VERSION ""

NS_ :

BS_:

BU_: ETH

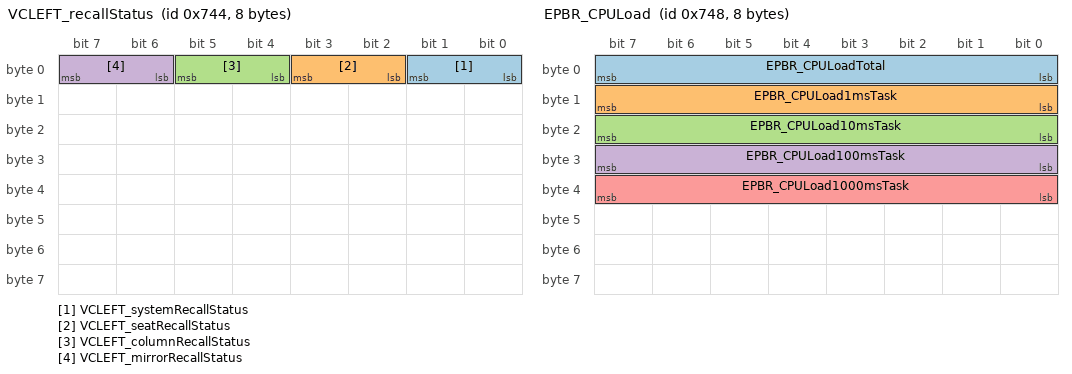
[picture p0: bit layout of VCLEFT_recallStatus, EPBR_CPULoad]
BO_ 1860 VCLEFT_recallStatus: 8 Vector__XXX
 SG_ VCLEFT_systemRecallStatus : 0|2@1+ (1,0) [0|0] "" Vector__XXX
 SG_ VCLEFT_seatRecallStatus : 2|2@1+ (1,0) [0|0] "" Vector__XXX
 SG_ VCLEFT_columnRecallStatus : 4|2@1+ (1,0) [0|0] "" Vector__XXX
 SG_ VCLEFT_mirrorRecallStatus : 6|2@1+ (1,0) [0|0] "" Vector__XXX

BO_ 1863 DBG_vdcControl: 8 Vector__XXX
 SG_ DBG_vdcDebugEnable : 0|1@1+ (1,0) [0|0] "" Vector__XXX

BO_ 1864 EPBR_CPULoad: 8 Vector__XXX
 SG_ EPBR_CPULoadTotal : 0|8@1+ (1,0) [0|0] "" Vector__XXX
 SG_ EPBR_CPULoad1msTask : 8|8@1+ (1,0) [0|0] "" Vector__XXX
 SG_ EPBR_CPULoad10msTask : 16|8@1+ (1,0) [0|0] "" Vector__XXX
 SG_ EPBR_CPULoad100msTask : 24|8@1+ (1,0) [0|0] "" Vector__XXX
 SG_ EPBR_CPULoad1000msTask : 32|8@1+ (1,0) [0|0] "" Vector__XXX

BO_ 1870 XCP_pmRequest: 8 Vector__XXX
 SG_ XCP_pmRequestData : 7|64@0+ (1,0) [0|0] "" Vector__XXX

BO_ 1871 PM_xcpResponse: 8 Vector__XXX
 SG_ PM_xcpResponseData : 7|64@0+ (1,0) [0|0] "" Vector__XXX

BO_ 1872 XCP_vcbattRequest: 8 Vector__XXX
 SG_ XCP_vcbattRequestData : 0|64@1+ (1,0) [0|0] "" Vector__XXX

BO_ 1873 XCP_vcbatt1Request: 8 Vector__XXX
 SG_ XCP_vcbatt1RequestData : 0|64@1+ (1,0) [0|0] "" Vector__XXX

BO_ 1874 BMS_debugInfo_100Hz: 8 Vector__XXX
 SG_ BMS_100HzDebug_Id M : 0|6@1+ (1,0) [0|0] "" Vector__XXX
 SG_ BMS_dbgLoadReg_output m2 : 6|11@1- (0.1,0) [0|0] "" Vector__XXX
 SG_ BMS_dbgSmWeldRequest m3 : 6|1@1+ (1,0) [0|0] "" Vector__XXX
 SG_ BMS_energyVoltageFloorReached m4 : 6|1@1+ (1,0) [0|0] "" Vector__XXX
 SG_ BMS_dbgSmChgModuleBlockingTrans m3 : 7|1@1+ (1,0) [0|0] "" Vector__XXX
 SG_ BMS_energyPowerTargetReached m4 : 7|1@1+ (1,0) [0|0] "" Vector__XXX
 SG_ BMS_brickOcvAvg m9 : 8|12@1+ (0.002,0) [0|0] "" Vector__XXX
 SG_ BMS_dbgCurrentReg_outIntegral m1 : 8|14@1- (0.1,0) [0|0] "" Vector__XXX
 SG_ BMS_dbgHvsTxErrorCount m6 : 8|8@1+ (1,0) [0|0] "" Vector__XXX
 SG_ BMS_dbgSmChargeCablePresent m3 : 8|1@1+ (1,0) [0|0] "" Vector__XXX
 SG_ BMS_dbgVoltageReg_Kp m0 : 8|9@1+ (5,0) [0|0] "" Vector__XXX
 SG_ BMS_energySimulationWalk m11 : 8|3@1+ (1,0) [0|0] "" Vector__XXX
 SG_ BMS_energySimulationWalkTime m10 : 8|14@1+ (0.1,0) [0|0] "" Vector__XXX
 SG_ BMS_energyWalkDone m4 : 8|1@1+ (1,0) [0|0] "" Vector__XXX
 SG_ BMS_energyWalkLoadedPackV m5 : 8|9@1+ (1,0) [0|0] "" Vector__XXX
 SG_ BMS_maxDeviationBrickId m12 : 8|8@1+ (1,1) [0|0] "" Vector__XXX
 SG_ BMS_measuredImpedanceNoise m13 : 8|12@1+ (0.001,0) [0|0] "" Vector__XXX
 SG_ BMS_socByDvStartPtInitialized m7 : 8|1@1+ (1,0) [0|0] "" Vector__XXX
 SG_ BMS_voltageInstabilityPresent m8 : 8|1@1+ (1,0) [0|0] "" Vector__XXX
 SG_ BMS_dbgSmChargeRequestActive m3 : 9|1@1+ (1,0) [0|0] "" Vector__XXX
 SG_ BMS_energySocLimitReached m4 : 9|1@1+ (1,0) [0|0] "" Vector__XXX
 SG_ BMS_socByDvStartCcv m7 : 9|12@1+ (0.002,0) [0|0] "" Vector__XXX
 SG_ BMS_voltageInstabilityFiltMedianCnts m8 : 9|12@1+ (0.1,0) [0|0] "" Vector__XXX
 SG_ BMS_dbgSmChargerActive m3 : 10|1@1+ (1,0) [0|0] "" Vector__XXX
 SG_ BMS_energyNotEnoughPower m4 : 10|1@1+ (1,0) [0|0] "" Vector__XXX
 SG_ BMS_dbgSmBmsWantsToCharge m3 : 11|1@1+ (1,0) [0|0] "" Vector__XXX
 SG_ BMS_energyTargetReached m4 : 11|1@1+ (1,0) [0|0] "" Vector__XXX
 SG_ BMS_dbgChargeState m3 : 12|4@1+ (1,0) [0|0] "" Vector__XXX
 SG_ BMS_energyWalkTimedOut m4 : 12|1@1+ (1,0) [0|0] "" Vector__XXX
 SG_ BMS_energyWalkId m4 : 13|3@1+ (1,0) [0|0] "" Vector__XXX
 SG_ BMS_dbgChargeNeeded m3 : 16|1@1+ (1,0) [0|0] "" Vector__XXX
 SG_ BMS_dbgHvsRxErrorCount m6 : 16|8@1+ (1,0) [0|0] "" Vector__XXX
 SG_ BMS_energyWalkTime m4 : 16|10@1+ (0.01,0) [0|0] "" Vector__XXX
 SG_ BMS_maxDeviationBrickImpedance m12 : 16|12@1+ (0.01,0) [0|0] "" Vector__XXX
 SG_ BMS_dbgOffsetReg_output m2 : 17|14@1- (0.1,0) [0|0] "" Vector__XXX
 SG_ BMS_dbgSmStateSupportRequired m3 : 17|1@1+ (1,0) [0|0] "" Vector__XXX
 SG_ BMS_dbgVoltageReg_Ki m0 : 17|11@1+ (1,0) [0|0] "" Vector__XXX
 SG_ BMS_energyWalkPackCurrent m5 : 17|15@1- (0.1,1000) [0|0] "" Vector__XXX
 SG_ BMS_dbgSmDriveActive m3 : 18|1@1+ (1,0) [0|0] "" Vector__XXX
 SG_ BMS_dbgFeimBlocking m3 : 19|1@1+ (1,0) [0|0] "" Vector__XXX
 SG_ BMS_brickOcvMax m9 : 20|12@1+ (0.002,0) [0|0] "" Vector__XXX
 SG_ BMS_dbgUdsCtrControlActive m3 : 20|1@1+ (1,0) [0|0] "" Vector__XXX
 SG_ BMS_normalizedDcrNoise m13 : 20|10@1+ (0.001,0) [0|0] "" Vector__XXX
 SG_ BMS_dbgEnoughPowerForSupport m3 : 21|1@1+ (1,0) [0|0] "" Vector__XXX
 SG_ BMS_socByDvStartCurrent m7 : 21|10@1- (1,0) [0|0] "" Vector__XXX
 SG_ BMS_voltageDiffPerSMax m8 : 21|11@1+ (0.00244140625,-2.5) [0|0] "" Vector__XXX
 SG_ BMS_chargeEnergyPackCurrent m10 : 24|13@1- (1,1000) [0|0] "" Vector__XXX
 SG_ BMS_dbgCurrentReg_outProp m1 : 24|14@1- (0.1,0) [0|0] "" Vector__XXX
 SG_ BMS_dbgHvsFaultConfinement m6 : 24|2@1+ (1,0) [0|0] "" Vector__XXX
 SG_ BMS_fcLinkLeakageTestStatus m3 : 24|3@1+ (1,0) [0|0] "" Vector__XXX
 SG_ BMS_dbgHvsBusIsOff m6 : 26|1@1+ (1,0) [0|0] "" Vector__XXX
 SG_ BMS_walkEnergy m4 : 26|11@1+ (0.1,0) [0|0] "" Vector__XXX
 SG_ BMS_dbgHvsGoToSleep m6 : 27|1@1+ (1,0) [0|0] "" Vector__XXX
 SG_ BMS_minTetheredLoadPresent m3 : 27|1@1+ (1,0) [0|0] "" Vector__XXX
 SG_ BMS_avgBrickImpedance m12 : 28|12@1+ (0.01,0) [0|0] "" Vector__XXX
 SG_ BMS_dbgVoltageReg_error m0 : 28|12@1- (0.00122,0) [0|0] "" Vector__XXX
 SG_ BMS_smHvUpRequestAllowed m3 : 28|1@1+ (1,0) [0|0] "" Vector__XXX
 SG_ BMS_fcCtrCleaningDesired m3 : 29|1@1+ (1,0) [0|0] "" Vector__XXX
 SG_ BMS_fcCtrCleaningAllowed m3 : 30|1@1+ (1,0) [0|0] "" Vector__XXX
 SG_ BMS_rawImpedanceDeviation m13 : 30|10@1+ (0.001,0) [0|0] "" Vector__XXX
 SG_ BMS_fcCtrCleaningActive m3 : 31|1@1+ (1,0) [0|0] "" Vector__XXX
 SG_ BMS_socByDvNetAh m7 : 31|9@1+ (0.002,0) [0|0] "" Vector__XXX
 SG_ BMS_brickOcvMin m9 : 32|12@1+ (0.002,0) [0|0] "" Vector__XXX
 SG_ BMS_dbgChargeNeededState m2 : 32|3@1+ (1,0) [0|0] "" Vector__XXX
 SG_ BMS_dbgHviTxErrorCount m6 : 32|8@1+ (1,0) [0|0] "" Vector__XXX
 SG_ BMS_energyWalkPackResistance m5 : 32|10@1+ (0.1,0) [0|0] "" Vector__XXX
 SG_ BMS_fcCtrCleaningPosCount m3 : 32|6@1+ (1,0) [0|0] "" Vector__XXX
 SG_ BMS_voltageInstabilityFltExcessNoise m8 : 32|12@1+ (0.1,0) [0|0] "" Vector__XXX
 SG_ BMS_dbgMaxDcCurrentAvailable m2 : 35|11@1+ (0.5,0) [0|0] "" Vector__XXX
 SG_ BMS_energyMaxBrickTemp m10 : 37|9@1+ (0.25,-25) [0|0] "" Vector__XXX
 SG_ BMS_energyWalkAhRemaining m4 : 37|12@1+ (0.1,0) [0|0] "" Vector__XXX
 SG_ BMS_dbgCurrentReg_error m1 : 40|12@1- (0.1,0) [0|0] "" Vector__XXX
 SG_ BMS_dbgHviRxErrorCount m6 : 40|8@1+ (1,0) [0|0] "" Vector__XXX
 SG_ BMS_dbgPeakRegenCurrentLimitMode m7 : 40|4@1+ (1,0) [0|0] "" Vector__XXX
 SG_ BMS_dbgVoltageReg_output m0 : 40|12@1- (0.5,0) [0|0] "" Vector__XXX
 SG_ BMS_fcCtrCleaningNegCount m3 : 40|6@1+ (1,0) [0|0] "" Vector__XXX
 SG_ BMS_missingCellExcessCurrentGain m13 : 40|8@1+ (0.05,0) [0|0] "" Vector__XXX
 SG_ BMS_snapshot1MaxVoltage m12 : 40|10@1+ (0.005,0) [0|0] "" Vector__XXX
 SG_ BMS_brickOcvSum m9 : 44|10@1+ (0.5,0) [0|0] "" Vector__XXX
 SG_ BMS_dbgDischargeCurrentLimitMode m7 : 44|4@1+ (1,0) [0|0] "" Vector__XXX
 SG_ BMS_voltageInstabilityMaxRawCnts m8 : 44|12@1+ (1,0) [0|0] "" Vector__XXX
 SG_ BMS_brickVoltagesClean m3 : 46|1@1+ (1,0) [0|0] "" Vector__XXX
 SG_ BMS_dbgCurrentReg_targetI m2 : 46|11@1+ (0.5,0) [0|0] "" Vector__XXX
 SG_ BMS_energyMinBrickTemp m10 : 46|9@1+ (0.25,-25) [0|0] "" Vector__XXX
 SG_ BMS_chargeSourcePresent m3 : 47|1@1+ (1,0) [0|0] "" Vector__XXX
 SG_ BMS_dbgHviFaultConfinement m6 : 48|2@1+ (1,0) [0|0] "" Vector__XXX
 SG_ BMS_energyWalkPackTemp m5 : 48|8@1- (1,40) [0|0] "" Vector__XXX
 SG_ BMS_missingCellImpedanceDeviation m13 : 48|10@1+ (0.001,0) [0|0] "" Vector__XXX
 SG_ BMS_energyWalkPackSoc m4 : 49|10@1+ (0.1,0) [0|0] "" Vector__XXX
 SG_ BMS_dbgHviBusIsOff m6 : 50|1@1+ (1,0) [0|0] "" Vector__XXX
 SG_ BMS_impedanceDevDeltaCurrent m12 : 50|12@1+ (1,-3000) [0|0] "" Vector__XXX
 SG_ BMS_instantPowerDissipation m9 : 54|10@1+ (0.25,0) [0|0] "" Vector__XXX
 SG_ BMS_energyCoolantOutletTemp m10 : 56|8@1+ (1,-50) [0|0] "" Vector__XXX
 SG_ BMS_voltageInstabilityMaxBrickVNumber m8 : 56|7@1+ (1,0) [0|0] "" Vector__XXX
 SG_ BMS_dbgCpUserChargeStatus m2 : 57|3@1+ (1,0) [0|0] "" Vector__XXX
 SG_ BMS_energyCounter m4 : 59|4@1+ (1,0) [0|0] "" Vector__XXX

BO_ 1875 XCP_vcrightRequest: 8 Vector__XXX
 SG_ XCP_vcrightRequestData : 7|64@0+ (1,0) [0|0] "" Vector__XXX

BO_ 1876 XCP_vcfrontRequest: 8 Vector__XXX
 SG_ XCP_vcfrontRequestData : 7|64@0+ (1,0) [0|0] "" Vector__XXX

BO_ 1877 XCP_vcsecRequest: 8 Vector__XXX
 SG_ XCP_vcsecRequestData : 7|64@0+ (1,0) [0|0] "" Vector__XXX

BO_ 1878 XCP_vcleftRequest: 8 Vector__XXX
 SG_ XCP_vcleftRequestData : 7|64@0+ (1,0) [0|0] "" Vector__XXX

BO_ 1879 DIF_debug: 8 Vector__XXX
 SG_ DIF_debugSelector M : 0|8@1+ (1,0) [0|0] "" Vector__XXX
 SG_ DIF_cpu10HzMin m66 : 8|8@1+ (0.4,0) [0|0] "" Vector__XXX
 SG_ DIF_cpu1HzMin m128 : 8|8@1+ (0.4,0) [0|0] "" Vector__XXX
 SG_ DIF_cpu1kHzMin m67 : 8|8@1+ (0.4,0) [0|0] "" Vector__XXX
 SG_ DIF_dcCapTemp m64 : 8|8@1+ (1,-40) [0|0] "" Vector__XXX
 SG_ DIF_gainScale m37 : 8|8@1+ (0.01,0) [0|0] "" Vector__XXX
 SG_ DIF_hwFaultCount m69 : 8|4@1+ (1,0) [0|0] "" Vector__XXX
 SG_ DIF_latchFeedback m50 : 8|1@1+ (1,0) [0|0] "" Vector__XXX
 SG_ DIF_lmScale m36 : 8|8@1+ (0.004,0) [0|0] "" Vector__XXX
 SG_ DIF_motorIA m32 : 8|16@1+ (0.1,0) [0|0] "" Vector__XXX
 SG_ DIF_offsetA m44 : 8|6@1- (0.763,0) [0|0] "" Vector__XXX
 SG_ DIF_oilPumpMotorSpeed m46 : 8|8@1+ (40,0) [0|0] "" Vector__XXX
 SG_ DIF_phaseOutBusbarTemp m70 : 8|8@1+ (1,-40) [0|0] "" Vector__XXX
 SG_ DIF_resolverOffsetCos m48 : 8|8@1+ (0.015,0) [0|0] "" Vector__XXX
 SG_ DIF_rotorOffsetEst m43 : 8|12@1- (0.01,0) [0|0] "" Vector__XXX
 SG_ DIF_rsScale m34 : 8|8@1+ (0.01,0) [0|0] "" Vector__XXX
 SG_ DIF_soptTimeToTrip m49 : 8|8@1+ (0.05,0) [0|0] "" Vector__XXX
 SG_ DIF_statorEndWindingTemp m72 : 8|8@1+ (1,-40) [0|0] "" Vector__XXX
 SG_ DIF_statorIDref m33 : 8|16@1- (0.1,0) [0|0] "" Vector__XXX
 SG_ DIF_systemStack m68 : 8|8@1+ (0.4,0) [0|0] "" Vector__XXX
 SG_ DIF_tqSatThermal m39 : 8|8@1+ (0.4,0) [0|0] "" Vector__XXX
 SG_ DIF_tqScaleDifferential m35 : 8|8@1+ (0.4,0) [0|0] "" Vector__XXX
 SG_ DIF_mechssLatchesActive m50 : 9|1@1+ (1,0) [0|0] "" Vector__XXX
 SG_ DIF_usmState m38 : 12|3@1+ (1,0) [0|0] "" Vector__XXX
 SG_ DIF_busbarTemp m64 : 16|8@1+ (1,-40) [0|0] "" Vector__XXX
 SG_ DIF_cpu10HzAvg m66 : 16|8@1+ (0.4,0) [0|0] "" Vector__XXX
 SG_ DIF_cpu1HzAvg m128 : 16|8@1+ (0.4,0) [0|0] "" Vector__XXX
 SG_ DIF_cpu1kHzAvg m67 : 16|8@1+ (0.4,0) [0|0] "" Vector__XXX
 SG_ DIF_cpuIDWord0 m131 : 16|16@1+ (1,0) [0|0] "" Vector__XXX
 SG_ DIF_cpuIDWord1 m132 : 16|16@1+ (1,0) [0|0] "" Vector__XXX
 SG_ DIF_idleStack m68 : 16|8@1+ (0.4,0) [0|0] "" Vector__XXX
 SG_ DIF_lvBoostedRail m50 : 16|8@1+ (0.08,0) [0|0] "" Vector__XXX
 SG_ DIF_offsetB m44 : 16|6@1- (0.763,0) [0|0] "" Vector__XXX
 SG_ DIF_oilPumpPhaseVoltage m46 : 16|8@1+ (0.3,0) [0|0] "" Vector__XXX
 SG_ DIF_peakIQref m38 : 16|16@1+ (0.1,0) [0|0] "" Vector__XXX
 SG_ DIF_phaseOutBusbarWeldTemp m70 : 16|8@1+ (1,-40) [0|0] "" Vector__XXX
 SG_ DIF_resolverCosRmsSquared m52 : 16|8@1+ (0.005,0) [0|0] "" Vector__XXX
 SG_ DIF_resolverOffsetSin m48 : 16|8@1+ (0.015,0) [0|0] "" Vector__XXX
 SG_ DIF_rotorFlux m47 : 16|16@1+ (0.0001,0) [0|0] "" Vector__XXX
 SG_ DIF_rotorMaxMagnetTemp m72 : 16|8@1+ (1,-40) [0|0] "" Vector__XXX
 SG_ DIF_soptTripDelay m49 : 16|8@1+ (0.05,0) [0|0] "" Vector__XXX
 SG_ DIF_statorFluxRef m35 : 16|16@1+ (0.0001,0) [0|0] "" Vector__XXX
 SG_ DIF_statorIQref m34 : 16|16@1- (0.1,0) [0|0] "" Vector__XXX
 SG_ DIF_statorVDFiltered m63 : 16|16@1- (4e-05,0) [0|0] "" Vector__XXX
 SG_ DIF_statorVQ m36 : 16|16@1- (4e-05,0) [0|0] "" Vector__XXX
 SG_ DIF_tcMaxRequest m40 : 16|8@1+ (5,0) [0|0] "" Vector__XXX
 SG_ DIF_rotorOffsetMean m43 : 20|12@1- (0.01,0) [0|0] "" Vector__XXX
 SG_ DIF_activeDischargeRail m50 : 24|8@1+ (0.3,0) [0|0] "" Vector__XXX
 SG_ DIF_cpu100HzMin m66 : 24|8@1+ (0.4,0) [0|0] "" Vector__XXX
 SG_ DIF_cpu20kHzMin m67 : 24|8@1+ (0.4,0) [0|0] "" Vector__XXX
 SG_ DIF_decodeHardwareStack m68 : 24|8@1+ (0.4,0) [0|0] "" Vector__XXX
 SG_ DIF_lightSenseV m72 : 24|6@1+ (0.1,0) [0|0] "" Vector__XXX
 SG_ DIF_llsScale m42 : 24|8@1+ (0.004,0) [0|0] "" Vector__XXX
 SG_ DIF_motorIB m32 : 24|16@1+ (0.1,0) [0|0] "" Vector__XXX
 SG_ DIF_oilPumpPressureEstimateMax m46 : 24|8@1+ (2,0) [0|0] "" Vector__XXX
 SG_ DIF_pcsTemp m64 : 24|8@1+ (1,-40) [0|0] "" Vector__XXX
 SG_ DIF_phaseOutLugTemp m70 : 24|8@1+ (1,-40) [0|0] "" Vector__XXX
 SG_ DIF_resolverPhaseOffset m48 : 24|8@1+ (0.4,0) [0|0] "" Vector__XXX
 SG_ DIF_resolverSinRmsSquared m52 : 24|8@1+ (0.005,0) [0|0] "" Vector__XXX
 SG_ DIF_soptTimeToOff m49 : 24|11@1+ (0.05,0) [0|0] "" Vector__XXX
 SG_ DIF_statorIDfdb m33 : 24|16@1- (0.1,0) [0|0] "" Vector__XXX
 SG_ DIF_tcMinRequest m40 : 24|8@1+ (5,0) [0|0] "" Vector__XXX
 SG_ DIF_pyroSenseV m72 : 30|8@1+ (0.02,0) [0|0] "" Vector__XXX
 SG_ DIF_cpu100HzAvg m66 : 32|8@1+ (0.4,0) [0|0] "" Vector__XXX
 SG_ DIF_cpu20kHzAvg m67 : 32|8@1+ (0.4,0) [0|0] "" Vector__XXX
 SG_ DIF_cpuIDWord2 m132 : 32|16@1+ (1,0) [0|0] "" Vector__XXX
 SG_ DIF_crc m131 : 32|32@1+ (1,0) [0|0] "" Vector__XXX
 SG_ DIF_dcCableHeat m47 : 32|16@1+ (0.001,0) [0|0] "" Vector__XXX
 SG_ DIF_dcLinkCapTemp m70 : 32|8@1+ (1,-40) [0|0] "" Vector__XXX
 SG_ DIF_driveUnitOdometer m69 : 32|32@1+ (10,0) [0|0] "" Vector__XXX
 SG_ DIF_eepromStack m68 : 32|8@1+ (0.4,0) [0|0] "" Vector__XXX
 SG_ DIF_llrScale m42 : 32|8@1+ (0.015,0) [0|0] "" Vector__XXX
 SG_ DIF_loadAngleMargin m37 : 32|16@1- (0.0003,0) [0|0] "" Vector__XXX
 SG_ DIF_motorIAavg m38 : 32|16@1- (0.1,0) [0|0] "" Vector__XXX
 SG_ DIF_oilPumpPressureExpectedMin m46 : 32|8@1+ (2,0) [0|0] "" Vector__XXX
 SG_ DIF_preregulatorRail m50 : 32|8@1+ (0.15,0) [0|0] "" Vector__XXX
 SG_ DIF_resolverCommonGain m48 : 32|8@1+ (0.025,0) [0|0] "" Vector__XXX
 SG_ DIF_resolverCosFiltered m52 : 32|8@1- (0.01,0) [0|0] "" Vector__XXX
 SG_ DIF_statorFluxFdb m35 : 32|16@1+ (0.0001,0) [0|0] "" Vector__XXX
 SG_ DIF_statorIQfdb m34 : 32|16@1- (0.1,0) [0|0] "" Vector__XXX
 SG_ DIF_statorTemp1 m64 : 32|8@1+ (1,-40) [0|0] "" Vector__XXX
 SG_ DIF_statorVD m36 : 32|16@1- (4e-05,0) [0|0] "" Vector__XXX
 SG_ DIF_statorVQFiltered m63 : 32|16@1- (4e-05,0) [0|0] "" Vector__XXX
 SG_ DIF_tqSatMotorVoltage m39 : 32|8@1+ (0.4,0) [0|0] "" Vector__XXX
 SG_ DIF_wasteCurrentLimit m41 : 32|16@1+ (0.1,0) [0|0] "" Vector__XXX
 SG_ DIF_controlStack m67 : 40|8@1+ (0.4,0) [0|0] "" Vector__XXX
 SG_ DIF_cpu10msMin m66 : 40|8@1+ (0.4,0) [0|0] "" Vector__XXX
 SG_ DIF_hvDcCableTemp m70 : 40|8@1+ (1,-40) [0|0] "" Vector__XXX
 SG_ DIF_loadAngle m42 : 40|16@1- (0.0003,0) [0|0] "" Vector__XXX
 SG_ DIF_motorIC m32 : 40|16@1+ (0.1,0) [0|0] "" Vector__XXX
 SG_ DIF_resolverReady m48 : 40|1@1+ (1,0) [0|0] "" Vector__XXX
 SG_ DIF_resolverSinFiltered m52 : 40|8@1- (0.01,0) [0|0] "" Vector__XXX
 SG_ DIF_soptMaxCurrentMagSqrd m49 : 40|16@1+ (100,0) [0|0] "" Vector__XXX
 SG_ DIF_statorTemp2 m64 : 40|8@1+ (1,-40) [0|0] "" Vector__XXX
 SG_ DIF_torquePerAmp m33 : 40|16@1+ (0.0001,0) [0|0] "" Vector__XXX
 SG_ DIF_tqSatMotorCurrent m39 : 40|8@1+ (0.4,0) [0|0] "" Vector__XXX
 SG_ DIF_udsStack m68 : 40|8@1+ (0.4,0) [0|0] "" Vector__XXX
 SG_ DIF_resolverNoCarrier m48 : 41|1@1+ (1,0) [0|0] "" Vector__XXX
 SG_ DIF_resolverNoPhaseLock m48 : 42|1@1+ (1,0) [0|0] "" Vector__XXX
 SG_ DIF_resolverClaMIA m48 : 43|1@1+ (1,0) [0|0] "" Vector__XXX
 SG_ DIF_statorSlotWindingTemp m72 : 46|8@1+ (1,-40) [0|0] "" Vector__XXX
 SG_ DIF_cpuIDWord3 m132 : 48|16@1+ (1,0) [0|0] "" Vector__XXX
 SG_ DIF_internalAngleFilt m37 : 48|16@1+ (0.0003,0) [0|0] "" Vector__XXX
 SG_ DIF_magnetTempEst m47 : 48|8@1+ (1,-40) [0|0] "" Vector__XXX
 SG_ DIF_module10HzStack m66 : 48|8@1+ (0.4,0) [0|0] "" Vector__XXX
 SG_ DIF_motorIBavg m38 : 48|16@1- (0.1,0) [0|0] "" Vector__XXX
 SG_ DIF_motorV m34 : 48|16@1+ (2e-05,0) [0|0] "" Vector__XXX
 SG_ DIF_negDcBusbarTemp m70 : 48|8@1+ (1,-40) [0|0] "" Vector__XXX
 SG_ DIF_peakFlux m36 : 48|16@1+ (0.0001,0) [0|0] "" Vector__XXX
 SG_ DIF_phaseImbalanceFactor m35 : 48|16@1+ (0.0001,0) [0|0] "" Vector__XXX
 SG_ DIF_pwmState m63 : 48|2@1+ (1,0) [0|0] "" Vector__XXX
 SG_ DIF_resolverErrorRmsSquared m52 : 48|8@1+ (0.005,0) [0|0] "" Vector__XXX
 SG_ DIF_tqScaleMaxMotorSpeed m40 : 48|8@1+ (0.4,0) [0|0] "" Vector__XXX
 SG_ DIF_xcpStack m68 : 48|8@1+ (0.4,0) [0|0] "" Vector__XXX
 SG_ DIF_intervalMaxHvBusV m72 : 54|10@1+ (1,0) [0|0] "" Vector__XXX
 SG_ DIF_immobilizerStack m68 : 56|8@1+ (0.4,0) [0|0] "" Vector__XXX
 SG_ DIF_posDcBusbarTemp m70 : 56|8@1+ (1,-40) [0|0] "" Vector__XXX

BO_ 1881 XCP_vcfront1Request: 8 Vector__XXX
 SG_ XCP_vcfront1RequestData : 0|64@1+ (1,0) [0|0] "" Vector__XXX

BO_ 1882 XCP_vcfront2Request: 8 Vector__XXX
 SG_ XCP_vcfront2RequestData : 0|64@1+ (1,0) [0|0] "" Vector__XXX

BO_ 1883 XCP_vcbatt2Request: 8 Vector__XXX
 SG_ XCP_vcbatt2RequestData : 0|64@1+ (1,0) [0|0] "" Vector__XXX

BO_ 1885 CP_loggingFast: 8 Vector__XXX
 SG_ CP_loggingFastSelect M : 0|4@1+ (1,0) [0|0] "" Vector__XXX
 SG_ CP_UHF_controlState m2 : 4|4@1+ (1,0) [0|0] "" Vector__XXX
 SG_ CP_doorPresenceSensorV m3 : 4|12@1+ (0.001221,0) [0|0] "" Vector__XXX
 SG_ CP_inductiveSensor_raw m0 : 4|28@1+ (1,0) [0|0] "" Vector__XXX
 SG_ CP_latchLastEngageRequestMaxV m4 : 4|10@1+ (0.017595307917888565,0) [0|0] "" Vector__XXX
 SG_ CP_latchPot m1 : 4|12@1+ (0.025,0) [0|0] "" Vector__XXX
 SG_ CP_v2xState m5 : 4|3@1+ (1,0) [0|0] "" Vector__XXX
 SG_ CP_proximityV m2 : 8|16@1+ (0.0001,0) [0|0] "" Vector__XXX
 SG_ CP_v2xCommsState m5 : 8|3@1+ (1,0) [0|0] "" Vector__XXX
 SG_ CP_v2xRetryAttempts m5 : 11|4@1+ (1,0) [0|0] "" Vector__XXX
 SG_ CP_latchLastEngageRequestMaxI m4 : 14|10@1+ (0.004887585532746823,0) [0|0] "" Vector__XXX
 SG_ CP_activeV2xBlocker m5 : 16|5@1+ (1,0) [0|0] "" Vector__XXX
 SG_ CP_doorLastRequestMaxI m1 : 16|12@1+ (0.0025,0) [0|0] "" Vector__XXX
 SG_ CP_doorOpenRequest m3 : 16|4@1+ (1,0) [0|0] "" Vector__XXX
 SG_ CP_doorOpenEndOfDriveReason m3 : 20|3@1+ (1,0) [0|0] "" Vector__XXX
 SG_ CP_lastV2xShutdownTrigger m5 : 21|5@1+ (1,0) [0|0] "" Vector__XXX
 SG_ CP_coverClosed m3 : 23|1@1+ (1,0) [0|0] "" Vector__XXX
 SG_ CP_doorCloseEndOfDriveReason m3 : 24|3@1+ (1,0) [0|0] "" Vector__XXX
 SG_ CP_latchLastDisengageRequestMaxV m4 : 24|10@1+ (0.017595307917888565,0) [0|0] "" Vector__XXX
 SG_ CP_proximityV_GBCC1 m2 : 24|14@1+ (0.001,0) [0|0] "" Vector__XXX
 SG_ CP_doorCloseRequest m3 : 27|5@1+ (1,0) [0|0] "" Vector__XXX
 SG_ CP_doorLastRequestMaxV m1 : 28|10@1+ (0.017595307917888565,0) [0|0] "" Vector__XXX
 SG_ CP_doorOpenActuationTime m0 : 32|14@1+ (1,0) [0|0] "" Vector__XXX
 SG_ CP_latchDisengagingTime m3 : 32|10@1+ (1,0) [0|0] "" Vector__XXX
 SG_ CP_latchLastDisengageRequestMaxI m4 : 34|10@1+ (0.004887585532746823,0) [0|0] "" Vector__XXX
 SG_ CP_digitalCommsAttempts m5 : 37|3@1+ (1,0) [0|0] "" Vector__XXX
 SG_ CP_pilotPulseWidth m1 : 38|12@1+ (1,0) [0|0] "" Vector__XXX
 SG_ CP_proximityV_GBCC2 m2 : 38|14@1+ (0.001,0) [0|0] "" Vector__XXX
 SG_ CP_evseGridFormRequestVersion m5 : 40|2@1+ (1,0) [0|0] "" Vector__XXX
 SG_ CP_evseGridFormState m5 : 42|3@1+ (1,0) [0|0] "" Vector__XXX
 SG_ CP_latchEngagingTime m3 : 42|10@1+ (1,0) [0|0] "" Vector__XXX
 SG_ CP_latchLastEngageMaxVelocity m4 : 44|10@1- (8.013698630136986,0) [0|0] "" Vector__XXX
 SG_ CP_evsePilotPowerNeeded m5 : 45|1@1+ (1,0) [0|0] "" Vector__XXX
 SG_ CP_doorCloseActuationTime m0 : 46|14@1+ (1,0) [0|0] "" Vector__XXX
 SG_ CP_v2xAccessoryUpdateWithoutExternalPower m5 : 46|1@1+ (1,0) [0|0] "" Vector__XXX
 SG_ CP_doorPotObserverEstimated m5 : 47|12@1+ (0.025,0) [0|0] "" Vector__XXX
 SG_ CP_pilotPeriod m1 : 50|12@1+ (1,0) [0|0] "" Vector__XXX
 SG_ CP_doorPot m2 : 52|12@1+ (0.025,0) [0|0] "" Vector__XXX
 SG_ CP_latchDisengagingStopReason m3 : 52|3@1+ (1,0) [0|0] "" Vector__XXX
 SG_ CP_latchLastDisengageMaxVelocity m4 : 54|10@1- (8.013698630136986,0) [0|0] "" Vector__XXX
 SG_ CP_latchEngagingStopReason m3 : 56|3@1+ (1,0) [0|0] "" Vector__XXX
 SG_ CP_doorObserverEstimationIsActive m5 : 59|1@1+ (1,0) [0|0] "" Vector__XXX
 SG_ CP_pilotUnlatchRequestActive m3 : 59|1@1+ (1,0) [0|0] "" Vector__XXX
 SG_ CP_chargeCableSecured m0 : 60|1@1+ (1,0) [0|0] "" Vector__XXX
 SG_ CP_doorIdDetectionState m3 : 60|2@1+ (1,0) [0|0] "" Vector__XXX
 SG_ CP_doorPositionSource m5 : 60|2@1+ (1,0) [0|0] "" Vector__XXX
 SG_ CP_chargeCablePresent m0 : 61|1@1+ (1,0) [0|0] "" Vector__XXX
 SG_ CP_doorIdDetectedBin m3 : 62|2@1+ (1,0) [0|0] "" Vector__XXX
 SG_ CP_latchCheckAvailable m0 : 62|1@1+ (1,0) [0|0] "" Vector__XXX
 SG_ CP_proxConn1Sense m1 : 62|1@1+ (1,0) [0|0] "" Vector__XXX
 SG_ CP_proxEn m1 : 63|1@1+ (1,0) [0|0] "" Vector__XXX

BO_ 1886 CHADA_status_2: 8 Vector__XXX
 SG_ CA_status2DataSelect M : 0|7@1+ (1,0) [0|0] "" Vector__XXX
 SG_ CA_status2DummySig : 7|1@1+ (1,0) [0|0] "" Vector__XXX
 SG_ CA_EVSE_Ext_Avail_I_Out m4 : 8|16@1+ (1,0) [0|0] "" Vector__XXX
 SG_ CA_EVSE_Threshold_V m1 : 8|16@1+ (1,0) [0|0] "" Vector__XXX
 SG_ CA_VEH_Ext_Protocol_Ver m0 : 8|8@1+ (1,0) [0|0] "" Vector__XXX
 SG_ CA_vehConnTempDegC m2 : 8|16@1- (0.00457770657,0) [0|0] "" Vector__XXX
 SG_ CA_vehConnTempV m3 : 8|16@1+ (5.035477e-05,0) [0|0] "" Vector__XXX
 SG_ CA_EVSE_Ext_Protocol_Ver m0 : 16|8@1+ (1,0) [0|0] "" Vector__XXX
 SG_ CA_EVSE_Avail_V_Out m1 : 24|16@1+ (1,0) [0|0] "" Vector__XXX
 SG_ CA_EVSE_Eff_Avail_I_Out m4 : 24|16@1+ (1,0) [0|0] "" Vector__XXX
 SG_ CA_FC_protocolVersion m0 : 24|8@1+ (1,0) [0|0] "" Vector__XXX
 SG_ CA_evseConnTempDegC m2 : 24|16@1- (0.00457770657,0) [0|0] "" Vector__XXX
 SG_ CA_evseConnTempV m3 : 24|16@1+ (5.035477e-05,0) [0|0] "" Vector__XXX
 SG_ CA_BMS_protocolVersion m0 : 32|8@1+ (1,0) [0|0] "" Vector__XXX
 SG_ CA_EVSE_Avail_I_Out m1 : 40|8@1+ (1,0) [0|0] "" Vector__XXX
 SG_ CA_VEH_BAT_V_Target m0 : 40|16@1+ (1,0) [0|0] "" Vector__XXX
 SG_ CA_pcbaTempDegC m2 : 40|16@1- (0.01007110813,25) [0|0] "" Vector__XXX
 SG_ CA_pcbaTempV m3 : 40|16@1+ (5.035477e-05,0) [0|0] "" Vector__XXX
 SG_ CA_flybackVoltageLimit m1 : 48|16@1+ (0.01283327338,0) [0|0] "" Vector__XXX
 SG_ CA_VEH_BAT_SOC m0 : 56|8@1+ (0.39215686275,0) [0|0] "" Vector__XXX
 SG_ CA_disableVehicleLimiting m2 : 56|1@1+ (1,0) [0|0] "" Vector__XXX

BO_ 1889 PMF_debug: 8 Vector__XXX
 SG_ PMF_debugSelector M : 0|8@1+ (1,0) [0|0] "" Vector__XXX
 SG_ PMF_Ia m3 : 8|16@1- (0.0939,0) [0|0] "" Vector__XXX
 SG_ PMF_cpu100HzAvg m65 : 8|8@1+ (0.4,0) [0|0] "" Vector__XXX
 SG_ PMF_cpu10kHzMin m66 : 8|8@1+ (0.4,0) [0|0] "" Vector__XXX
 SG_ PMF_cpu1kHzMax m64 : 8|8@1+ (0.4,0) [0|0] "" Vector__XXX
 SG_ PMF_idleStackSize m67 : 8|16@1+ (1,0) [0|0] "" Vector__XXX
 SG_ PMF_offsetIa m5 : 8|12@1- (0.1,0) [0|0] "" Vector__XXX
 SG_ PMF_resolverPhaseAngle m17 : 8|9@1+ (0.001537,0) [0|0] "" Vector__XXX
 SG_ PMF_resolverSpeedError m16 : 8|16@1- (0.75,0) [0|0] "" Vector__XXX
 SG_ PMF_slipFrequency m4 : 8|16@1- (0.005,0) [0|0] "" Vector__XXX
 SG_ PMF_sysStackSize m70 : 8|16@1+ (1,0) [0|0] "" Vector__XXX
 SG_ PMF_torqueDecelWindow m2 : 8|13@1- (2,0) [0|0] "" Vector__XXX
 SG_ PMF_torqueSignError m1 : 8|13@1- (2,0) [0|0] "" Vector__XXX
 SG_ PMF_udsStackSize m68 : 8|16@1+ (1,0) [0|0] "" Vector__XXX
 SG_ PMF_xcpStackSize m69 : 8|16@1+ (1,0) [0|0] "" Vector__XXX
 SG_ PMF_cpu10HzMax m65 : 16|8@1+ (0.4,0) [0|0] "" Vector__XXX
 SG_ PMF_cpu20kHzAvg m64 : 16|8@1+ (0.4,0) [0|0] "" Vector__XXX
 SG_ PMF_resolverCommonGain m17 : 17|7@1+ (0.063,0) [0|0] "" Vector__XXX
 SG_ PMF_offsetIb m5 : 20|12@1- (0.1,0) [0|0] "" Vector__XXX
 SG_ PMF_Ib m3 : 24|16@1- (0.0939,0) [0|0] "" Vector__XXX
 SG_ PMF_cpu10HzAvg m65 : 24|8@1+ (0.4,0) [0|0] "" Vector__XXX
 SG_ PMF_cpu1kHzMin m64 : 24|8@1+ (0.4,0) [0|0] "" Vector__XXX
 SG_ PMF_idleStackMax m67 : 24|16@1+ (1,0) [0|0] "" Vector__XXX
 SG_ PMF_resolverExcitationGain m17 : 24|7@1+ (0.063,0) [0|0] "" Vector__XXX
 SG_ PMF_sysStackMax m70 : 24|16@1+ (1,0) [0|0] "" Vector__XXX
 SG_ PMF_torqueAccelWindow m1 : 24|13@1- (2,0) [0|0] "" Vector__XXX
 SG_ PMF_torqueDecelAvg m2 : 24|13@1- (2,0) [0|0] "" Vector__XXX
 SG_ PMF_udsStackMax m68 : 24|16@1+ (1,0) [0|0] "" Vector__XXX
 SG_ PMF_xcpStackMax m69 : 24|16@1+ (1,0) [0|0] "" Vector__XXX
 SG_ PMF_cpu10HzMin m65 : 32|8@1+ (0.4,0) [0|0] "" Vector__XXX
 SG_ PMF_cpu10kHzAvg m64 : 32|8@1+ (0.4,0) [0|0] "" Vector__XXX
 SG_ PMF_resolverOffsetCos m17 : 32|6@1+ (0.053,0) [0|0] "" Vector__XXX
 SG_ PMF_cpu100HzMax m64 : 40|8@1+ (0.4,0) [0|0] "" Vector__XXX
 SG_ PMF_cpu20kHzMax m65 : 40|8@1+ (0.4,0) [0|0] "" Vector__XXX
 SG_ PMF_iDQmagnitude m3 : 40|16@1- (0.0939,0) [0|0] "" Vector__XXX
 SG_ PMF_motorRPM m4 : 40|16@1- (1,0) [0|0] "" Vector__XXX
 SG_ PMF_resolverOffsetSin m17 : 40|6@1+ (0.053,0) [0|0] "" Vector__XXX
 SG_ PMF_torqueAccelAvg m1 : 40|13@1- (2,0) [0|0] "" Vector__XXX
 SG_ PMF_torqueReversalWindow m2 : 40|13@1- (2,0) [0|0] "" Vector__XXX
 SG_ PMF_switchingActive m5 : 46|1@1+ (1,0) [0|0] "" Vector__XXX
 SG_ PMF_torqueOutOfMap m5 : 47|1@1+ (1,0) [0|0] "" Vector__XXX
 SG_ PMF_cpu1kHzAvg m64 : 48|8@1+ (0.4,0) [0|0] "" Vector__XXX
 SG_ PMF_cpu20kHzMin m65 : 48|8@1+ (0.4,0) [0|0] "" Vector__XXX
 SG_ PMF_resolverOffsetExt m17 : 48|6@1+ (0.053,0) [0|0] "" Vector__XXX
 SG_ PMF_resolverNoCarrier m17 : 54|1@1+ (1,0) [0|0] "" Vector__XXX
 SG_ PMF_resolverPhaseOutOfSpec m17 : 55|1@1+ (1,0) [0|0] "" Vector__XXX
 SG_ PMF_cpu100HzMin m64 : 56|8@1+ (0.4,0) [0|0] "" Vector__XXX
 SG_ PMF_cpu10kHzMax m65 : 56|8@1+ (0.4,0) [0|0] "" Vector__XXX
 SG_ PMF_lmSatCoeff m3 : 56|8@1+ (0.00391,0) [0|0] "" Vector__XXX
 SG_ PMF_resolverClaMIA m17 : 56|1@1+ (1,0) [0|0] "" Vector__XXX
 SG_ PMF_statorT m4 : 56|8@1+ (1,-40) [0|0] "" Vector__XXX
 SG_ PMF_resolverDiMIA m17 : 57|1@1+ (1,0) [0|0] "" Vector__XXX

BO_ 1890 VCLEFT_xcpResponse: 8 Vector__XXX
 SG_ VCLEFT_xcpResponseData : 0|64@1+ (1,0) [0|0] "" Vector__XXX

BO_ 1891 VCRIGHT_xcpResponse: 8 Vector__XXX
 SG_ VCRIGHT_xcpResponseData : 0|64@1+ (1,0) [0|0] "" Vector__XXX

BO_ 1892 VCFRONT_xcpResponse: 8 Vector__XXX
 SG_ VCFRONT_xcpResponseData : 0|64@1+ (1,0) [0|0] "" Vector__XXX

BO_ 1894 DIF_dlogData: 8 Vector__XXX
 SG_ DIF_dlogData : 0|64@1+ (1,0) [0|0] "" Vector__XXX

BO_ 1896 VCBATT_xcpResponse: 8 Vector__XXX
 SG_ VCBATT_xcpResponseData : 0|64@1+ (1,0) [0|0] "" Vector__XXX

BO_ 1897 VCBATT1_xcpResponse: 8 Vector__XXX
 SG_ VCBATT1_xcpResponseData : 0|64@1+ (1,0) [0|0] "" Vector__XXX

BO_ 1898 VCFRONT1_xcpResponse: 8 Vector__XXX
 SG_ VCFRONT1_xcpResponseData : 0|64@1+ (1,0) [0|0] "" Vector__XXX

BO_ 1899 VCFRONT2_xcpResponse: 8 Vector__XXX
 SG_ VCFRONT2_xcpResponseData : 0|64@1+ (1,0) [0|0] "" Vector__XXX

BO_ 1904 VCBATT2_xcpResponse: 8 Vector__XXX
 SG_ VCBATT2_xcpResponseData : 0|64@1+ (1,0) [0|0] "" Vector__XXX

BO_ 1910 XCP_difRequest: 8 Vector__XXX
 SG_ XCP_difRequestData : 7|64@0+ (1,0) [0|0] "" Vector__XXX

BO_ 1911 XCP_diRequest: 8 Vector__XXX
 SG_ XCP_diRequestData : 7|64@0+ (1,0) [0|0] "" Vector__XXX

BO_ 1914 HVP_log1hz: 8 Vector__XXX
 SG_ HVP_log1HzIndex M : 0|3@1+ (1,0) [0|0] "" Vector__XXX
 SG_ HVP_bmbAsicType m0 : 3|2@1+ (1,0) [0|0] "" Vector__XXX
 SG_ HVP_hvilCalType m1 : 3|2@1+ (1,0) [0|0] "" Vector__XXX
 SG_ HVP_gpioPcsDcdcPwmEnable m1 : 5|1@1+ (1,0) [0|0] "" Vector__XXX
 SG_ HVP_gpioPcsChargePwmEnable m1 : 6|1@1+ (1,0) [0|0] "" Vector__XXX
 SG_ HVP_gpioPcsEnable m1 : 7|1@1+ (1,0) [0|0] "" Vector__XXX
 SG_ HVP_shuntAsicChipWaferNumber m1 : 8|8@1+ (1,0) [0|0] "" Vector__XXX
 SG_ HVP_shuntCurrentAuxLog m0 : 8|24@1- (0.001,0) [0|0] "" Vector__XXX
 SG_ HVP_energyReserveMin m1 : 16|16@1- (0.001,0) [0|0] "" Vector__XXX
 SG_ HVP_energyReserveMax m1 : 32|16@1- (0.001,0) [0|0] "" Vector__XXX
 SG_ HVP_pyroSquibResistance m0 : 32|16@1+ (0.001,0) [0|0] "" Vector__XXX
 SG_ HVP_energyReserveAvg m1 : 48|16@1- (0.001,0) [0|0] "" Vector__XXX
 SG_ HVP_shuntAsicChipXCoordinate m0 : 48|8@1+ (1,0) [0|0] "" Vector__XXX
 SG_ HVP_shuntAsicChipYCoordinate m0 : 56|8@1+ (1,0) [0|0] "" Vector__XXX

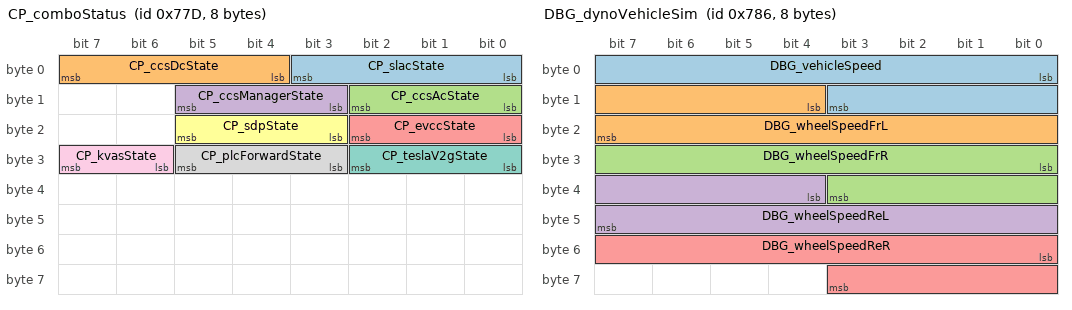
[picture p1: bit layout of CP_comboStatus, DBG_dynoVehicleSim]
BO_ 1917 CP_comboStatus: 8 Vector__XXX
 SG_ CP_slacState : 0|4@1+ (1,0) [0|0] "" Vector__XXX
 SG_ CP_ccsDcState : 4|4@1+ (1,0) [0|0] "" Vector__XXX
 SG_ CP_ccsAcState : 8|3@1+ (1,0) [0|0] "" Vector__XXX
 SG_ CP_ccsManagerState : 11|3@1+ (1,0) [0|0] "" Vector__XXX
 SG_ CP_evccState : 16|3@1+ (1,0) [0|0] "" Vector__XXX
 SG_ CP_sdpState : 19|3@1+ (1,0) [0|0] "" Vector__XXX
 SG_ CP_teslaV2gState : 24|3@1+ (1,0) [0|0] "" Vector__XXX
 SG_ CP_plcForwardState : 27|3@1+ (1,0) [0|0] "" Vector__XXX
 SG_ CP_kvasState : 30|2@1+ (1,0) [0|0] "" Vector__XXX

BO_ 1922 BMS_log3: 8 Vector__XXX
 SG_ BMS_log3MuxId M : 0|8@1+ (1,0) [0|0] "" Vector__XXX
 SG_ BMS_dSocAlphaBrick1 m0 : 8|14@1- (0.0030517578125,0) [0|0] "" Vector__XXX
 SG_ BMS_dSocAlphaBrick10 m9 : 8|14@1- (0.0030517578125,0) [0|0] "" Vector__XXX
 SG_ BMS_dSocAlphaBrick100 m99 : 8|14@1- (0.0030517578125,0) [0|0] "" Vector__XXX
 SG_ BMS_dSocAlphaBrick101 m100 : 8|14@1- (0.0030517578125,0) [0|0] "" Vector__XXX
 SG_ BMS_dSocAlphaBrick102 m101 : 8|14@1- (0.0030517578125,0) [0|0] "" Vector__XXX
 SG_ BMS_dSocAlphaBrick103 m102 : 8|14@1- (0.0030517578125,0) [0|0] "" Vector__XXX
 SG_ BMS_dSocAlphaBrick104 m103 : 8|14@1- (0.0030517578125,0) [0|0] "" Vector__XXX
 SG_ BMS_dSocAlphaBrick105 m104 : 8|14@1- (0.0030517578125,0) [0|0] "" Vector__XXX
 SG_ BMS_dSocAlphaBrick106 m105 : 8|14@1- (0.0030517578125,0) [0|0] "" Vector__XXX
 SG_ BMS_dSocAlphaBrick107 m106 : 8|14@1- (0.0030517578125,0) [0|0] "" Vector__XXX
 SG_ BMS_dSocAlphaBrick108 m107 : 8|14@1- (0.0030517578125,0) [0|0] "" Vector__XXX
 SG_ BMS_dSocAlphaBrick11 m10 : 8|14@1- (0.0030517578125,0) [0|0] "" Vector__XXX
 SG_ BMS_dSocAlphaBrick12 m11 : 8|14@1- (0.0030517578125,0) [0|0] "" Vector__XXX
 SG_ BMS_dSocAlphaBrick13 m12 : 8|14@1- (0.0030517578125,0) [0|0] "" Vector__XXX
 SG_ BMS_dSocAlphaBrick14 m13 : 8|14@1- (0.0030517578125,0) [0|0] "" Vector__XXX
 SG_ BMS_dSocAlphaBrick15 m14 : 8|14@1- (0.0030517578125,0) [0|0] "" Vector__XXX
 SG_ BMS_dSocAlphaBrick16 m15 : 8|14@1- (0.0030517578125,0) [0|0] "" Vector__XXX
 SG_ BMS_dSocAlphaBrick17 m16 : 8|14@1- (0.0030517578125,0) [0|0] "" Vector__XXX
 SG_ BMS_dSocAlphaBrick18 m17 : 8|14@1- (0.0030517578125,0) [0|0] "" Vector__XXX
 SG_ BMS_dSocAlphaBrick19 m18 : 8|14@1- (0.0030517578125,0) [0|0] "" Vector__XXX
 SG_ BMS_dSocAlphaBrick2 m1 : 8|14@1- (0.0030517578125,0) [0|0] "" Vector__XXX
 SG_ BMS_dSocAlphaBrick20 m19 : 8|14@1- (0.0030517578125,0) [0|0] "" Vector__XXX
 SG_ BMS_dSocAlphaBrick21 m20 : 8|14@1- (0.0030517578125,0) [0|0] "" Vector__XXX
 SG_ BMS_dSocAlphaBrick22 m21 : 8|14@1- (0.0030517578125,0) [0|0] "" Vector__XXX
 SG_ BMS_dSocAlphaBrick23 m22 : 8|14@1- (0.0030517578125,0) [0|0] "" Vector__XXX
 SG_ BMS_dSocAlphaBrick24 m23 : 8|14@1- (0.0030517578125,0) [0|0] "" Vector__XXX
 SG_ BMS_dSocAlphaBrick25 m24 : 8|14@1- (0.0030517578125,0) [0|0] "" Vector__XXX
 SG_ BMS_dSocAlphaBrick26 m25 : 8|14@1- (0.0030517578125,0) [0|0] "" Vector__XXX
 SG_ BMS_dSocAlphaBrick27 m26 : 8|14@1- (0.0030517578125,0) [0|0] "" Vector__XXX
 SG_ BMS_dSocAlphaBrick28 m27 : 8|14@1- (0.0030517578125,0) [0|0] "" Vector__XXX
 SG_ BMS_dSocAlphaBrick29 m28 : 8|14@1- (0.0030517578125,0) [0|0] "" Vector__XXX
 SG_ BMS_dSocAlphaBrick3 m2 : 8|14@1- (0.0030517578125,0) [0|0] "" Vector__XXX
 SG_ BMS_dSocAlphaBrick30 m29 : 8|14@1- (0.0030517578125,0) [0|0] "" Vector__XXX
 SG_ BMS_dSocAlphaBrick31 m30 : 8|14@1- (0.0030517578125,0) [0|0] "" Vector__XXX
 SG_ BMS_dSocAlphaBrick32 m31 : 8|14@1- (0.0030517578125,0) [0|0] "" Vector__XXX
 SG_ BMS_dSocAlphaBrick33 m32 : 8|14@1- (0.0030517578125,0) [0|0] "" Vector__XXX
 SG_ BMS_dSocAlphaBrick34 m33 : 8|14@1- (0.0030517578125,0) [0|0] "" Vector__XXX
 SG_ BMS_dSocAlphaBrick35 m34 : 8|14@1- (0.0030517578125,0) [0|0] "" Vector__XXX
 SG_ BMS_dSocAlphaBrick36 m35 : 8|14@1- (0.0030517578125,0) [0|0] "" Vector__XXX
 SG_ BMS_dSocAlphaBrick37 m36 : 8|14@1- (0.0030517578125,0) [0|0] "" Vector__XXX
 SG_ BMS_dSocAlphaBrick38 m37 : 8|14@1- (0.0030517578125,0) [0|0] "" Vector__XXX
 SG_ BMS_dSocAlphaBrick39 m38 : 8|14@1- (0.0030517578125,0) [0|0] "" Vector__XXX
 SG_ BMS_dSocAlphaBrick4 m3 : 8|14@1- (0.0030517578125,0) [0|0] "" Vector__XXX
 SG_ BMS_dSocAlphaBrick40 m39 : 8|14@1- (0.0030517578125,0) [0|0] "" Vector__XXX
 SG_ BMS_dSocAlphaBrick41 m40 : 8|14@1- (0.0030517578125,0) [0|0] "" Vector__XXX
 SG_ BMS_dSocAlphaBrick42 m41 : 8|14@1- (0.0030517578125,0) [0|0] "" Vector__XXX
 SG_ BMS_dSocAlphaBrick43 m42 : 8|14@1- (0.0030517578125,0) [0|0] "" Vector__XXX
 SG_ BMS_dSocAlphaBrick44 m43 : 8|14@1- (0.0030517578125,0) [0|0] "" Vector__XXX
 SG_ BMS_dSocAlphaBrick45 m44 : 8|14@1- (0.0030517578125,0) [0|0] "" Vector__XXX
 SG_ BMS_dSocAlphaBrick46 m45 : 8|14@1- (0.0030517578125,0) [0|0] "" Vector__XXX
 SG_ BMS_dSocAlphaBrick47 m46 : 8|14@1- (0.0030517578125,0) [0|0] "" Vector__XXX
 SG_ BMS_dSocAlphaBrick48 m47 : 8|14@1- (0.0030517578125,0) [0|0] "" Vector__XXX
 SG_ BMS_dSocAlphaBrick49 m48 : 8|14@1- (0.0030517578125,0) [0|0] "" Vector__XXX
 SG_ BMS_dSocAlphaBrick5 m4 : 8|14@1- (0.0030517578125,0) [0|0] "" Vector__XXX
 SG_ BMS_dSocAlphaBrick50 m49 : 8|14@1- (0.0030517578125,0) [0|0] "" Vector__XXX
 SG_ BMS_dSocAlphaBrick51 m50 : 8|14@1- (0.0030517578125,0) [0|0] "" Vector__XXX
 SG_ BMS_dSocAlphaBrick52 m51 : 8|14@1- (0.0030517578125,0) [0|0] "" Vector__XXX
 SG_ BMS_dSocAlphaBrick53 m52 : 8|14@1- (0.0030517578125,0) [0|0] "" Vector__XXX
 SG_ BMS_dSocAlphaBrick54 m53 : 8|14@1- (0.0030517578125,0) [0|0] "" Vector__XXX
 SG_ BMS_dSocAlphaBrick55 m54 : 8|14@1- (0.0030517578125,0) [0|0] "" Vector__XXX
 SG_ BMS_dSocAlphaBrick56 m55 : 8|14@1- (0.0030517578125,0) [0|0] "" Vector__XXX
 SG_ BMS_dSocAlphaBrick57 m56 : 8|14@1- (0.0030517578125,0) [0|0] "" Vector__XXX
 SG_ BMS_dSocAlphaBrick58 m57 : 8|14@1- (0.0030517578125,0) [0|0] "" Vector__XXX
 SG_ BMS_dSocAlphaBrick59 m58 : 8|14@1- (0.0030517578125,0) [0|0] "" Vector__XXX
 SG_ BMS_dSocAlphaBrick6 m5 : 8|14@1- (0.0030517578125,0) [0|0] "" Vector__XXX
 SG_ BMS_dSocAlphaBrick60 m59 : 8|14@1- (0.0030517578125,0) [0|0] "" Vector__XXX
 SG_ BMS_dSocAlphaBrick61 m60 : 8|14@1- (0.0030517578125,0) [0|0] "" Vector__XXX
 SG_ BMS_dSocAlphaBrick62 m61 : 8|14@1- (0.0030517578125,0) [0|0] "" Vector__XXX
 SG_ BMS_dSocAlphaBrick63 m62 : 8|14@1- (0.0030517578125,0) [0|0] "" Vector__XXX
 SG_ BMS_dSocAlphaBrick64 m63 : 8|14@1- (0.0030517578125,0) [0|0] "" Vector__XXX
 SG_ BMS_dSocAlphaBrick65 m64 : 8|14@1- (0.0030517578125,0) [0|0] "" Vector__XXX
 SG_ BMS_dSocAlphaBrick66 m65 : 8|14@1- (0.0030517578125,0) [0|0] "" Vector__XXX
 SG_ BMS_dSocAlphaBrick67 m66 : 8|14@1- (0.0030517578125,0) [0|0] "" Vector__XXX
 SG_ BMS_dSocAlphaBrick68 m67 : 8|14@1- (0.0030517578125,0) [0|0] "" Vector__XXX
 SG_ BMS_dSocAlphaBrick69 m68 : 8|14@1- (0.0030517578125,0) [0|0] "" Vector__XXX
 SG_ BMS_dSocAlphaBrick7 m6 : 8|14@1- (0.0030517578125,0) [0|0] "" Vector__XXX
 SG_ BMS_dSocAlphaBrick70 m69 : 8|14@1- (0.0030517578125,0) [0|0] "" Vector__XXX
 SG_ BMS_dSocAlphaBrick71 m70 : 8|14@1- (0.0030517578125,0) [0|0] "" Vector__XXX
 SG_ BMS_dSocAlphaBrick72 m71 : 8|14@1- (0.0030517578125,0) [0|0] "" Vector__XXX
 SG_ BMS_dSocAlphaBrick73 m72 : 8|14@1- (0.0030517578125,0) [0|0] "" Vector__XXX
 SG_ BMS_dSocAlphaBrick74 m73 : 8|14@1- (0.0030517578125,0) [0|0] "" Vector__XXX
 SG_ BMS_dSocAlphaBrick75 m74 : 8|14@1- (0.0030517578125,0) [0|0] "" Vector__XXX
 SG_ BMS_dSocAlphaBrick76 m75 : 8|14@1- (0.0030517578125,0) [0|0] "" Vector__XXX
 SG_ BMS_dSocAlphaBrick77 m76 : 8|14@1- (0.0030517578125,0) [0|0] "" Vector__XXX
 SG_ BMS_dSocAlphaBrick78 m77 : 8|14@1- (0.0030517578125,0) [0|0] "" Vector__XXX
 SG_ BMS_dSocAlphaBrick79 m78 : 8|14@1- (0.0030517578125,0) [0|0] "" Vector__XXX
 SG_ BMS_dSocAlphaBrick8 m7 : 8|14@1- (0.0030517578125,0) [0|0] "" Vector__XXX
 SG_ BMS_dSocAlphaBrick80 m79 : 8|14@1- (0.0030517578125,0) [0|0] "" Vector__XXX
 SG_ BMS_dSocAlphaBrick81 m80 : 8|14@1- (0.0030517578125,0) [0|0] "" Vector__XXX
 SG_ BMS_dSocAlphaBrick82 m81 : 8|14@1- (0.0030517578125,0) [0|0] "" Vector__XXX
 SG_ BMS_dSocAlphaBrick83 m82 : 8|14@1- (0.0030517578125,0) [0|0] "" Vector__XXX
 SG_ BMS_dSocAlphaBrick84 m83 : 8|14@1- (0.0030517578125,0) [0|0] "" Vector__XXX
 SG_ BMS_dSocAlphaBrick85 m84 : 8|14@1- (0.0030517578125,0) [0|0] "" Vector__XXX
 SG_ BMS_dSocAlphaBrick86 m85 : 8|14@1- (0.0030517578125,0) [0|0] "" Vector__XXX
 SG_ BMS_dSocAlphaBrick87 m86 : 8|14@1- (0.0030517578125,0) [0|0] "" Vector__XXX
 SG_ BMS_dSocAlphaBrick88 m87 : 8|14@1- (0.0030517578125,0) [0|0] "" Vector__XXX
 SG_ BMS_dSocAlphaBrick89 m88 : 8|14@1- (0.0030517578125,0) [0|0] "" Vector__XXX
 SG_ BMS_dSocAlphaBrick9 m8 : 8|14@1- (0.0030517578125,0) [0|0] "" Vector__XXX
 SG_ BMS_dSocAlphaBrick90 m89 : 8|14@1- (0.0030517578125,0) [0|0] "" Vector__XXX
 SG_ BMS_dSocAlphaBrick91 m90 : 8|14@1- (0.0030517578125,0) [0|0] "" Vector__XXX
 SG_ BMS_dSocAlphaBrick92 m91 : 8|14@1- (0.0030517578125,0) [0|0] "" Vector__XXX
 SG_ BMS_dSocAlphaBrick93 m92 : 8|14@1- (0.0030517578125,0) [0|0] "" Vector__XXX
 SG_ BMS_dSocAlphaBrick94 m93 : 8|14@1- (0.0030517578125,0) [0|0] "" Vector__XXX
 SG_ BMS_dSocAlphaBrick95 m94 : 8|14@1- (0.0030517578125,0) [0|0] "" Vector__XXX
 SG_ BMS_dSocAlphaBrick96 m95 : 8|14@1- (0.0030517578125,0) [0|0] "" Vector__XXX
 SG_ BMS_dSocAlphaBrick97 m96 : 8|14@1- (0.0030517578125,0) [0|0] "" Vector__XXX
 SG_ BMS_dSocAlphaBrick98 m97 : 8|14@1- (0.0030517578125,0) [0|0] "" Vector__XXX
 SG_ BMS_dSocAlphaBrick99 m98 : 8|14@1- (0.0030517578125,0) [0|0] "" Vector__XXX
 SG_ BMS_cacBrick1 m0 : 22|13@1+ (0.1,0) [0|0] "" Vector__XXX
 SG_ BMS_cacBrick10 m9 : 22|13@1+ (0.1,0) [0|0] "" Vector__XXX
 SG_ BMS_cacBrick100 m99 : 22|13@1+ (0.1,0) [0|0] "" Vector__XXX
 SG_ BMS_cacBrick101 m100 : 22|13@1+ (0.1,0) [0|0] "" Vector__XXX
 SG_ BMS_cacBrick102 m101 : 22|13@1+ (0.1,0) [0|0] "" Vector__XXX
 SG_ BMS_cacBrick103 m102 : 22|13@1+ (0.1,0) [0|0] "" Vector__XXX
 SG_ BMS_cacBrick104 m103 : 22|13@1+ (0.1,0) [0|0] "" Vector__XXX
 SG_ BMS_cacBrick105 m104 : 22|13@1+ (0.1,0) [0|0] "" Vector__XXX
 SG_ BMS_cacBrick106 m105 : 22|13@1+ (0.1,0) [0|0] "" Vector__XXX
 SG_ BMS_cacBrick107 m106 : 22|13@1+ (0.1,0) [0|0] "" Vector__XXX
 SG_ BMS_cacBrick108 m107 : 22|13@1+ (0.1,0) [0|0] "" Vector__XXX
 SG_ BMS_cacBrick11 m10 : 22|13@1+ (0.1,0) [0|0] "" Vector__XXX
 SG_ BMS_cacBrick12 m11 : 22|13@1+ (0.1,0) [0|0] "" Vector__XXX
 SG_ BMS_cacBrick13 m12 : 22|13@1+ (0.1,0) [0|0] "" Vector__XXX
 SG_ BMS_cacBrick14 m13 : 22|13@1+ (0.1,0) [0|0] "" Vector__XXX
 SG_ BMS_cacBrick15 m14 : 22|13@1+ (0.1,0) [0|0] "" Vector__XXX
 SG_ BMS_cacBrick16 m15 : 22|13@1+ (0.1,0) [0|0] "" Vector__XXX
 SG_ BMS_cacBrick17 m16 : 22|13@1+ (0.1,0) [0|0] "" Vector__XXX
 SG_ BMS_cacBrick18 m17 : 22|13@1+ (0.1,0) [0|0] "" Vector__XXX
 SG_ BMS_cacBrick19 m18 : 22|13@1+ (0.1,0) [0|0] "" Vector__XXX
 SG_ BMS_cacBrick2 m1 : 22|13@1+ (0.1,0) [0|0] "" Vector__XXX
 SG_ BMS_cacBrick20 m19 : 22|13@1+ (0.1,0) [0|0] "" Vector__XXX
 SG_ BMS_cacBrick21 m20 : 22|13@1+ (0.1,0) [0|0] "" Vector__XXX
 SG_ BMS_cacBrick22 m21 : 22|13@1+ (0.1,0) [0|0] "" Vector__XXX
 SG_ BMS_cacBrick23 m22 : 22|13@1+ (0.1,0) [0|0] "" Vector__XXX
 SG_ BMS_cacBrick24 m23 : 22|13@1+ (0.1,0) [0|0] "" Vector__XXX
 SG_ BMS_cacBrick25 m24 : 22|13@1+ (0.1,0) [0|0] "" Vector__XXX
 SG_ BMS_cacBrick26 m25 : 22|13@1+ (0.1,0) [0|0] "" Vector__XXX
 SG_ BMS_cacBrick27 m26 : 22|13@1+ (0.1,0) [0|0] "" Vector__XXX
 SG_ BMS_cacBrick28 m27 : 22|13@1+ (0.1,0) [0|0] "" Vector__XXX
 SG_ BMS_cacBrick29 m28 : 22|13@1+ (0.1,0) [0|0] "" Vector__XXX
 SG_ BMS_cacBrick3 m2 : 22|13@1+ (0.1,0) [0|0] "" Vector__XXX
 SG_ BMS_cacBrick30 m29 : 22|13@1+ (0.1,0) [0|0] "" Vector__XXX
 SG_ BMS_cacBrick31 m30 : 22|13@1+ (0.1,0) [0|0] "" Vector__XXX
 SG_ BMS_cacBrick32 m31 : 22|13@1+ (0.1,0) [0|0] "" Vector__XXX
 SG_ BMS_cacBrick33 m32 : 22|13@1+ (0.1,0) [0|0] "" Vector__XXX
 SG_ BMS_cacBrick34 m33 : 22|13@1+ (0.1,0) [0|0] "" Vector__XXX
 SG_ BMS_cacBrick35 m34 : 22|13@1+ (0.1,0) [0|0] "" Vector__XXX
 SG_ BMS_cacBrick36 m35 : 22|13@1+ (0.1,0) [0|0] "" Vector__XXX
 SG_ BMS_cacBrick37 m36 : 22|13@1+ (0.1,0) [0|0] "" Vector__XXX
 SG_ BMS_cacBrick38 m37 : 22|13@1+ (0.1,0) [0|0] "" Vector__XXX
 SG_ BMS_cacBrick39 m38 : 22|13@1+ (0.1,0) [0|0] "" Vector__XXX
 SG_ BMS_cacBrick4 m3 : 22|13@1+ (0.1,0) [0|0] "" Vector__XXX
 SG_ BMS_cacBrick40 m39 : 22|13@1+ (0.1,0) [0|0] "" Vector__XXX
 SG_ BMS_cacBrick41 m40 : 22|13@1+ (0.1,0) [0|0] "" Vector__XXX
 SG_ BMS_cacBrick42 m41 : 22|13@1+ (0.1,0) [0|0] "" Vector__XXX
 SG_ BMS_cacBrick43 m42 : 22|13@1+ (0.1,0) [0|0] "" Vector__XXX
 SG_ BMS_cacBrick44 m43 : 22|13@1+ (0.1,0) [0|0] "" Vector__XXX
 SG_ BMS_cacBrick45 m44 : 22|13@1+ (0.1,0) [0|0] "" Vector__XXX
 SG_ BMS_cacBrick46 m45 : 22|13@1+ (0.1,0) [0|0] "" Vector__XXX
 SG_ BMS_cacBrick47 m46 : 22|13@1+ (0.1,0) [0|0] "" Vector__XXX
 SG_ BMS_cacBrick48 m47 : 22|13@1+ (0.1,0) [0|0] "" Vector__XXX
 SG_ BMS_cacBrick49 m48 : 22|13@1+ (0.1,0) [0|0] "" Vector__XXX
 SG_ BMS_cacBrick5 m4 : 22|13@1+ (0.1,0) [0|0] "" Vector__XXX
 SG_ BMS_cacBrick50 m49 : 22|13@1+ (0.1,0) [0|0] "" Vector__XXX
 SG_ BMS_cacBrick51 m50 : 22|13@1+ (0.1,0) [0|0] "" Vector__XXX
 SG_ BMS_cacBrick52 m51 : 22|13@1+ (0.1,0) [0|0] "" Vector__XXX
 SG_ BMS_cacBrick53 m52 : 22|13@1+ (0.1,0) [0|0] "" Vector__XXX
 SG_ BMS_cacBrick54 m53 : 22|13@1+ (0.1,0) [0|0] "" Vector__XXX
 SG_ BMS_cacBrick55 m54 : 22|13@1+ (0.1,0) [0|0] "" Vector__XXX
 SG_ BMS_cacBrick56 m55 : 22|13@1+ (0.1,0) [0|0] "" Vector__XXX
 SG_ BMS_cacBrick57 m56 : 22|13@1+ (0.1,0) [0|0] "" Vector__XXX
 SG_ BMS_cacBrick58 m57 : 22|13@1+ (0.1,0) [0|0] "" Vector__XXX
 SG_ BMS_cacBrick59 m58 : 22|13@1+ (0.1,0) [0|0] "" Vector__XXX
 SG_ BMS_cacBrick6 m5 : 22|13@1+ (0.1,0) [0|0] "" Vector__XXX
 SG_ BMS_cacBrick60 m59 : 22|13@1+ (0.1,0) [0|0] "" Vector__XXX
 SG_ BMS_cacBrick61 m60 : 22|13@1+ (0.1,0) [0|0] "" Vector__XXX
 SG_ BMS_cacBrick62 m61 : 22|13@1+ (0.1,0) [0|0] "" Vector__XXX
 SG_ BMS_cacBrick63 m62 : 22|13@1+ (0.1,0) [0|0] "" Vector__XXX
 SG_ BMS_cacBrick64 m63 : 22|13@1+ (0.1,0) [0|0] "" Vector__XXX
 SG_ BMS_cacBrick65 m64 : 22|13@1+ (0.1,0) [0|0] "" Vector__XXX
 SG_ BMS_cacBrick66 m65 : 22|13@1+ (0.1,0) [0|0] "" Vector__XXX
 SG_ BMS_cacBrick67 m66 : 22|13@1+ (0.1,0) [0|0] "" Vector__XXX
 SG_ BMS_cacBrick68 m67 : 22|13@1+ (0.1,0) [0|0] "" Vector__XXX
 SG_ BMS_cacBrick69 m68 : 22|13@1+ (0.1,0) [0|0] "" Vector__XXX
 SG_ BMS_cacBrick7 m6 : 22|13@1+ (0.1,0) [0|0] "" Vector__XXX
 SG_ BMS_cacBrick70 m69 : 22|13@1+ (0.1,0) [0|0] "" Vector__XXX
 SG_ BMS_cacBrick71 m70 : 22|13@1+ (0.1,0) [0|0] "" Vector__XXX
 SG_ BMS_cacBrick72 m71 : 22|13@1+ (0.1,0) [0|0] "" Vector__XXX
 SG_ BMS_cacBrick73 m72 : 22|13@1+ (0.1,0) [0|0] "" Vector__XXX
 SG_ BMS_cacBrick74 m73 : 22|13@1+ (0.1,0) [0|0] "" Vector__XXX
 SG_ BMS_cacBrick75 m74 : 22|13@1+ (0.1,0) [0|0] "" Vector__XXX
 SG_ BMS_cacBrick76 m75 : 22|13@1+ (0.1,0) [0|0] "" Vector__XXX
 SG_ BMS_cacBrick77 m76 : 22|13@1+ (0.1,0) [0|0] "" Vector__XXX
 SG_ BMS_cacBrick78 m77 : 22|13@1+ (0.1,0) [0|0] "" Vector__XXX
 SG_ BMS_cacBrick79 m78 : 22|13@1+ (0.1,0) [0|0] "" Vector__XXX
 SG_ BMS_cacBrick8 m7 : 22|13@1+ (0.1,0) [0|0] "" Vector__XXX
 SG_ BMS_cacBrick80 m79 : 22|13@1+ (0.1,0) [0|0] "" Vector__XXX
 SG_ BMS_cacBrick81 m80 : 22|13@1+ (0.1,0) [0|0] "" Vector__XXX
 SG_ BMS_cacBrick82 m81 : 22|13@1+ (0.1,0) [0|0] "" Vector__XXX
 SG_ BMS_cacBrick83 m82 : 22|13@1+ (0.1,0) [0|0] "" Vector__XXX
 SG_ BMS_cacBrick84 m83 : 22|13@1+ (0.1,0) [0|0] "" Vector__XXX
 SG_ BMS_cacBrick85 m84 : 22|13@1+ (0.1,0) [0|0] "" Vector__XXX
 SG_ BMS_cacBrick86 m85 : 22|13@1+ (0.1,0) [0|0] "" Vector__XXX
 SG_ BMS_cacBrick87 m86 : 22|13@1+ (0.1,0) [0|0] "" Vector__XXX
 SG_ BMS_cacBrick88 m87 : 22|13@1+ (0.1,0) [0|0] "" Vector__XXX
 SG_ BMS_cacBrick89 m88 : 22|13@1+ (0.1,0) [0|0] "" Vector__XXX
 SG_ BMS_cacBrick9 m8 : 22|13@1+ (0.1,0) [0|0] "" Vector__XXX
 SG_ BMS_cacBrick90 m89 : 22|13@1+ (0.1,0) [0|0] "" Vector__XXX
 SG_ BMS_cacBrick91 m90 : 22|13@1+ (0.1,0) [0|0] "" Vector__XXX
 SG_ BMS_cacBrick92 m91 : 22|13@1+ (0.1,0) [0|0] "" Vector__XXX
 SG_ BMS_cacBrick93 m92 : 22|13@1+ (0.1,0) [0|0] "" Vector__XXX
 SG_ BMS_cacBrick94 m93 : 22|13@1+ (0.1,0) [0|0] "" Vector__XXX
 SG_ BMS_cacBrick95 m94 : 22|13@1+ (0.1,0) [0|0] "" Vector__XXX
 SG_ BMS_cacBrick96 m95 : 22|13@1+ (0.1,0) [0|0] "" Vector__XXX
 SG_ BMS_cacBrick97 m96 : 22|13@1+ (0.1,0) [0|0] "" Vector__XXX
 SG_ BMS_cacBrick98 m97 : 22|13@1+ (0.1,0) [0|0] "" Vector__XXX
 SG_ BMS_cacBrick99 m98 : 22|13@1+ (0.1,0) [0|0] "" Vector__XXX
 SG_ BMS_cacLowerBoundBrick1 m0 : 35|13@1+ (0.1,0) [0|0] "" Vector__XXX
 SG_ BMS_cacLowerBoundBrick10 m9 : 35|13@1+ (0.1,0) [0|0] "" Vector__XXX
 SG_ BMS_cacLowerBoundBrick100 m99 : 35|13@1+ (0.1,0) [0|0] "" Vector__XXX
 SG_ BMS_cacLowerBoundBrick101 m100 : 35|13@1+ (0.1,0) [0|0] "" Vector__XXX
 SG_ BMS_cacLowerBoundBrick102 m101 : 35|13@1+ (0.1,0) [0|0] "" Vector__XXX
 SG_ BMS_cacLowerBoundBrick103 m102 : 35|13@1+ (0.1,0) [0|0] "" Vector__XXX
 SG_ BMS_cacLowerBoundBrick104 m103 : 35|13@1+ (0.1,0) [0|0] "" Vector__XXX
 SG_ BMS_cacLowerBoundBrick105 m104 : 35|13@1+ (0.1,0) [0|0] "" Vector__XXX
 SG_ BMS_cacLowerBoundBrick106 m105 : 35|13@1+ (0.1,0) [0|0] "" Vector__XXX
 SG_ BMS_cacLowerBoundBrick107 m106 : 35|13@1+ (0.1,0) [0|0] "" Vector__XXX
 SG_ BMS_cacLowerBoundBrick108 m107 : 35|13@1+ (0.1,0) [0|0] "" Vector__XXX
 SG_ BMS_cacLowerBoundBrick11 m10 : 35|13@1+ (0.1,0) [0|0] "" Vector__XXX
 SG_ BMS_cacLowerBoundBrick12 m11 : 35|13@1+ (0.1,0) [0|0] "" Vector__XXX
 SG_ BMS_cacLowerBoundBrick13 m12 : 35|13@1+ (0.1,0) [0|0] "" Vector__XXX
 SG_ BMS_cacLowerBoundBrick14 m13 : 35|13@1+ (0.1,0) [0|0] "" Vector__XXX
 SG_ BMS_cacLowerBoundBrick15 m14 : 35|13@1+ (0.1,0) [0|0] "" Vector__XXX
 SG_ BMS_cacLowerBoundBrick16 m15 : 35|13@1+ (0.1,0) [0|0] "" Vector__XXX
 SG_ BMS_cacLowerBoundBrick17 m16 : 35|13@1+ (0.1,0) [0|0] "" Vector__XXX
 SG_ BMS_cacLowerBoundBrick18 m17 : 35|13@1+ (0.1,0) [0|0] "" Vector__XXX
 SG_ BMS_cacLowerBoundBrick19 m18 : 35|13@1+ (0.1,0) [0|0] "" Vector__XXX
 SG_ BMS_cacLowerBoundBrick2 m1 : 35|13@1+ (0.1,0) [0|0] "" Vector__XXX
 SG_ BMS_cacLowerBoundBrick20 m19 : 35|13@1+ (0.1,0) [0|0] "" Vector__XXX
 SG_ BMS_cacLowerBoundBrick21 m20 : 35|13@1+ (0.1,0) [0|0] "" Vector__XXX
 SG_ BMS_cacLowerBoundBrick22 m21 : 35|13@1+ (0.1,0) [0|0] "" Vector__XXX
 SG_ BMS_cacLowerBoundBrick23 m22 : 35|13@1+ (0.1,0) [0|0] "" Vector__XXX
 SG_ BMS_cacLowerBoundBrick24 m23 : 35|13@1+ (0.1,0) [0|0] "" Vector__XXX
 SG_ BMS_cacLowerBoundBrick25 m24 : 35|13@1+ (0.1,0) [0|0] "" Vector__XXX
 SG_ BMS_cacLowerBoundBrick26 m25 : 35|13@1+ (0.1,0) [0|0] "" Vector__XXX
 SG_ BMS_cacLowerBoundBrick27 m26 : 35|13@1+ (0.1,0) [0|0] "" Vector__XXX
 SG_ BMS_cacLowerBoundBrick28 m27 : 35|13@1+ (0.1,0) [0|0] "" Vector__XXX
 SG_ BMS_cacLowerBoundBrick29 m28 : 35|13@1+ (0.1,0) [0|0] "" Vector__XXX
 SG_ BMS_cacLowerBoundBrick3 m2 : 35|13@1+ (0.1,0) [0|0] "" Vector__XXX
 SG_ BMS_cacLowerBoundBrick30 m29 : 35|13@1+ (0.1,0) [0|0] "" Vector__XXX
 SG_ BMS_cacLowerBoundBrick31 m30 : 35|13@1+ (0.1,0) [0|0] "" Vector__XXX
 SG_ BMS_cacLowerBoundBrick32 m31 : 35|13@1+ (0.1,0) [0|0] "" Vector__XXX
 SG_ BMS_cacLowerBoundBrick33 m32 : 35|13@1+ (0.1,0) [0|0] "" Vector__XXX
 SG_ BMS_cacLowerBoundBrick34 m33 : 35|13@1+ (0.1,0) [0|0] "" Vector__XXX
 SG_ BMS_cacLowerBoundBrick35 m34 : 35|13@1+ (0.1,0) [0|0] "" Vector__XXX
 SG_ BMS_cacLowerBoundBrick36 m35 : 35|13@1+ (0.1,0) [0|0] "" Vector__XXX
 SG_ BMS_cacLowerBoundBrick37 m36 : 35|13@1+ (0.1,0) [0|0] "" Vector__XXX
 SG_ BMS_cacLowerBoundBrick38 m37 : 35|13@1+ (0.1,0) [0|0] "" Vector__XXX
 SG_ BMS_cacLowerBoundBrick39 m38 : 35|13@1+ (0.1,0) [0|0] "" Vector__XXX
 SG_ BMS_cacLowerBoundBrick4 m3 : 35|13@1+ (0.1,0) [0|0] "" Vector__XXX
 SG_ BMS_cacLowerBoundBrick40 m39 : 35|13@1+ (0.1,0) [0|0] "" Vector__XXX
 SG_ BMS_cacLowerBoundBrick41 m40 : 35|13@1+ (0.1,0) [0|0] "" Vector__XXX
 SG_ BMS_cacLowerBoundBrick42 m41 : 35|13@1+ (0.1,0) [0|0] "" Vector__XXX
 SG_ BMS_cacLowerBoundBrick43 m42 : 35|13@1+ (0.1,0) [0|0] "" Vector__XXX
 SG_ BMS_cacLowerBoundBrick44 m43 : 35|13@1+ (0.1,0) [0|0] "" Vector__XXX
 SG_ BMS_cacLowerBoundBrick45 m44 : 35|13@1+ (0.1,0) [0|0] "" Vector__XXX
 SG_ BMS_cacLowerBoundBrick46 m45 : 35|13@1+ (0.1,0) [0|0] "" Vector__XXX
 SG_ BMS_cacLowerBoundBrick47 m46 : 35|13@1+ (0.1,0) [0|0] "" Vector__XXX
 SG_ BMS_cacLowerBoundBrick48 m47 : 35|13@1+ (0.1,0) [0|0] "" Vector__XXX
 SG_ BMS_cacLowerBoundBrick49 m48 : 35|13@1+ (0.1,0) [0|0] "" Vector__XXX
 SG_ BMS_cacLowerBoundBrick5 m4 : 35|13@1+ (0.1,0) [0|0] "" Vector__XXX
 SG_ BMS_cacLowerBoundBrick50 m49 : 35|13@1+ (0.1,0) [0|0] "" Vector__XXX
 SG_ BMS_cacLowerBoundBrick51 m50 : 35|13@1+ (0.1,0) [0|0] "" Vector__XXX
 SG_ BMS_cacLowerBoundBrick52 m51 : 35|13@1+ (0.1,0) [0|0] "" Vector__XXX
 SG_ BMS_cacLowerBoundBrick53 m52 : 35|13@1+ (0.1,0) [0|0] "" Vector__XXX
 SG_ BMS_cacLowerBoundBrick54 m53 : 35|13@1+ (0.1,0) [0|0] "" Vector__XXX
 SG_ BMS_cacLowerBoundBrick55 m54 : 35|13@1+ (0.1,0) [0|0] "" Vector__XXX
 SG_ BMS_cacLowerBoundBrick56 m55 : 35|13@1+ (0.1,0) [0|0] "" Vector__XXX
 SG_ BMS_cacLowerBoundBrick57 m56 : 35|13@1+ (0.1,0) [0|0] "" Vector__XXX
 SG_ BMS_cacLowerBoundBrick58 m57 : 35|13@1+ (0.1,0) [0|0] "" Vector__XXX
 SG_ BMS_cacLowerBoundBrick59 m58 : 35|13@1+ (0.1,0) [0|0] "" Vector__XXX
 SG_ BMS_cacLowerBoundBrick6 m5 : 35|13@1+ (0.1,0) [0|0] "" Vector__XXX
 SG_ BMS_cacLowerBoundBrick60 m59 : 35|13@1+ (0.1,0) [0|0] "" Vector__XXX
 SG_ BMS_cacLowerBoundBrick61 m60 : 35|13@1+ (0.1,0) [0|0] "" Vector__XXX
 SG_ BMS_cacLowerBoundBrick62 m61 : 35|13@1+ (0.1,0) [0|0] "" Vector__XXX
 SG_ BMS_cacLowerBoundBrick63 m62 : 35|13@1+ (0.1,0) [0|0] "" Vector__XXX
 SG_ BMS_cacLowerBoundBrick64 m63 : 35|13@1+ (0.1,0) [0|0] "" Vector__XXX
 SG_ BMS_cacLowerBoundBrick65 m64 : 35|13@1+ (0.1,0) [0|0] "" Vector__XXX
 SG_ BMS_cacLowerBoundBrick66 m65 : 35|13@1+ (0.1,0) [0|0] "" Vector__XXX
 SG_ BMS_cacLowerBoundBrick67 m66 : 35|13@1+ (0.1,0) [0|0] "" Vector__XXX
 SG_ BMS_cacLowerBoundBrick68 m67 : 35|13@1+ (0.1,0) [0|0] "" Vector__XXX
 SG_ BMS_cacLowerBoundBrick69 m68 : 35|13@1+ (0.1,0) [0|0] "" Vector__XXX
 SG_ BMS_cacLowerBoundBrick7 m6 : 35|13@1+ (0.1,0) [0|0] "" Vector__XXX
 SG_ BMS_cacLowerBoundBrick70 m69 : 35|13@1+ (0.1,0) [0|0] "" Vector__XXX
 SG_ BMS_cacLowerBoundBrick71 m70 : 35|13@1+ (0.1,0) [0|0] "" Vector__XXX
 SG_ BMS_cacLowerBoundBrick72 m71 : 35|13@1+ (0.1,0) [0|0] "" Vector__XXX
 SG_ BMS_cacLowerBoundBrick73 m72 : 35|13@1+ (0.1,0) [0|0] "" Vector__XXX
 SG_ BMS_cacLowerBoundBrick74 m73 : 35|13@1+ (0.1,0) [0|0] "" Vector__XXX
 SG_ BMS_cacLowerBoundBrick75 m74 : 35|13@1+ (0.1,0) [0|0] "" Vector__XXX
 SG_ BMS_cacLowerBoundBrick76 m75 : 35|13@1+ (0.1,0) [0|0] "" Vector__XXX
 SG_ BMS_cacLowerBoundBrick77 m76 : 35|13@1+ (0.1,0) [0|0] "" Vector__XXX
 SG_ BMS_cacLowerBoundBrick78 m77 : 35|13@1+ (0.1,0) [0|0] "" Vector__XXX
 SG_ BMS_cacLowerBoundBrick79 m78 : 35|13@1+ (0.1,0) [0|0] "" Vector__XXX
 SG_ BMS_cacLowerBoundBrick8 m7 : 35|13@1+ (0.1,0) [0|0] "" Vector__XXX
 SG_ BMS_cacLowerBoundBrick80 m79 : 35|13@1+ (0.1,0) [0|0] "" Vector__XXX
 SG_ BMS_cacLowerBoundBrick81 m80 : 35|13@1+ (0.1,0) [0|0] "" Vector__XXX
 SG_ BMS_cacLowerBoundBrick82 m81 : 35|13@1+ (0.1,0) [0|0] "" Vector__XXX
 SG_ BMS_cacLowerBoundBrick83 m82 : 35|13@1+ (0.1,0) [0|0] "" Vector__XXX
 SG_ BMS_cacLowerBoundBrick84 m83 : 35|13@1+ (0.1,0) [0|0] "" Vector__XXX
 SG_ BMS_cacLowerBoundBrick85 m84 : 35|13@1+ (0.1,0) [0|0] "" Vector__XXX
 SG_ BMS_cacLowerBoundBrick86 m85 : 35|13@1+ (0.1,0) [0|0] "" Vector__XXX
 SG_ BMS_cacLowerBoundBrick87 m86 : 35|13@1+ (0.1,0) [0|0] "" Vector__XXX
 SG_ BMS_cacLowerBoundBrick88 m87 : 35|13@1+ (0.1,0) [0|0] "" Vector__XXX
 SG_ BMS_cacLowerBoundBrick89 m88 : 35|13@1+ (0.1,0) [0|0] "" Vector__XXX
 SG_ BMS_cacLowerBoundBrick9 m8 : 35|13@1+ (0.1,0) [0|0] "" Vector__XXX
 SG_ BMS_cacLowerBoundBrick90 m89 : 35|13@1+ (0.1,0) [0|0] "" Vector__XXX
 SG_ BMS_cacLowerBoundBrick91 m90 : 35|13@1+ (0.1,0) [0|0] "" Vector__XXX
 SG_ BMS_cacLowerBoundBrick92 m91 : 35|13@1+ (0.1,0) [0|0] "" Vector__XXX
 SG_ BMS_cacLowerBoundBrick93 m92 : 35|13@1+ (0.1,0) [0|0] "" Vector__XXX
 SG_ BMS_cacLowerBoundBrick94 m93 : 35|13@1+ (0.1,0) [0|0] "" Vector__XXX
 SG_ BMS_cacLowerBoundBrick95 m94 : 35|13@1+ (0.1,0) [0|0] "" Vector__XXX
 SG_ BMS_cacLowerBoundBrick96 m95 : 35|13@1+ (0.1,0) [0|0] "" Vector__XXX
 SG_ BMS_cacLowerBoundBrick97 m96 : 35|13@1+ (0.1,0) [0|0] "" Vector__XXX
 SG_ BMS_cacLowerBoundBrick98 m97 : 35|13@1+ (0.1,0) [0|0] "" Vector__XXX
 SG_ BMS_cacLowerBoundBrick99 m98 : 35|13@1+ (0.1,0) [0|0] "" Vector__XXX
 SG_ BMS_cacRawEstimateBrick1 m0 : 48|13@1+ (0.1,0) [0|0] "" Vector__XXX
 SG_ BMS_cacRawEstimateBrick10 m9 : 48|13@1+ (0.1,0) [0|0] "" Vector__XXX
 SG_ BMS_cacRawEstimateBrick100 m99 : 48|13@1+ (0.1,0) [0|0] "" Vector__XXX
 SG_ BMS_cacRawEstimateBrick101 m100 : 48|13@1+ (0.1,0) [0|0] "" Vector__XXX
 SG_ BMS_cacRawEstimateBrick102 m101 : 48|13@1+ (0.1,0) [0|0] "" Vector__XXX
 SG_ BMS_cacRawEstimateBrick103 m102 : 48|13@1+ (0.1,0) [0|0] "" Vector__XXX
 SG_ BMS_cacRawEstimateBrick104 m103 : 48|13@1+ (0.1,0) [0|0] "" Vector__XXX
 SG_ BMS_cacRawEstimateBrick105 m104 : 48|13@1+ (0.1,0) [0|0] "" Vector__XXX
 SG_ BMS_cacRawEstimateBrick106 m105 : 48|13@1+ (0.1,0) [0|0] "" Vector__XXX
 SG_ BMS_cacRawEstimateBrick107 m106 : 48|13@1+ (0.1,0) [0|0] "" Vector__XXX
 SG_ BMS_cacRawEstimateBrick108 m107 : 48|13@1+ (0.1,0) [0|0] "" Vector__XXX
 SG_ BMS_cacRawEstimateBrick11 m10 : 48|13@1+ (0.1,0) [0|0] "" Vector__XXX
 SG_ BMS_cacRawEstimateBrick12 m11 : 48|13@1+ (0.1,0) [0|0] "" Vector__XXX
 SG_ BMS_cacRawEstimateBrick13 m12 : 48|13@1+ (0.1,0) [0|0] "" Vector__XXX
 SG_ BMS_cacRawEstimateBrick14 m13 : 48|13@1+ (0.1,0) [0|0] "" Vector__XXX
 SG_ BMS_cacRawEstimateBrick15 m14 : 48|13@1+ (0.1,0) [0|0] "" Vector__XXX
 SG_ BMS_cacRawEstimateBrick16 m15 : 48|13@1+ (0.1,0) [0|0] "" Vector__XXX
 SG_ BMS_cacRawEstimateBrick17 m16 : 48|13@1+ (0.1,0) [0|0] "" Vector__XXX
 SG_ BMS_cacRawEstimateBrick18 m17 : 48|13@1+ (0.1,0) [0|0] "" Vector__XXX
 SG_ BMS_cacRawEstimateBrick19 m18 : 48|13@1+ (0.1,0) [0|0] "" Vector__XXX
 SG_ BMS_cacRawEstimateBrick2 m1 : 48|13@1+ (0.1,0) [0|0] "" Vector__XXX
 SG_ BMS_cacRawEstimateBrick20 m19 : 48|13@1+ (0.1,0) [0|0] "" Vector__XXX
 SG_ BMS_cacRawEstimateBrick21 m20 : 48|13@1+ (0.1,0) [0|0] "" Vector__XXX
 SG_ BMS_cacRawEstimateBrick22 m21 : 48|13@1+ (0.1,0) [0|0] "" Vector__XXX
 SG_ BMS_cacRawEstimateBrick23 m22 : 48|13@1+ (0.1,0) [0|0] "" Vector__XXX
 SG_ BMS_cacRawEstimateBrick24 m23 : 48|13@1+ (0.1,0) [0|0] "" Vector__XXX
 SG_ BMS_cacRawEstimateBrick25 m24 : 48|13@1+ (0.1,0) [0|0] "" Vector__XXX
 SG_ BMS_cacRawEstimateBrick26 m25 : 48|13@1+ (0.1,0) [0|0] "" Vector__XXX
 SG_ BMS_cacRawEstimateBrick27 m26 : 48|13@1+ (0.1,0) [0|0] "" Vector__XXX
 SG_ BMS_cacRawEstimateBrick28 m27 : 48|13@1+ (0.1,0) [0|0] "" Vector__XXX
 SG_ BMS_cacRawEstimateBrick29 m28 : 48|13@1+ (0.1,0) [0|0] "" Vector__XXX
 SG_ BMS_cacRawEstimateBrick3 m2 : 48|13@1+ (0.1,0) [0|0] "" Vector__XXX
 SG_ BMS_cacRawEstimateBrick30 m29 : 48|13@1+ (0.1,0) [0|0] "" Vector__XXX
 SG_ BMS_cacRawEstimateBrick31 m30 : 48|13@1+ (0.1,0) [0|0] "" Vector__XXX
 SG_ BMS_cacRawEstimateBrick32 m31 : 48|13@1+ (0.1,0) [0|0] "" Vector__XXX
 SG_ BMS_cacRawEstimateBrick33 m32 : 48|13@1+ (0.1,0) [0|0] "" Vector__XXX
 SG_ BMS_cacRawEstimateBrick34 m33 : 48|13@1+ (0.1,0) [0|0] "" Vector__XXX
 SG_ BMS_cacRawEstimateBrick35 m34 : 48|13@1+ (0.1,0) [0|0] "" Vector__XXX
 SG_ BMS_cacRawEstimateBrick36 m35 : 48|13@1+ (0.1,0) [0|0] "" Vector__XXX
 SG_ BMS_cacRawEstimateBrick37 m36 : 48|13@1+ (0.1,0) [0|0] "" Vector__XXX
 SG_ BMS_cacRawEstimateBrick38 m37 : 48|13@1+ (0.1,0) [0|0] "" Vector__XXX
 SG_ BMS_cacRawEstimateBrick39 m38 : 48|13@1+ (0.1,0) [0|0] "" Vector__XXX
 SG_ BMS_cacRawEstimateBrick4 m3 : 48|13@1+ (0.1,0) [0|0] "" Vector__XXX
 SG_ BMS_cacRawEstimateBrick40 m39 : 48|13@1+ (0.1,0) [0|0] "" Vector__XXX
 SG_ BMS_cacRawEstimateBrick41 m40 : 48|13@1+ (0.1,0) [0|0] "" Vector__XXX
 SG_ BMS_cacRawEstimateBrick42 m41 : 48|13@1+ (0.1,0) [0|0] "" Vector__XXX
 SG_ BMS_cacRawEstimateBrick43 m42 : 48|13@1+ (0.1,0) [0|0] "" Vector__XXX
 SG_ BMS_cacRawEstimateBrick44 m43 : 48|13@1+ (0.1,0) [0|0] "" Vector__XXX
 SG_ BMS_cacRawEstimateBrick45 m44 : 48|13@1+ (0.1,0) [0|0] "" Vector__XXX
 SG_ BMS_cacRawEstimateBrick46 m45 : 48|13@1+ (0.1,0) [0|0] "" Vector__XXX
 SG_ BMS_cacRawEstimateBrick47 m46 : 48|13@1+ (0.1,0) [0|0] "" Vector__XXX
 SG_ BMS_cacRawEstimateBrick48 m47 : 48|13@1+ (0.1,0) [0|0] "" Vector__XXX
 SG_ BMS_cacRawEstimateBrick49 m48 : 48|13@1+ (0.1,0) [0|0] "" Vector__XXX
 SG_ BMS_cacRawEstimateBrick5 m4 : 48|13@1+ (0.1,0) [0|0] "" Vector__XXX
 SG_ BMS_cacRawEstimateBrick50 m49 : 48|13@1+ (0.1,0) [0|0] "" Vector__XXX
 SG_ BMS_cacRawEstimateBrick51 m50 : 48|13@1+ (0.1,0) [0|0] "" Vector__XXX
 SG_ BMS_cacRawEstimateBrick52 m51 : 48|13@1+ (0.1,0) [0|0] "" Vector__XXX
 SG_ BMS_cacRawEstimateBrick53 m52 : 48|13@1+ (0.1,0) [0|0] "" Vector__XXX
 SG_ BMS_cacRawEstimateBrick54 m53 : 48|13@1+ (0.1,0) [0|0] "" Vector__XXX
 SG_ BMS_cacRawEstimateBrick55 m54 : 48|13@1+ (0.1,0) [0|0] "" Vector__XXX
 SG_ BMS_cacRawEstimateBrick56 m55 : 48|13@1+ (0.1,0) [0|0] "" Vector__XXX
 SG_ BMS_cacRawEstimateBrick57 m56 : 48|13@1+ (0.1,0) [0|0] "" Vector__XXX
 SG_ BMS_cacRawEstimateBrick58 m57 : 48|13@1+ (0.1,0) [0|0] "" Vector__XXX
 SG_ BMS_cacRawEstimateBrick59 m58 : 48|13@1+ (0.1,0) [0|0] "" Vector__XXX
 SG_ BMS_cacRawEstimateBrick6 m5 : 48|13@1+ (0.1,0) [0|0] "" Vector__XXX
 SG_ BMS_cacRawEstimateBrick60 m59 : 48|13@1+ (0.1,0) [0|0] "" Vector__XXX
 SG_ BMS_cacRawEstimateBrick61 m60 : 48|13@1+ (0.1,0) [0|0] "" Vector__XXX
 SG_ BMS_cacRawEstimateBrick62 m61 : 48|13@1+ (0.1,0) [0|0] "" Vector__XXX
 SG_ BMS_cacRawEstimateBrick63 m62 : 48|13@1+ (0.1,0) [0|0] "" Vector__XXX
 SG_ BMS_cacRawEstimateBrick64 m63 : 48|13@1+ (0.1,0) [0|0] "" Vector__XXX
 SG_ BMS_cacRawEstimateBrick65 m64 : 48|13@1+ (0.1,0) [0|0] "" Vector__XXX
 SG_ BMS_cacRawEstimateBrick66 m65 : 48|13@1+ (0.1,0) [0|0] "" Vector__XXX
 SG_ BMS_cacRawEstimateBrick67 m66 : 48|13@1+ (0.1,0) [0|0] "" Vector__XXX
 SG_ BMS_cacRawEstimateBrick68 m67 : 48|13@1+ (0.1,0) [0|0] "" Vector__XXX
 SG_ BMS_cacRawEstimateBrick69 m68 : 48|13@1+ (0.1,0) [0|0] "" Vector__XXX
 SG_ BMS_cacRawEstimateBrick7 m6 : 48|13@1+ (0.1,0) [0|0] "" Vector__XXX
 SG_ BMS_cacRawEstimateBrick70 m69 : 48|13@1+ (0.1,0) [0|0] "" Vector__XXX
 SG_ BMS_cacRawEstimateBrick71 m70 : 48|13@1+ (0.1,0) [0|0] "" Vector__XXX
 SG_ BMS_cacRawEstimateBrick72 m71 : 48|13@1+ (0.1,0) [0|0] "" Vector__XXX
 SG_ BMS_cacRawEstimateBrick73 m72 : 48|13@1+ (0.1,0) [0|0] "" Vector__XXX
 SG_ BMS_cacRawEstimateBrick74 m73 : 48|13@1+ (0.1,0) [0|0] "" Vector__XXX
 SG_ BMS_cacRawEstimateBrick75 m74 : 48|13@1+ (0.1,0) [0|0] "" Vector__XXX
 SG_ BMS_cacRawEstimateBrick76 m75 : 48|13@1+ (0.1,0) [0|0] "" Vector__XXX
 SG_ BMS_cacRawEstimateBrick77 m76 : 48|13@1+ (0.1,0) [0|0] "" Vector__XXX
 SG_ BMS_cacRawEstimateBrick78 m77 : 48|13@1+ (0.1,0) [0|0] "" Vector__XXX
 SG_ BMS_cacRawEstimateBrick79 m78 : 48|13@1+ (0.1,0) [0|0] "" Vector__XXX
 SG_ BMS_cacRawEstimateBrick8 m7 : 48|13@1+ (0.1,0) [0|0] "" Vector__XXX
 SG_ BMS_cacRawEstimateBrick80 m79 : 48|13@1+ (0.1,0) [0|0] "" Vector__XXX
 SG_ BMS_cacRawEstimateBrick81 m80 : 48|13@1+ (0.1,0) [0|0] "" Vector__XXX
 SG_ BMS_cacRawEstimateBrick82 m81 : 48|13@1+ (0.1,0) [0|0] "" Vector__XXX
 SG_ BMS_cacRawEstimateBrick83 m82 : 48|13@1+ (0.1,0) [0|0] "" Vector__XXX
 SG_ BMS_cacRawEstimateBrick84 m83 : 48|13@1+ (0.1,0) [0|0] "" Vector__XXX
 SG_ BMS_cacRawEstimateBrick85 m84 : 48|13@1+ (0.1,0) [0|0] "" Vector__XXX
 SG_ BMS_cacRawEstimateBrick86 m85 : 48|13@1+ (0.1,0) [0|0] "" Vector__XXX
 SG_ BMS_cacRawEstimateBrick87 m86 : 48|13@1+ (0.1,0) [0|0] "" Vector__XXX
 SG_ BMS_cacRawEstimateBrick88 m87 : 48|13@1+ (0.1,0) [0|0] "" Vector__XXX
 SG_ BMS_cacRawEstimateBrick89 m88 : 48|13@1+ (0.1,0) [0|0] "" Vector__XXX
 SG_ BMS_cacRawEstimateBrick9 m8 : 48|13@1+ (0.1,0) [0|0] "" Vector__XXX
 SG_ BMS_cacRawEstimateBrick90 m89 : 48|13@1+ (0.1,0) [0|0] "" Vector__XXX
 SG_ BMS_cacRawEstimateBrick91 m90 : 48|13@1+ (0.1,0) [0|0] "" Vector__XXX
 SG_ BMS_cacRawEstimateBrick92 m91 : 48|13@1+ (0.1,0) [0|0] "" Vector__XXX
 SG_ BMS_cacRawEstimateBrick93 m92 : 48|13@1+ (0.1,0) [0|0] "" Vector__XXX
 SG_ BMS_cacRawEstimateBrick94 m93 : 48|13@1+ (0.1,0) [0|0] "" Vector__XXX
 SG_ BMS_cacRawEstimateBrick95 m94 : 48|13@1+ (0.1,0) [0|0] "" Vector__XXX
 SG_ BMS_cacRawEstimateBrick96 m95 : 48|13@1+ (0.1,0) [0|0] "" Vector__XXX
 SG_ BMS_cacRawEstimateBrick97 m96 : 48|13@1+ (0.1,0) [0|0] "" Vector__XXX
 SG_ BMS_cacRawEstimateBrick98 m97 : 48|13@1+ (0.1,0) [0|0] "" Vector__XXX
 SG_ BMS_cacRawEstimateBrick99 m98 : 48|13@1+ (0.1,0) [0|0] "" Vector__XXX

BO_ 1924 XCP_pmfRequest: 8 Vector__XXX
 SG_ XCP_pmfRequestData : 7|64@0+ (1,0) [0|0] "" Vector__XXX

BO_ 1926 DBG_dynoVehicleSim: 8 Vector__XXX
 SG_ DBG_vehicleSpeed : 0|12@1+ (0.08,-40) [0|0] "" Vector__XXX
 SG_ DBG_wheelSpeedFrL : 12|12@1+ (0.08,-40) [0|0] "" Vector__XXX
 SG_ DBG_wheelSpeedFrR : 24|12@1+ (0.08,-40) [0|0] "" Vector__XXX
 SG_ DBG_wheelSpeedReL : 36|12@1+ (0.08,-40) [0|0] "" Vector__XXX
 SG_ DBG_wheelSpeedReR : 48|12@1+ (0.08,-40) [0|0] "" Vector__XXX

BO_ 1928 EPBL_debugOutput: 8 Vector__XXX
 SG_ EPBL_debugOutputIndex M : 0|2@1+ (1,0) [0|0] "" Vector__XXX
 SG_ EPBL_12VFilt_SW m0 : 2|9@1+ (0.043549408784,0) [0|0] "" Vector__XXX
 SG_ EPBL_limpToDecelTimer m2 : 2|10@1+ (1,0) [0|0] "" Vector__XXX
 SG_ EPBL_pid_uP m1 : 2|10@1- (0.2,0) [0|0] "" Vector__XXX
 SG_ EPBL_nvFilt m0 : 11|9@1+ (0.043549408784,0) [0|0] "" Vector__XXX
 SG_ EPBL_emergencyOperationMode m2 : 12|2@1+ (1,0) [0|0] "" Vector__XXX
 SG_ EPBL_pid_uI m1 : 12|10@1- (0.2,0) [0|0] "" Vector__XXX
 SG_ EPBL_dynamicManagerReady m2 : 14|1@1+ (1,0) [0|0] "" Vector__XXX
 SG_ EPBL_driverLockedOut m2 : 15|1@1+ (1,0) [0|0] "" Vector__XXX
 SG_ EPBL_currentOffset m2 : 16|12@1+ (0.016997132,-37.55274262) [0|0] "" Vector__XXX
 SG_ EPBL_pvFilt m0 : 20|9@1+ (0.043549408784,0) [0|0] "" Vector__XXX
 SG_ EPBL_pid_duty m1 : 22|10@1- (0.2,0) [0|0] "" Vector__XXX
 SG_ EPBL_filteredCurrentPeak m2 : 28|12@1+ (0.01,0) [0|0] "" Vector__XXX
 SG_ EPBL_caliperState m0 : 29|3@1+ (1,0) [0|0] "" Vector__XXX
 SG_ EPBL_nFault m0 : 32|1@1+ (1,0) [0|0] "" Vector__XXX
 SG_ EPBL_ramp m1 : 32|8@1+ (0.392157,0) [0|0] "" Vector__XXX
 SG_ EPBL_oocViolation m0 : 33|1@1+ (1,0) [0|0] "" Vector__XXX
 SG_ EPBL_atEndStop m0 : 34|1@1+ (1,0) [0|0] "" Vector__XXX
 SG_ EPBL_currentVariance m0 : 35|14@1- (0.0007629394535064697,0) [0|0] "" Vector__XXX
 SG_ EPBL_lockoutOutputDI m2 : 40|1@1+ (1,0) [0|0] "" Vector__XXX
 SG_ EPBL_pid_error m1 : 40|12@1+ (0.016997132,-37.55274262) [0|0] "" Vector__XXX
 SG_ EPBL_lockoutCommandDI m2 : 41|1@1+ (1,0) [0|0] "" Vector__XXX
 SG_ EPBL_brakeDiscWipeAccumul m2 : 48|8@1+ (1,0) [0|0] "" Vector__XXX
 SG_ EPBL_lockoutUnlockCount m0 : 49|6@1+ (1,0) [0|0] "" Vector__XXX
 SG_ EPBL_12VFilt m1 : 52|9@1+ (0.043549408784,0) [0|0] "" Vector__XXX
 SG_ EPBL_esmCaliperRequest m0 : 55|3@1+ (1,0) [0|0] "" Vector__XXX
 SG_ EPBL_brakePressHeld m0 : 58|1@1+ (1,0) [0|0] "" Vector__XXX
 SG_ EPBL_epbOpenUnableToPark m0 : 59|1@1+ (1,0) [0|0] "" Vector__XXX
 SG_ EPBL_slopeParkable m0 : 60|1@1+ (1,0) [0|0] "" Vector__XXX
 SG_ EPBL_uiNotAvailable m0 : 61|1@1+ (1,0) [0|0] "" Vector__XXX

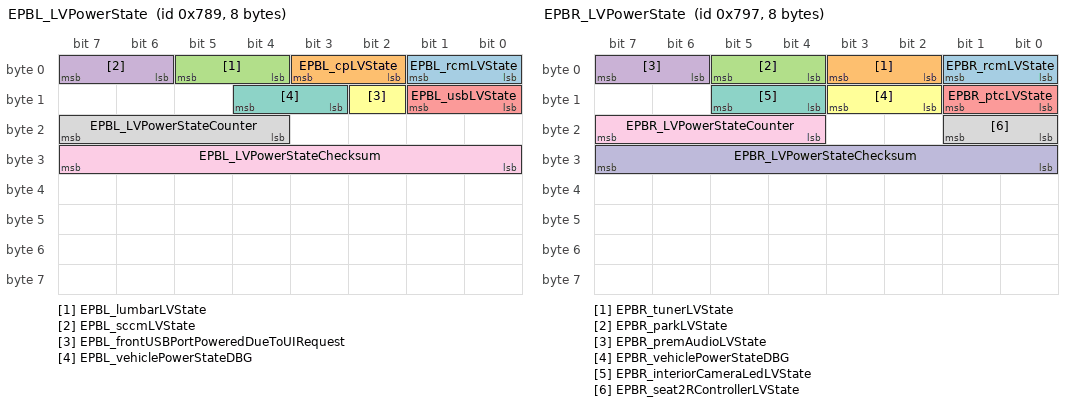
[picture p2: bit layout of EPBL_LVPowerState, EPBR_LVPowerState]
BO_ 1929 EPBL_LVPowerState: 8 Vector__XXX
 SG_ EPBL_rcmLVState : 0|2@1+ (1,0) [0|0] "" Vector__XXX
 SG_ EPBL_cpLVState : 2|2@1+ (1,0) [0|0] "" Vector__XXX
 SG_ EPBL_lumbarLVState : 4|2@1+ (1,0) [0|0] "" Vector__XXX
 SG_ EPBL_sccmLVState : 6|2@1+ (1,0) [0|0] "" Vector__XXX
 SG_ EPBL_usbLVState : 8|2@1+ (1,0) [0|0] "" Vector__XXX
 SG_ EPBL_frontUSBPortPoweredDueToUIRequest : 10|1@1+ (1,0) [0|0] "" Vector__XXX
 SG_ EPBL_vehiclePowerStateDBG : 11|2@1+ (1,0) [0|0] "" Vector__XXX
 SG_ EPBL_LVPowerStateCounter : 20|4@1+ (1,0) [0|0] "" Vector__XXX
 SG_ EPBL_LVPowerStateChecksum : 24|8@1+ (1,0) [0|0] "" Vector__XXX

BO_ 1930 HVP_pyroDeviceDbg: 8 Vector__XXX
 SG_ HVP_pyroStatus : 0|2@1+ (1,0) [0|0] "" Vector__XXX
 SG_ HVP_pyroTestRefCurrentFailed : 2|1@1+ (1,0) [0|0] "" Vector__XXX
 SG_ HVP_pyroTestSquibResFailed : 3|1@1+ (1,0) [0|0] "" Vector__XXX
 SG_ HVP_pyroTestErFailed : 4|1@1+ (1,0) [0|0] "" Vector__XXX
 SG_ HVP_pyroTestVstFailed : 5|1@1+ (1,0) [0|0] "" Vector__XXX
 SG_ HVP_pyroTestHighSideSwitchFailed : 6|1@1+ (1,0) [0|0] "" Vector__XXX
 SG_ HVP_pyroTestLowSideSwitchFailed : 7|1@1+ (1,0) [0|0] "" Vector__XXX
 SG_ HVP_pyroTestPyroLeakFailed : 8|1@1+ (1,0) [0|0] "" Vector__XXX
 SG_ HVP_pyroSquibFired : 9|1@1+ (1,0) [0|0] "" Vector__XXX
 SG_ HVP_pyroFiringHandle : 10|4@1+ (1,0) [0|0] "" Vector__XXX
 SG_ HVP_pyroAoutMultiplexer M : 16|3@1+ (1,0) [0|0] "" Vector__XXX
 SG_ HVP_pyroAoutEr1 m1 : 32|16@1+ (0.001,0) [0|0] "" Vector__XXX
 SG_ HVP_pyroAoutHighsideSwitchIgh1 m5 : 32|16@1+ (0.001,0) [0|0] "" Vector__XXX
 SG_ HVP_pyroAoutLeakIgh1 m2 : 32|16@1+ (0.001,0) [0|0] "" Vector__XXX
 SG_ HVP_pyroAoutLowsideSwitchIgl1 m6 : 32|16@1+ (0.001,0) [0|0] "" Vector__XXX
 SG_ HVP_pyroAoutRm m3 : 32|16@1+ (0.001,0) [0|0] "" Vector__XXX
 SG_ HVP_pyroAoutSquibResIgh1 m4 : 32|16@1+ (0.001,0) [0|0] "" Vector__XXX
 SG_ HVP_pyroAoutVst1 m0 : 32|16@1+ (0.001,0) [0|0] "" Vector__XXX
 SG_ HVP_pyroAoutEr2 m1 : 48|16@1+ (0.001,0) [0|0] "" Vector__XXX
 SG_ HVP_pyroAoutGnd m5 : 48|16@1+ (0.001,0) [0|0] "" Vector__XXX
 SG_ HVP_pyroAoutLeakIgl1 m2 : 48|16@1+ (0.001,0) [0|0] "" Vector__XXX
 SG_ HVP_pyroAoutRref m3 : 48|16@1+ (0.001,0) [0|0] "" Vector__XXX
 SG_ HVP_pyroAoutSquibResIgl1 m4 : 48|16@1+ (0.001,0) [0|0] "" Vector__XXX
 SG_ HVP_pyroAoutVst2 m0 : 48|16@1+ (0.001,0) [0|0] "" Vector__XXX

BO_ 1931 EPBL_xcpResponse: 8 Vector__XXX
 SG_ EPBL_xcpResponse : 7|64@0+ (1,0) [0|0] "" Vector__XXX

BO_ 1932 EPBR_xcpResponse: 8 Vector__XXX
 SG_ EPBR_xcpResponse : 7|64@0+ (1,0) [0|0] "" Vector__XXX

BO_ 1940 PMF_xcpResponse: 8 Vector__XXX
 SG_ PMF_xcpResponseData : 7|64@0+ (1,0) [0|0] "" Vector__XXX

BO_ 1942 DIF_xcpResponse: 8 Vector__XXX
 SG_ DIF_xcpResponseData : 7|64@0+ (1,0) [0|0] "" Vector__XXX

BO_ 1943 EPBR_LVPowerState: 8 Vector__XXX
 SG_ EPBR_rcmLVState : 0|2@1+ (1,0) [0|0] "" Vector__XXX
 SG_ EPBR_tunerLVState : 2|2@1+ (1,0) [0|0] "" Vector__XXX
 SG_ EPBR_parkLVState : 4|2@1+ (1,0) [0|0] "" Vector__XXX
 SG_ EPBR_premAudioLVState : 6|2@1+ (1,0) [0|0] "" Vector__XXX
 SG_ EPBR_ptcLVState : 8|2@1+ (1,0) [0|0] "" Vector__XXX
 SG_ EPBR_vehiclePowerStateDBG : 10|2@1+ (1,0) [0|0] "" Vector__XXX
 SG_ EPBR_interiorCameraLedLVState : 12|2@1+ (1,0) [0|0] "" Vector__XXX
 SG_ EPBR_seat2RControllerLVState : 16|2@1+ (1,0) [0|0] "" Vector__XXX
 SG_ EPBR_LVPowerStateCounter : 20|4@1+ (1,0) [0|0] "" Vector__XXX
 SG_ EPBR_LVPowerStateChecksum : 24|8@1+ (1,0) [0|0] "" Vector__XXX

BO_ 1944 EPBL_remoteADC: 8 Vector__XXX
 SG_ EPBL_remoteADCIndex M : 0|3@1+ (1,0) [0|0] "" Vector__XXX
 SG_ EPBL_PCBATemp m4 : 3|10@1+ (0.0009775171065493646,0) [0|0] "" Vector__XXX
 SG_ EPBL_efuseContinousMonitor m1 : 3|10@1+ (0.017595307917888565,0) [0|0] "" Vector__XXX
 SG_ EPBL_frontCushionTemp m3 : 3|10@1+ (0.0009775171065493646,0) [0|0] "" Vector__XXX
 SG_ EPBL_seatFrontBackRestUpMonitor m2 : 3|10@1+ (0.017595307917888565,0) [0|0] "" Vector__XXX
 SG_ EPBL_trailerAuxMonitor m6 : 3|10@1+ (0.017595307917888565,0) [0|0] "" Vector__XXX
 SG_ EPBL_windowLiftFrontUpMonitor m0 : 3|10@1+ (0.017595307917888565,0) [0|0] "" Vector__XXX
 SG_ EPBL_2ndRowRightCushionTemp m3 : 13|10@1+ (0.0009775171065493646,0) [0|0] "" Vector__XXX
 SG_ EPBL_BLEMonitor m4 : 13|10@1+ (0.017595307917888565,0) [0|0] "" Vector__XXX
 SG_ EPBL_efuseNonContinuousMonitor m1 : 13|10@1+ (0.017595307917888565,0) [0|0] "" Vector__XXX
 SG_ EPBL_mirrorDimMonitor m2 : 13|10@1+ (0.004887585532746823,0) [0|0] "" Vector__XXX
 SG_ EPBL_windowLiftRearDownMonitor m0 : 13|10@1+ (0.017595307917888565,0) [0|0] "" Vector__XXX
 SG_ EPBL_2ndRowCenterCushionTemp m3 : 24|10@1+ (0.0009775171065493646,0) [0|0] "" Vector__XXX
 SG_ EPBL_accessoryFeedAlwaysOnMonitor m2 : 24|10@1+ (0.017595307917888565,0) [0|0] "" Vector__XXX
 SG_ EPBL_liftGateStrutCloseMonitor m1 : 24|10@1+ (0.017595307917888565,0) [0|0] "" Vector__XXX
 SG_ EPBL_seatFrontLiftUpMonitor m0 : 24|10@1+ (0.017595307917888565,0) [0|0] "" Vector__XXX
 SG_ EPBL_securityControllerMonitor m4 : 24|10@1+ (0.017595307917888565,0) [0|0] "" Vector__XXX
 SG_ EPBL_2ndRowLeftCushionTemp m3 : 34|10@1+ (0.0009775171065493646,0) [0|0] "" Vector__XXX
 SG_ EPBL_chargePortMonitor m4 : 34|10@1+ (0.017595307917888565,0) [0|0] "" Vector__XXX
 SG_ EPBL_liftGateStrutOpenMonitor m1 : 34|10@1+ (0.017595307917888565,0) [0|0] "" Vector__XXX
 SG_ EPBL_seatFrontTiltUpMonitor m0 : 34|10@1+ (0.017595307917888565,0) [0|0] "" Vector__XXX
 SG_ EPBL_steeringColumnUpMonitor m2 : 34|10@1+ (0.017595307917888565,0) [0|0] "" Vector__XXX
 SG_ EPBL_remoteADCCounter : 52|4@1+ (1,0) [0|0] "" Vector__XXX
 SG_ EPBL_remoteADCChecksum : 56|8@1+ (1,0) [0|0] "" Vector__XXX

BO_ 1945 DI_xcpResponse: 8 Vector__XXX
 SG_ DI_xcpResponseData : 7|64@0+ (1,0) [0|0] "" Vector__XXX

BO_ 1947 XCP_epblRequest: 8 Vector__XXX
 SG_ XCP_epblRequest : 7|64@0+ (1,0) [0|0] "" Vector__XXX

BO_ 1948 XCP_epbrRequest: 8 Vector__XXX
 SG_ XCP_epbrRequest : 7|64@0+ (1,0) [0|0] "" Vector__XXX

BO_ 1949 V2G_evseLogData: 8 Vector__XXX
 SG_ V2G_evseLogDataSelect M : 0|5@1+ (1,0) [0|0] "" Vector__XXX
 SG_ V2G_currDemRes_isoState_val m13 : 5|1@1+ (1,0) [0|0] "" Vector__XXX
 SG_ V2G_currDemRes_respCode m11 : 5|5@1+ (1,0) [0|0] "" Vector__XXX
 SG_ V2G_suppAppProtocolRes_respCode m0 : 5|2@1+ (1,0) [0|0] "" Vector__XXX
 SG_ V2G_cableCheckRes_respCode m8 : 8|5@1+ (1,0) [0|0] "" Vector__XXX
 SG_ V2G_chargingStatusRes_respCode m12 : 8|5@1+ (1,0) [0|0] "" Vector__XXX
 SG_ V2G_chgParamRes_respCode m7 : 8|5@1+ (1,0) [0|0] "" Vector__XXX
 SG_ V2G_contractAuthRes_respCode m6 : 8|5@1+ (1,0) [0|0] "" Vector__XXX
 SG_ V2G_paymentDetailsRes_respCode m5 : 8|5@1+ (1,0) [0|0] "" Vector__XXX
 SG_ V2G_powerDelEndRes_respCode m13 : 8|5@1+ (1,0) [0|0] "" Vector__XXX
 SG_ V2G_powerDelStartRes_respCode m10 : 8|5@1+ (1,0) [0|0] "" Vector__XXX
 SG_ V2G_prechargeRes_respCode m9 : 8|5@1+ (1,0) [0|0] "" Vector__XXX
 SG_ V2G_serviceDetailRes_respCode m3 : 8|5@1+ (1,0) [0|0] "" Vector__XXX
 SG_ V2G_serviceDiscoveryRes_respCode m2 : 8|5@1+ (1,0) [0|0] "" Vector__XXX
 SG_ V2G_servicePaymntSelRes_respCode m4 : 8|5@1+ (1,0) [0|0] "" Vector__XXX
 SG_ V2G_sessionSetupRes_respCode m1 : 8|5@1+ (1,0) [0|0] "" Vector__XXX
 SG_ V2G_sessionStopRes_respCode m14 : 8|5@1+ (1,0) [0|0] "" Vector__XXX
 SG_ V2G_suppAppProtocolRes_schemaId m0 : 8|8@1+ (1,0) [0|0] "" Vector__XXX
 SG_ V2G_currDemRes_evseStatus m11 : 10|4@1+ (1,0) [0|0] "" Vector__XXX
 SG_ V2G_cableCheckRes_finished m8 : 13|1@1+ (1,0) [0|0] "" Vector__XXX
 SG_ V2G_chgParamRes_finished m7 : 13|1@1+ (1,0) [0|0] "" Vector__XXX
 SG_ V2G_contractAuthRes_finished m6 : 13|1@1+ (1,0) [0|0] "" Vector__XXX
 SG_ V2G_serviceDiscRes_extPayAvail m2 : 13|1@1+ (1,0) [0|0] "" Vector__XXX
 SG_ V2G_chgParamRes_evseStatus m7 : 14|4@1+ (1,0) [0|0] "" Vector__XXX
 SG_ V2G_currDemRes_outputV m11 : 14|10@1+ (1.171875,0) [0|0] "" Vector__XXX
 SG_ V2G_serviceDiscRes_pncAvail m2 : 14|1@1+ (1,0) [0|0] "" Vector__XXX
 SG_ V2G_serviceDiscRes_evChgAvail m2 : 15|1@1+ (1,0) [0|0] "" Vector__XXX
 SG_ V2G_cableCheckRes_evseStatus m8 : 16|4@1+ (1,0) [0|0] "" Vector__XXX
 SG_ V2G_chargingStatusRes_maxI m12 : 16|7@1+ (1,0) [0|0] "" Vector__XXX
 SG_ V2G_powerDelEndRes_evseStatus m13 : 16|4@1+ (1,0) [0|0] "" Vector__XXX
 SG_ V2G_powerDelStartRes_evseStatus m10 : 16|4@1+ (1,0) [0|0] "" Vector__XXX
 SG_ V2G_prechargeRes_evseStatus m9 : 16|4@1+ (1,0) [0|0] "" Vector__XXX
 SG_ V2G_serviceDiscRes_dcExtended m2 : 16|1@1+ (1,0) [0|0] "" Vector__XXX
 SG_ V2G_chgParamRes_evseMaxILim m7 : 18|8@1+ (7.032,0) [0|0] "" Vector__XXX
 SG_ V2G_cableCheckRes_isoState m8 : 20|3@1+ (1,0) [0|0] "" Vector__XXX
 SG_ V2G_prechargeRes_outputV m9 : 20|10@1+ (1.171875,0) [0|0] "" Vector__XXX
 SG_ V2G_pwrDelEndRes_isoState m13 : 20|3@1+ (1,0) [0|0] "" Vector__XXX
 SG_ V2G_pwrDelStartRes_isoState m10 : 20|3@1+ (1,0) [0|0] "" Vector__XXX
 SG_ V2G_cableCheckRes_isoState_val m8 : 23|1@1+ (1,0) [0|0] "" Vector__XXX
 SG_ V2G_chargingStatusRes_maxI_val m12 : 23|1@1+ (1,0) [0|0] "" Vector__XXX
 SG_ V2G_pwrDelEndRes_isoState_val m13 : 23|1@1+ (1,0) [0|0] "" Vector__XXX
 SG_ V2G_pwrDelStartRes_isoState_val m10 : 23|1@1+ (1,0) [0|0] "" Vector__XXX
 SG_ V2G_chargingStatusRes_rcd m12 : 24|1@1+ (1,0) [0|0] "" Vector__XXX
 SG_ V2G_currDemRes_outputI m11 : 24|10@1+ (1.7578125,0) [0|0] "" Vector__XXX
 SG_ V2G_chgParamRes_evseMaxVLim m7 : 26|8@1+ (4.688,0) [0|0] "" Vector__XXX
 SG_ V2G_prechargeRes_isoState m9 : 32|3@1+ (1,0) [0|0] "" Vector__XXX
 SG_ V2G_chgParamRes_evseMinILim m7 : 34|8@1+ (7.032,0) [0|0] "" Vector__XXX
 SG_ V2G_currDemRes_evseMaxILim m11 : 34|8@1+ (7.032,0) [0|0] "" Vector__XXX
 SG_ V2G_prechargeRes_isoState_val m9 : 35|1@1+ (1,0) [0|0] "" Vector__XXX
 SG_ V2G_chgParamRes_evseMinVLim m7 : 42|8@1+ (4.688,0) [0|0] "" Vector__XXX
 SG_ V2G_currDemRes_evseMaxILim_val m11 : 42|1@1+ (1,0) [0|0] "" Vector__XXX
 SG_ V2G_currDemRes_evseMaxVLim m11 : 43|8@1+ (4.688,0) [0|0] "" Vector__XXX
 SG_ V2G_chgParamRes_evseMaxPowerLim m7 : 50|8@1+ (5.9766,0) [0|0] "" Vector__XXX
 SG_ V2G_currDemRes_evseMaxVLim_val m11 : 51|1@1+ (1,0) [0|0] "" Vector__XXX
 SG_ V2G_currDemRes_evseMaxPowerLim m11 : 52|8@1+ (5.9766,0) [0|0] "" Vector__XXX
 SG_ V2G_chgParamRes_evseMaxPower_val m7 : 58|1@1+ (1,0) [0|0] "" Vector__XXX
 SG_ V2G_chgParamRes_isoState m7 : 59|3@1+ (1,0) [0|0] "" Vector__XXX
 SG_ V2G_currDemRes_evseMaxPower_val m11 : 60|1@1+ (1,0) [0|0] "" Vector__XXX
 SG_ V2G_currDemRes_isoState m11 : 61|3@1+ (1,0) [0|0] "" Vector__XXX
 SG_ V2G_chgParamRes_isoState_val m7 : 62|1@1+ (1,0) [0|0] "" Vector__XXX

BO_ 1951 ADSP_audioVisualizer: 8 Vector__XXX
 SG_ ADSP_audioVisualizerBrightness : 0|8@1+ (1,0) [0|0] "" Vector__XXX

BO_ 1960 EPBR_debugOutput: 8 Vector__XXX
 SG_ EPBR_debugOutputIndex M : 0|2@1+ (1,0) [0|0] "" Vector__XXX
 SG_ EPBR_12VFilt_SW m0 : 2|9@1+ (0.043549408784,0) [0|0] "" Vector__XXX
 SG_ EPBR_limpToDecelTimer m2 : 2|10@1+ (1,0) [0|0] "" Vector__XXX
 SG_ EPBR_pid_uP m1 : 2|10@1- (0.2,0) [0|0] "" Vector__XXX
 SG_ EPBR_nvFilt m0 : 11|9@1+ (0.043549408784,0) [0|0] "" Vector__XXX
 SG_ EPBR_emergencyOperationMode m2 : 12|2@1+ (1,0) [0|0] "" Vector__XXX
 SG_ EPBR_pid_uI m1 : 12|10@1- (0.2,0) [0|0] "" Vector__XXX
 SG_ EPBR_dynamicManagerReady m2 : 14|1@1+ (1,0) [0|0] "" Vector__XXX
 SG_ EPBR_driverLockedOut m2 : 15|1@1+ (1,0) [0|0] "" Vector__XXX
 SG_ EPBR_currentOffset m2 : 16|12@1+ (0.016997132,-37.55274262) [0|0] "" Vector__XXX
 SG_ EPBR_pvFilt m0 : 20|9@1+ (0.043549408784,0) [0|0] "" Vector__XXX
 SG_ EPBR_pid_duty m1 : 22|10@1- (0.2,0) [0|0] "" Vector__XXX
 SG_ EPBR_filteredCurrentPeak m2 : 28|12@1+ (0.01,0) [0|0] "" Vector__XXX
 SG_ EPBR_caliperState m0 : 29|3@1+ (1,0) [0|0] "" Vector__XXX
 SG_ EPBR_nFault m0 : 32|1@1+ (1,0) [0|0] "" Vector__XXX
 SG_ EPBR_ramp m1 : 32|8@1+ (0.392157,0) [0|0] "" Vector__XXX
 SG_ EPBR_oocViolation m0 : 33|1@1+ (1,0) [0|0] "" Vector__XXX
 SG_ EPBR_atEndStop m0 : 34|1@1+ (1,0) [0|0] "" Vector__XXX
 SG_ EPBR_currentVariance m0 : 35|14@1- (0.0007629394535064697,0) [0|0] "" Vector__XXX
 SG_ EPBR_lockoutOutContactor m2 : 40|1@1+ (1,0) [0|0] "" Vector__XXX
 SG_ EPBR_pid_error m1 : 40|12@1+ (0.016997132,-37.55274262) [0|0] "" Vector__XXX
 SG_ EPBR_lockoutCmdContactor m2 : 41|1@1+ (1,0) [0|0] "" Vector__XXX
 SG_ EPBR_lockoutOutputHVC m2 : 42|1@1+ (1,0) [0|0] "" Vector__XXX
 SG_ EPBR_lockoutCommandHVC m2 : 43|1@1+ (1,0) [0|0] "" Vector__XXX
 SG_ EPBR_brakeDiscWipeAccumul m2 : 48|8@1+ (1,0) [0|0] "" Vector__XXX
 SG_ EPBR_lockoutUnlockCount m0 : 49|6@1+ (1,0) [0|0] "" Vector__XXX
 SG_ EPBR_12VFilt m1 : 52|9@1+ (0.043549408784,0) [0|0] "" Vector__XXX
 SG_ EPBR_esmCaliperRequest m0 : 55|3@1+ (1,0) [0|0] "" Vector__XXX
 SG_ EPBR_brakePressHeld m0 : 58|1@1+ (1,0) [0|0] "" Vector__XXX
 SG_ EPBR_epbOpenUnableToPark m0 : 59|1@1+ (1,0) [0|0] "" Vector__XXX
 SG_ EPBR_slopeParkable m0 : 60|1@1+ (1,0) [0|0] "" Vector__XXX
 SG_ EPBR_uiNotAvailable m0 : 61|1@1+ (1,0) [0|0] "" Vector__XXX

BO_ 1962 HVP_debugMessage: 8 Vector__XXX
 SG_ HVP_debugMessageMultiplexer M : 0|4@1+ (1,0) [0|0] "" Vector__XXX
 SG_ HVP_bmbStaleFrameRate m8 : 4|10@1+ (0.1,0) [0|0] "" Vector__XXX
 SG_ HVP_ecuLogUploadRequest m1 : 4|2@1+ (1,0) [0|0] "" Vector__XXX
 SG_ HVP_fcContCoilCurrent m4 : 4|12@1+ (0.1,0) [0|0] "" Vector__XXX
 SG_ HVP_gpioPassivePyroDepl m0 : 4|1@1+ (1,0) [0|0] "" Vector__XXX
 SG_ HVP_packContVoltage m2 : 4|12@1+ (0.1,0) [0|0] "" Vector__XXX
 SG_ HVP_passivePyroRefVoltageMax m5 : 4|10@1+ (0.001,0.7) [0|0] "" Vector__XXX
 SG_ HVP_shuntAuxCurrentDbg m6 : 4|16@1- (0.1,0) [0|0] "" Vector__XXX
 SG_ HVP_shuntCompensationMode m3 : 4|2@1+ (1,0) [0|0] "" Vector__XXX
 SG_ HVP_gpioPyroIsoEn m0 : 5|1@1+ (1,0) [0|0] "" Vector__XXX
 SG_ HVP_gpioCpFaultIn m0 : 6|1@1+ (1,0) [0|0] "" Vector__XXX
 SG_ HVP_gpioPackContPowerEn m0 : 7|1@1+ (1,0) [0|0] "" Vector__XXX
 SG_ HVP_100HzTask_avgExecTime m11 : 8|16@1+ (10,0) [0|0] "" Vector__XXX
 SG_ HVP_10HzTask_maxExecTime m10 : 8|16@1+ (10,0) [0|0] "" Vector__XXX
 SG_ HVP_1HzTask_maxExecTime m9 : 8|16@1+ (10,0) [0|0] "" Vector__XXX
 SG_ HVP_bmbStaleFrameCount m12 : 8|16@1+ (1,0) [0|0] "" Vector__XXX
 SG_ HVP_dcLinkNegativeV m3 : 8|16@1- (0.1,0) [0|0] "" Vector__XXX
 SG_ HVP_dcLinkVoltage m1 : 8|16@1- (0.1,0) [0|0] "" Vector__XXX
 SG_ HVP_gpioHvCablesOk m0 : 8|1@1+ (1,0) [0|0] "" Vector__XXX
 SG_ HVP_shuntCurrentRawDbg m7 : 8|16@1- (0.1,0) [0|0] "" Vector__XXX
 SG_ HVP_gpioHvpSelfEnable m0 : 9|1@1+ (1,0) [0|0] "" Vector__XXX
 SG_ HVP_gpioLed m0 : 10|1@1+ (1,0) [0|0] "" Vector__XXX
 SG_ HVP_gpioCrashSignal m0 : 11|1@1+ (1,0) [0|0] "" Vector__XXX
 SG_ HVP_gpioShuntDataReady m0 : 12|1@1+ (1,0) [0|0] "" Vector__XXX
 SG_ HVP_gpioFcContPosAux m0 : 13|1@1+ (1,0) [0|0] "" Vector__XXX
 SG_ HVP_bmbCrcFailedFrameRate m8 : 14|10@1+ (0.1,0) [0|0] "" Vector__XXX
 SG_ HVP_gpioFcContNegAux m0 : 14|1@1+ (1,0) [0|0] "" Vector__XXX
 SG_ HVP_passivePyroRefVoltageMin m5 : 14|10@1+ (0.001,0.7) [0|0] "" Vector__XXX
 SG_ HVP_gpioBmsEout m0 : 15|1@1+ (1,0) [0|0] "" Vector__XXX
 SG_ HVP_fcContVoltage m4 : 16|12@1+ (0.1,0) [0|0] "" Vector__XXX
 SG_ HVP_gpioCpFaultOut m0 : 16|1@1+ (1,0) [0|0] "" Vector__XXX
 SG_ HVP_packNegativeV m2 : 16|16@1- (0.1,0) [0|0] "" Vector__XXX
 SG_ HVP_gpioPyroPor m0 : 17|1@1+ (1,0) [0|0] "" Vector__XXX
 SG_ HVP_gpioShuntEn m0 : 18|1@1+ (1,0) [0|0] "" Vector__XXX
 SG_ HVP_gpioHvpVerEn m0 : 19|1@1+ (1,0) [0|0] "" Vector__XXX
 SG_ HVP_gpioFcContFlywheelEnable m0 : 20|1@1+ (1,0) [0|0] "" Vector__XXX
 SG_ HVP_shuntBarTempDbg m6 : 20|16@1- (0.01,0) [0|0] "" Vector__XXX
 SG_ HVP_gpioCpLatchEnable m0 : 21|1@1+ (1,0) [0|0] "" Vector__XXX
 SG_ HVP_gpioFcContPowerEnable m0 : 22|1@1+ (1,0) [0|0] "" Vector__XXX
 SG_ HVP_gpioHvilEnable m0 : 23|1@1+ (1,0) [0|0] "" Vector__XXX
 SG_ HVP_10HzTask_avgExecTime m10 : 24|16@1+ (10,0) [0|0] "" Vector__XXX
 SG_ HVP_1HzTask_avgExecTime m9 : 24|16@1+ (10,0) [0|0] "" Vector__XXX
 SG_ HVP_1kHzTask_cpuUsage m11 : 24|7@1+ (1,0) [0|0] "" Vector__XXX
 SG_ HVP_bmbCrcFailedFrameCount m12 : 24|16@1+ (1,0) [0|0] "" Vector__XXX
 SG_ HVP_bmbSnaFrameRate m8 : 24|10@1+ (0.1,0) [0|0] "" Vector__XXX
 SG_ HVP_dcLinkPositiveV m3 : 24|16@1- (0.1,0) [0|0] "" Vector__XXX
 SG_ HVP_gpioPortSelSpiRdy m0 : 24|1@1+ (1,0) [0|0] "" Vector__XXX
 SG_ HVP_packContCoilCurrent m5 : 24|12@1+ (0.1,0) [0|0] "" Vector__XXX
 SG_ HVP_packVoltage m1 : 24|16@1- (0.1,0) [0|0] "" Vector__XXX
 SG_ HVP_shuntCurrentDbg m7 : 24|16@1- (0.1,0) [0|0] "" Vector__XXX
 SG_ HVP_gpioPyroUnlock m0 : 25|1@1+ (1,0) [0|0] "" Vector__XXX
 SG_ HVP_hvp1v5Ref m0 : 26|12@1+ (0.1,0) [0|0] "" Vector__XXX
 SG_ HVP_hvilInVoltage m4 : 28|12@1+ (0.1,0) [0|0] "" Vector__XXX
 SG_ HVP_1kHzTask_maxExecTime m11 : 32|16@1+ (10,0) [0|0] "" Vector__XXX
 SG_ HVP_packPositiveV m2 : 32|16@1- (0.1,0) [0|0] "" Vector__XXX
 SG_ HVP_cpuLoad m8 : 34|7@1+ (1,0) [0|0] "" Vector__XXX
 SG_ HVP_battery12V m5 : 36|12@1+ (0.1,0) [0|0] "" Vector__XXX
 SG_ HVP_shuntAsicTempDbg m6 : 36|16@1- (0.01,0) [0|0] "" Vector__XXX
 SG_ HVP_packCurrentMia m0 : 38|1@1+ (1,0) [0|0] "" Vector__XXX
 SG_ HVP_auxCurrentMia m0 : 39|1@1+ (1,0) [0|0] "" Vector__XXX
 SG_ HVP_100HzTask_cpuUsage m10 : 40|7@1+ (1,0) [0|0] "" Vector__XXX
 SG_ HVP_10HzTask_cpuUsage m9 : 40|7@1+ (1,0) [0|0] "" Vector__XXX
 SG_ HVP_bmbSnaFrameCount m12 : 40|16@1+ (1,0) [0|0] "" Vector__XXX
 SG_ HVP_currentSenseMia m0 : 40|1@1+ (1,0) [0|0] "" Vector__XXX
 SG_ HVP_fcLinkNegativeV m3 : 40|16@1- (0.1,0) [0|0] "" Vector__XXX
 SG_ HVP_fcLinkVoltage m1 : 40|16@1- (0.1,0) [0|0] "" Vector__XXX
 SG_ HVP_hvilOutVoltage m4 : 40|12@1+ (0.1,0) [0|0] "" Vector__XXX
 SG_ HVP_shuntCurrentSampleDbg m7 : 40|16@1+ (1,0) [0|0] "" Vector__XXX
 SG_ HVP_1HzTask_cpuUsage m8 : 41|7@1+ (1,0) [0|0] "" Vector__XXX
 SG_ HVP_passivePyroRefVoltageIrrational m0 : 41|1@1+ (1,0) [0|0] "" Vector__XXX
 SG_ HVP_shuntThermistorMissing m0 : 42|1@1+ (1,0) [0|0] "" Vector__XXX
 SG_ HVP_shuntThermistorExpected m0 : 43|1@1+ (1,0) [0|0] "" Vector__XXX
 SG_ HVP_shuntThermistorMia m0 : 44|1@1+ (1,0) [0|0] "" Vector__XXX
 SG_ HVP_shuntUnexpectedThermistor m0 : 45|1@1+ (1,0) [0|0] "" Vector__XXX
 SG_ HVP_shuntHwMia m0 : 46|1@1+ (1,0) [0|0] "" Vector__XXX
 SG_ HVP_shuntCurrentIrrational m0 : 47|1@1+ (1,0) [0|0] "" Vector__XXX
 SG_ HVP_100HzTask_maxExecTime m10 : 48|16@1+ (10,0) [0|0] "" Vector__XXX
 SG_ HVP_1kHzTask_avgExecTime m11 : 48|16@1+ (10,0) [0|0] "" Vector__XXX
 SG_ HVP_bmbHighPrioTask_stackUsage m8 : 48|7@1+ (1,0) [0|0] "" Vector__XXX
 SG_ HVP_bmbTotalFrameCount m9 : 48|16@1+ (1,0) [0|0] "" Vector__XXX
 SG_ HVP_fcLinkPositiveV m5 : 48|16@1- (0.1,0) [0|0] "" Vector__XXX
 SG_ HVP_pyroAnalog m2 : 48|12@1+ (0.1,0) [0|0] "" Vector__XXX
 SG_ HVP_shuntAsicTCompActive m0 : 48|1@1+ (1,0) [0|0] "" Vector__XXX
 SG_ HVP_1kHzTask_stackUsage m0 : 49|7@1+ (1,0) [0|0] "" Vector__XXX
 SG_ HVP_shuntAuxCurrentStatus m6 : 52|2@1+ (1,0) [0|0] "" Vector__XXX
 SG_ HVP_shuntAsicTempStatus m6 : 54|2@1+ (1,0) [0|0] "" Vector__XXX
 SG_ HVP_bmbTask_stackUsage m8 : 55|7@1+ (1,0) [0|0] "" Vector__XXX
 SG_ HVP_100HzTask_stackUsage m0 : 56|7@1+ (1,0) [0|0] "" Vector__XXX
 SG_ HVP_10HzTask_stackUsage m1 : 56|7@1+ (1,0) [0|0] "" Vector__XXX
 SG_ HVP_1HzTask_stackUsage m3 : 56|7@1+ (1,0) [0|0] "" Vector__XXX
 SG_ HVP_shuntCurrentGainInvalidDbg m7 : 56|1@1+ (1,0) [0|0] "" Vector__XXX
 SG_ HVP_shuntGainInvalidCountDbg m4 : 56|8@1+ (1,0) [0|0] "" Vector__XXX
 SG_ HVP_shuntTask_stackUsage m12 : 56|7@1+ (1,0) [0|0] "" Vector__XXX
 SG_ HVP_udsTask_stackUsage m6 : 56|7@1+ (1,0) [0|0] "" Vector__XXX
 SG_ HVP_canTxRxTask_stackUsage m7 : 57|7@1+ (1,0) [0|0] "" Vector__XXX
 SG_ HVP_shuntSetTCRCoeffA m2 : 60|1@1+ (1,0) [0|0] "" Vector__XXX
 SG_ HVP_shuntSetTCRCoeffB m2 : 61|1@1+ (1,0) [0|0] "" Vector__XXX
 SG_ HVP_shuntSetTCRCoeffC m2 : 62|1@1+ (1,0) [0|0] "" Vector__XXX
 SG_ HVP_shuntSetTCRCoeffD m2 : 63|1@1+ (1,0) [0|0] "" Vector__XXX

BO_ 1970 DBG_bmsServiceReq: 8 Vector__XXX
 SG_ DBG_bmsDebugEnableAll : 0|1@1+ (1,0) [0|0] "" Vector__XXX

BO_ 1973 PM_itpmsDisplay: 8 Vector__XXX
 SG_ PM_itpmsDisplaySelector M : 0|2@1+ (1,0) [0|0] "" Vector__XXX
 SG_ PM_fusedPressureEstimateFrL m2 : 2|9@1+ (0.008,0) [0|0] "" Vector__XXX
 SG_ PM_fusedPressureEstimateReL m3 : 2|9@1+ (0.008,0) [0|0] "" Vector__XXX
 SG_ PM_indirectTPMSTellTale m0 : 2|2@1+ (1,0) [0|0] "" Vector__XXX
 SG_ PM_indirectTPMSDisplayState m0 : 4|2@1+ (1,0) [0|0] "" Vector__XXX
 SG_ PM_indirectTPMSDisplayProgress m0 : 8|5@1+ (0.05,0) [0|0] "" Vector__XXX
 SG_ PM_indirectTPMSRecommendedColdPressureFront m1 : 8|8@1+ (0.025,0) [0|0] "" Vector__XXX
 SG_ PM_fusedPressureEstimateFrR m2 : 11|9@1+ (0.008,0) [0|0] "" Vector__XXX
 SG_ PM_fusedPressureEstimateReR m3 : 11|9@1+ (0.008,0) [0|0] "" Vector__XXX
 SG_ PM_indirectTPMSDisplayWarningIndicatorFL m0 : 13|2@1+ (1,0) [0|0] "" Vector__XXX
 SG_ PM_indirectTPMSDisplayWarningIndicatorFR m0 : 16|2@1+ (1,0) [0|0] "" Vector__XXX
 SG_ PM_indirectTPMSRecommendedColdPressureRear m1 : 16|8@1+ (0.025,0) [0|0] "" Vector__XXX
 SG_ PM_indirectTPMSDisplayWarningIndicatorRL m0 : 18|2@1+ (1,0) [0|0] "" Vector__XXX
 SG_ PM_indirectTPMSDisplayWarningIndicatorRR m0 : 20|2@1+ (1,0) [0|0] "" Vector__XXX

BO_ 1976 EPBR_remoteADC: 8 Vector__XXX
 SG_ EPBR_remoteADCIndex M : 0|3@1+ (1,0) [0|0] "" Vector__XXX
 SG_ EPBR_BLEBPillarMonitor m4 : 3|10@1+ (0.017595307917888565,0) [0|0] "" Vector__XXX
 SG_ EPBR_efuseContinousMonitor m1 : 3|10@1+ (0.017595307917888565,0) [0|0] "" Vector__XXX
 SG_ EPBR_hvacRightVentDuctTemp m3 : 3|10@1+ (0.0009775171065493646,0) [0|0] "" Vector__XXX
 SG_ EPBR_mirrorDimMonitor m2 : 3|10@1+ (0.004887585532746823,0) [0|0] "" Vector__XXX
 SG_ EPBR_rearGlassHeaterCurrent m5 : 3|10@1+ (0.068359375,0) [0|0] "" Vector__XXX
 SG_ EPBR_windowLiftFrontDownMonitor m0 : 3|10@1+ (0.017595307917888565,0) [0|0] "" Vector__XXX
 SG_ EPBR_efuseNonContinuousMonitor m1 : 13|10@1+ (0.017595307917888565,0) [0|0] "" Vector__XXX
 SG_ EPBR_frontCushionTemp m5 : 13|10@1+ (0.0009775171065493646,0) [0|0] "" Vector__XXX
 SG_ EPBR_hvContactorsMonitor m4 : 13|10@1+ (0.017595307917888565,0) [0|0] "" Vector__XXX
 SG_ EPBR_hvacLeftVentDuctTemp m3 : 13|10@1+ (0.0009775171065493646,0) [0|0] "" Vector__XXX
 SG_ EPBR_seatFrontBackRestUpMonitor m2 : 13|10@1+ (0.017595307917888565,0) [0|0] "" Vector__XXX
 SG_ EPBR_windowLiftRearUpMonitor m0 : 13|10@1+ (0.017595307917888565,0) [0|0] "" Vector__XXX
 SG_ EPBR_2rSeatOutboardFloorSensor m5 : 24|10@1+ (0.004887585532746823,0) [0|0] "" Vector__XXX
 SG_ EPBR_ecallStandbyPowerMonitor m2 : 24|10@1+ (0.02932551319648094,0) [0|0] "" Vector__XXX
 SG_ EPBR_gloveBoxLatchUpstreamI m4 : 24|10@1+ (0.019550342130987292,0) [0|0] "" Vector__XXX
 SG_ EPBR_hvacRightLowerVentDuctTemp m3 : 24|10@1+ (0.0009775171065493646,0) [0|0] "" Vector__XXX
 SG_ EPBR_seatFrontLiftUpMonitor m0 : 24|10@1+ (0.017595307917888565,0) [0|0] "" Vector__XXX
 SG_ EPBR_seatFrontTrackForwardMonitor m1 : 24|10@1+ (0.017595307917888565,0) [0|0] "" Vector__XXX
 SG_ EPBR_2rSeatInboardFloorSensor m5 : 34|10@1+ (0.004887585532746823,0) [0|0] "" Vector__XXX
 SG_ EPBR_PCBATemp m2 : 34|10@1+ (0.0009775171065493646,0) [0|0] "" Vector__XXX
 SG_ EPBR_gloveBoxReleaseMonitor m1 : 34|10@1+ (0.017595307917888565,0) [0|0] "" Vector__XXX
 SG_ EPBR_hvacLeftLowerVentDuctTemp m3 : 34|10@1+ (0.0009775171065493646,0) [0|0] "" Vector__XXX
 SG_ EPBR_premiumAmpCurrent m4 : 34|10@1+ (0.029296875,0) [0|0] "" Vector__XXX
 SG_ EPBR_seatFrontTiltUpMonitor m0 : 34|10@1+ (0.017595307917888565,0) [0|0] "" Vector__XXX
 SG_ EPBR_remoteADCCounter : 52|4@1+ (1,0) [0|0] "" Vector__XXX
 SG_ EPBR_remoteADCChecksum : 56|8@1+ (1,0) [0|0] "" Vector__XXX

BO_ 1980 HCMR_info: 8 Vector__XXX
 SG_ VC_hcmrInfoIndex M : 0|4@1+ (1,0) [0|0] "" Vector__XXX
 SG_ VC_hcmrBoost_OV m7 : 4|1@1+ (1,0) [0|0] "" Vector__XXX
 SG_ VC_hcmrFault_DRL_THERMAL m4 : 4|1@1+ (1,0) [0|0] "" Vector__XXX
 SG_ VC_hcmrFault_HB_THERMAL m2 : 4|1@1+ (1,0) [0|0] "" Vector__XXX
 SG_ VC_hcmrFault_LB_THERMAL m3 : 4|1@1+ (1,0) [0|0] "" Vector__XXX
 SG_ VC_hcmrFault_SM_THERMAL m5 : 4|1@1+ (1,0) [0|0] "" Vector__XXX
 SG_ VC_hcmrVoltage_HB m6 : 4|10@1+ (0.1,0) [0|0] "" Vector__XXX
 SG_ VC_hcmrBoost_BOOTUV m7 : 5|1@1+ (1,0) [0|0] "" Vector__XXX
 SG_ VC_hcmrFault_DRL_VBCKUVLO m4 : 5|1@1+ (1,0) [0|0] "" Vector__XXX
 SG_ VC_hcmrFault_HB_VBCKUVLO m2 : 5|1@1+ (1,0) [0|0] "" Vector__XXX
 SG_ VC_hcmrFault_LB_VBCKUVLO m3 : 5|1@1+ (1,0) [0|0] "" Vector__XXX
 SG_ VC_hcmrFault_SM_VBCKUVLO m5 : 5|1@1+ (1,0) [0|0] "" Vector__XXX
 SG_ VC_hcmrBoost_ILIM m7 : 6|1@1+ (1,0) [0|0] "" Vector__XXX
 SG_ VC_hcmrFault_DRL_SHORT m4 : 6|1@1+ (1,0) [0|0] "" Vector__XXX
 SG_ VC_hcmrFault_HB_SHORT m2 : 6|1@1+ (1,0) [0|0] "" Vector__XXX
 SG_ VC_hcmrFault_LB_SHORT m3 : 6|1@1+ (1,0) [0|0] "" Vector__XXX
 SG_ VC_hcmrFault_SM_SHORT m5 : 6|1@1+ (1,0) [0|0] "" Vector__XXX
 SG_ VC_hcmrBoost_ISPUV m7 : 7|1@1+ (1,0) [0|0] "" Vector__XXX
 SG_ VC_hcmrFault_DRL_COMPOV m4 : 7|1@1+ (1,0) [0|0] "" Vector__XXX
 SG_ VC_hcmrFault_HB_COMPOV m2 : 7|1@1+ (1,0) [0|0] "" Vector__XXX
 SG_ VC_hcmrFault_LB_COMPOV m3 : 7|1@1+ (1,0) [0|0] "" Vector__XXX
 SG_ VC_hcmrFault_SM_COMPOV m5 : 7|1@1+ (1,0) [0|0] "" Vector__XXX
 SG_ VC_hcmrFault_DRL_HSILIM m4 : 8|1@1+ (1,0) [0|0] "" Vector__XXX
 SG_ VC_hcmrFault_HB_HSILIM m2 : 8|1@1+ (1,0) [0|0] "" Vector__XXX
 SG_ VC_hcmrFault_LB_HSILIM m3 : 8|1@1+ (1,0) [0|0] "" Vector__XXX
 SG_ VC_hcmrFault_SM_HSILIM m5 : 8|1@1+ (1,0) [0|0] "" Vector__XXX
 SG_ VC_hcmrLowBeamHighBeamDeratingFactor m8 : 8|8@1+ (0.5,0) [0|0] "" Vector__XXX
 SG_ VC_infoHCMRAssemblyId m1 : 8|16@1+ (1,0) [0|0] "" Vector__XXX
 SG_ VC_infoHCMRBuildConfigId m0 : 8|16@1+ (1,0) [0|0] "" Vector__XXX
 SG_ VC_hcmrFault_DRL_LSILIM m4 : 9|1@1+ (1,0) [0|0] "" Vector__XXX
 SG_ VC_hcmrFault_HB_LSILIM m2 : 9|1@1+ (1,0) [0|0] "" Vector__XXX
 SG_ VC_hcmrFault_LB_LSILIM m3 : 9|1@1+ (1,0) [0|0] "" Vector__XXX
 SG_ VC_hcmrFault_SM_LSILIM m5 : 9|1@1+ (1,0) [0|0] "" Vector__XXX
 SG_ VC_hcmrFault_DRL_BOOTUV m4 : 10|1@1+ (1,0) [0|0] "" Vector__XXX
 SG_ VC_hcmrFault_HB_BOOTUV m2 : 10|1@1+ (1,0) [0|0] "" Vector__XXX
 SG_ VC_hcmrFault_LB_BOOTUV m3 : 10|1@1+ (1,0) [0|0] "" Vector__XXX
 SG_ VC_hcmrFault_SM_BOOTUV m5 : 10|1@1+ (1,0) [0|0] "" Vector__XXX
 SG_ VC_hcmrFault_DRL_TOFFMIN m4 : 11|1@1+ (1,0) [0|0] "" Vector__XXX
 SG_ VC_hcmrFault_HB_TOFFMIN m2 : 11|1@1+ (1,0) [0|0] "" Vector__XXX
 SG_ VC_hcmrFault_LB_TOFFMIN m3 : 11|1@1+ (1,0) [0|0] "" Vector__XXX
 SG_ VC_hcmrFault_SM_TOFFMIN m5 : 11|1@1+ (1,0) [0|0] "" Vector__XXX
 SG_ VC_hcmrFault_DRL_LEDUV m4 : 12|1@1+ (1,0) [0|0] "" Vector__XXX
 SG_ VC_hcmrFault_HB_LEDUV m2 : 12|1@1+ (1,0) [0|0] "" Vector__XXX
 SG_ VC_hcmrFault_LB_LEDUV m3 : 12|1@1+ (1,0) [0|0] "" Vector__XXX
 SG_ VC_hcmrFault_SM_LEDUV m5 : 12|1@1+ (1,0) [0|0] "" Vector__XXX
 SG_ VC_hcmrFault_DRL_LEDOV m4 : 13|1@1+ (1,0) [0|0] "" Vector__XXX
 SG_ VC_hcmrFault_HB_LEDOV m2 : 13|1@1+ (1,0) [0|0] "" Vector__XXX
 SG_ VC_hcmrFault_LB_LEDOV m3 : 13|1@1+ (1,0) [0|0] "" Vector__XXX
 SG_ VC_hcmrFault_SM_LEDOV m5 : 13|1@1+ (1,0) [0|0] "" Vector__XXX
 SG_ VC_hcmrFault_TURN_THERMAL m4 : 14|1@1+ (1,0) [0|0] "" Vector__XXX
 SG_ VC_hcmrVoltage_LB m6 : 14|10@1+ (0.1,0) [0|0] "" Vector__XXX
 SG_ VC_hcmrFault_TURN_VBCKUVLO m4 : 15|1@1+ (1,0) [0|0] "" Vector__XXX
 SG_ VC_hcmrDRLSideMarkerTurnDeratingFactor m8 : 16|8@1+ (0.5,0) [0|0] "" Vector__XXX
 SG_ VC_hcmrFault_TURN_SHORT m4 : 16|1@1+ (1,0) [0|0] "" Vector__XXX
 SG_ VC_hcmr_ic400_EEPROMWriteCount m2 : 16|16@1+ (1,0) [0|0] "" Vector__XXX
 SG_ VC_hcmr_ic500_EEPROMWriteCount m3 : 16|16@1+ (1,0) [0|0] "" Vector__XXX
 SG_ VC_hcmr_ic700_EEPROMWriteCount m5 : 16|16@1+ (1,0) [0|0] "" Vector__XXX
 SG_ VC_hcmrFault_TURN_COMPOV m4 : 17|1@1+ (1,0) [0|0] "" Vector__XXX
 SG_ VC_hcmrFault_TURN_HSILIM m4 : 18|1@1+ (1,0) [0|0] "" Vector__XXX
 SG_ VC_hcmrFault_TURN_LSILIM m4 : 19|1@1+ (1,0) [0|0] "" Vector__XXX
 SG_ VC_hcmrFault_TURN_BOOTUV m4 : 20|1@1+ (1,0) [0|0] "" Vector__XXX
 SG_ VC_hcmrFault_TURN_TOFFMIN m4 : 21|1@1+ (1,0) [0|0] "" Vector__XXX
 SG_ VC_hcmrFault_TURN_LEDUV m4 : 22|1@1+ (1,0) [0|0] "" Vector__XXX
 SG_ VC_hcmrFault_TURN_LEDOV m4 : 23|1@1+ (1,0) [0|0] "" Vector__XXX
 SG_ VC_hcmrUartGroupsFullErrorCounter m8 : 24|8@1+ (1,0) [0|0] "" Vector__XXX
 SG_ VC_hcmrVoltage_DRL m6 : 24|10@1+ (0.1,0) [0|0] "" Vector__XXX
 SG_ VC_hcmr_ic600_EEPROMWriteCount m4 : 24|16@1+ (1,0) [0|0] "" Vector__XXX
 SG_ VC_infoHCMRPcbaId m1 : 24|16@1+ (1,0) [0|0] "" Vector__XXX
 SG_ VC_rightHeadlampLMMVariant m0 : 24|2@1+ (1,0) [0|0] "" Vector__XXX
 SG_ VC_hcmrUartValidatedGroupsFullErrorCounter m8 : 32|8@1+ (1,0) [0|0] "" Vector__XXX
 SG_ VC_hcmrVoltage_TURN m6 : 34|10@1+ (0.1,0) [0|0] "" Vector__XXX
 SG_ VC_hcmrUartDmaQueueFullErrorCounter m8 : 40|8@1+ (1,0) [0|0] "" Vector__XXX
 SG_ VC_infoHCMRUsageId m1 : 40|16@1+ (1,0) [0|0] "" Vector__XXX
 SG_ VC_hcmrVoltage_SM m6 : 44|10@1+ (0.1,0) [0|0] "" Vector__XXX
 SG_ VC_hcmrUartQueueResetCounter m8 : 48|8@1+ (1,0) [0|0] "" Vector__XXX
 SG_ VC_hcmrVoltage_boostRail m6 : 54|10@1+ (0.1,0) [0|0] "" Vector__XXX

BO_ 1981 V2G_vehLogData: 8 Vector__XXX
 SG_ V2G_vehLogDataSelect M : 0|5@1+ (1,0) [0|0] "" Vector__XXX
 SG_ V2G_cableCheckReq_sent m8 : 5|1@1+ (1,0) [0|0] "" Vector__XXX
 SG_ V2G_chargingStatusReq_sent m12 : 5|1@1+ (1,0) [0|0] "" Vector__XXX
 SG_ V2G_contractAuthReq_sent m6 : 5|1@1+ (1,0) [0|0] "" Vector__XXX
 SG_ V2G_currentDemReq_targetI m11 : 5|10@1+ (1.7578125,0) [0|0] "" Vector__XXX
 SG_ V2G_paymentDetailsReq_sent m5 : 5|1@1+ (1,0) [0|0] "" Vector__XXX
 SG_ V2G_powerDeliveryEndReq_sent m13 : 5|1@1+ (1,0) [0|0] "" Vector__XXX
 SG_ V2G_powerDeliveryStartReq_sent m10 : 5|1@1+ (1,0) [0|0] "" Vector__XXX
 SG_ V2G_serviceDetailReq_sent m3 : 5|1@1+ (1,0) [0|0] "" Vector__XXX
 SG_ V2G_serviceDiscoveryReq_sent m2 : 5|1@1+ (1,0) [0|0] "" Vector__XXX
 SG_ V2G_servicePaymentSelReq_sent m4 : 5|1@1+ (1,0) [0|0] "" Vector__XXX
 SG_ V2G_sessionSetupReq_sent m1 : 5|1@1+ (1,0) [0|0] "" Vector__XXX
 SG_ V2G_sessionStopReq_sent m14 : 5|1@1+ (1,0) [0|0] "" Vector__XXX
 SG_ V2G_suppAppProtocolReq_sent m0 : 5|1@1+ (1,0) [0|0] "" Vector__XXX
 SG_ V2G_powerDelEndReq_evStatusCode m13 : 6|1@1+ (1,0) [0|0] "" Vector__XXX
 SG_ V2G_chgParamReq_maxCurrentLim m7 : 8|13@1+ (0.2197265625,0) [0|0] "" Vector__XXX
 SG_ V2G_prechargeReq_targetV m9 : 8|13@1+ (0.146484375,0) [0|0] "" Vector__XXX
 SG_ V2G_currentDemReq_targetV m11 : 16|13@1+ (0.146484375,0) [0|0] "" Vector__XXX
 SG_ V2G_chgParamReq_maxVoltageLim m7 : 24|13@1+ (0.146484375,0) [0|0] "" Vector__XXX
 SG_ V2G_currentDemReq_maxCurrentLim m11 : 29|10@1+ (1.7578125,0) [0|0] "" Vector__XXX
 SG_ V2G_chgParamReq_maxPowerLim m7 : 40|13@1+ (0.1867675781,0) [0|0] "" Vector__XXX
 SG_ V2G_currentDemReq_maxVoltageLim m11 : 40|10@1+ (1.171875,0) [0|0] "" Vector__XXX
 SG_ V2G_currentDemReq_maxPowerLim m11 : 50|10@1+ (1.494138,0) [0|0] "" Vector__XXX

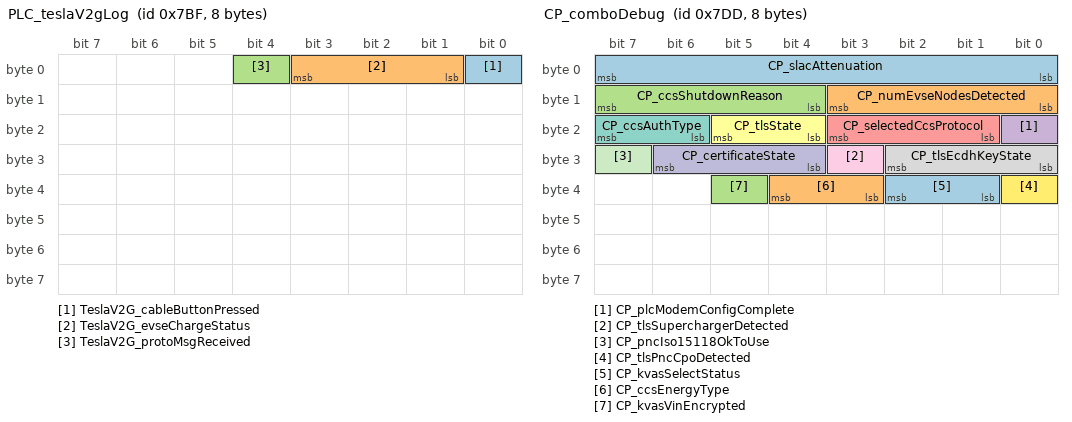
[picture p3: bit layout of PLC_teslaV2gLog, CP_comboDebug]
BO_ 1983 PLC_teslaV2gLog: 8 Vector__XXX
 SG_ TeslaV2G_cableButtonPressed : 0|1@1+ (1,0) [0|0] "" Vector__XXX
 SG_ TeslaV2G_evseChargeStatus : 1|3@1+ (1,0) [0|0] "" Vector__XXX
 SG_ TeslaV2G_protoMsgReceived : 4|1@1+ (1,0) [0|0] "" Vector__XXX

BO_ 1992 EPBL_info: 8 Vector__XXX
 SG_ EPBL_infoIndex M : 0|8@1+ (1,0) [0|0] "" Vector__XXX
 SG_ EPBL_infoAppCrc m13 : 8|32@1+ (1,0) [0|0] "" Vector__XXX
 SG_ EPBL_infoAppGitHash m17 : 8|56@1+ (1,0) [0|0] "" Vector__XXX
 SG_ EPBL_infoBootGitHash m18 : 8|56@1+ (1,0) [0|0] "" Vector__XXX
 SG_ EPBL_infoBootUdsProtoVersion m20 : 8|16@1+ (1,0) [0|0] "" Vector__XXX
 SG_ EPBL_infoBuildType m10 : 8|3@1+ (1,0) [0|0] "" Vector__XXX
 SG_ EPBL_infoPcbaId m11 : 8|8@1+ (1,0) [0|0] "" Vector__XXX
 SG_ EPBL_infoPlatformType m19 : 8|8@1+ (1,0) [0|0] "" Vector__XXX
 SG_ EPBL_infoAssemblyId m11 : 16|8@1+ (1,0) [0|0] "" Vector__XXX
 SG_ EPBL_infoBuildConfigId m10 : 16|16@1+ (1,0) [0|0] "" Vector__XXX
 SG_ EPBL_infoBootCrc m20 : 24|32@1+ (1,0) [0|0] "" Vector__XXX
 SG_ EPBL_infoUsageId m11 : 24|16@1+ (1,0) [0|0] "" Vector__XXX
 SG_ EPBL_infoHardwareId m10 : 32|16@1+ (1,0) [0|0] "" Vector__XXX
 SG_ EPBL_infoSubUsageId m11 : 40|16@1+ (1,0) [0|0] "" Vector__XXX
 SG_ EPBL_infoComponentId m10 : 48|16@1+ (1,0) [0|0] "" Vector__XXX

BO_ 1999 PM_debug: 8 Vector__XXX
 SG_ PM_debugSelector M : 0|8@1+ (1,0) [0|0] "" Vector__XXX
 SG_ PM_cpu100HzAvg m65 : 8|8@1+ (0.4,0) [0|0] "" Vector__XXX
 SG_ PM_cpu10kHzMin m66 : 8|8@1+ (0.4,0) [0|0] "" Vector__XXX
 SG_ PM_cpu1kHzMax m64 : 8|8@1+ (0.4,0) [0|0] "" Vector__XXX
 SG_ PM_gear m18 : 8|3@1+ (1,0) [0|0] "" Vector__XXX
 SG_ PM_idleStackSize m67 : 8|16@1+ (1,0) [0|0] "" Vector__XXX
 SG_ PM_pedalPos m5 : 8|8@1+ (0.4,0) [0|0] "" Vector__XXX
 SG_ PM_speedAverage m3 : 8|16@1- (0.1,0) [0|0] "" Vector__XXX
 SG_ PM_sysPedalMinTorque m16 : 8|15@1+ (0.5,-13000) [0|0] "" Vector__XXX
 SG_ PM_sysPostPedalMinTorque m17 : 8|15@1+ (0.5,-13000) [0|0] "" Vector__XXX
 SG_ PM_systemTorqueCommand m4 : 8|16@1- (0.5,0) [0|0] "" Vector__XXX
 SG_ PM_torqueDecelWindow m2 : 8|13@1- (2,0) [0|0] "" Vector__XXX
 SG_ PM_torqueSignError m1 : 8|13@1- (2,0) [0|0] "" Vector__XXX
 SG_ PM_udsStackSize m68 : 8|16@1+ (1,0) [0|0] "" Vector__XXX
 SG_ PM_xcpStackSize m69 : 8|16@1+ (1,0) [0|0] "" Vector__XXX
 SG_ PM_aebState m18 : 11|3@1+ (1,0) [0|0] "" Vector__XXX
 SG_ PM_cpu10HzMax m65 : 16|8@1+ (0.4,0) [0|0] "" Vector__XXX
 SG_ PM_cpu20kHzAvg m64 : 16|8@1+ (0.4,0) [0|0] "" Vector__XXX
 SG_ PM_pedalPosB m5 : 16|8@1+ (0.4,0) [0|0] "" Vector__XXX
 SG_ PM_vehicleHoldState m18 : 16|3@1+ (1,0) [0|0] "" Vector__XXX
 SG_ PM_sysPedalMaxTorque m16 : 23|15@1+ (0.5,0) [0|0] "" Vector__XXX
 SG_ PM_sysPostPedalMaxTorque m17 : 23|15@1+ (0.5,0) [0|0] "" Vector__XXX
 SG_ PM_cpu10HzAvg m65 : 24|8@1+ (0.4,0) [0|0] "" Vector__XXX
 SG_ PM_cpu1kHzMin m64 : 24|8@1+ (0.4,0) [0|0] "" Vector__XXX
 SG_ PM_idleStackMax m67 : 24|16@1+ (1,0) [0|0] "" Vector__XXX
 SG_ PM_pedalPosA m5 : 24|8@1+ (0.4,0) [0|0] "" Vector__XXX
 SG_ PM_shiftRequest m4 : 24|1@1+ (1,0) [0|0] "" Vector__XXX
 SG_ PM_speedMax m3 : 24|16@1- (0.1,0) [0|0] "" Vector__XXX
 SG_ PM_torqueAccelWindow m1 : 24|13@1- (2,0) [0|0] "" Vector__XXX
 SG_ PM_torqueDecelAvg m2 : 24|13@1- (2,0) [0|0] "" Vector__XXX
 SG_ PM_udsStackMax m68 : 24|16@1+ (1,0) [0|0] "" Vector__XXX
 SG_ PM_xcpStackMax m69 : 24|16@1+ (1,0) [0|0] "" Vector__XXX
 SG_ PM_allowedRegenBackfillBrakeTorque m4 : 32|16@1- (0.5,0) [0|0] "" Vector__XXX
 SG_ PM_cpu10HzMin m65 : 32|8@1+ (0.4,0) [0|0] "" Vector__XXX
 SG_ PM_cpu10kHzAvg m64 : 32|8@1+ (0.4,0) [0|0] "" Vector__XXX
 SG_ PM_pedalRailA m5 : 32|6@1+ (0.085,0) [0|0] "" Vector__XXX
 SG_ PM_cpu100HzMax m64 : 40|8@1+ (0.4,0) [0|0] "" Vector__XXX
 SG_ PM_cpu20kHzMax m65 : 40|8@1+ (0.4,0) [0|0] "" Vector__XXX
 SG_ PM_pedalRailB m5 : 40|6@1+ (0.085,0) [0|0] "" Vector__XXX
 SG_ PM_speedMin m3 : 40|16@1- (0.1,0) [0|0] "" Vector__XXX
 SG_ PM_torqueAccelAvg m1 : 40|13@1- (2,0) [0|0] "" Vector__XXX
 SG_ PM_torqueReversalWindow m2 : 40|13@1- (2,0) [0|0] "" Vector__XXX
 SG_ PM_cpu1kHzAvg m64 : 48|8@1+ (0.4,0) [0|0] "" Vector__XXX
 SG_ PM_cpu20kHzMin m65 : 48|8@1+ (0.4,0) [0|0] "" Vector__XXX
 SG_ PM_regenBackfillState m4 : 48|2@1+ (1,0) [0|0] "" Vector__XXX
 SG_ PM_cpu100HzMin m64 : 56|8@1+ (0.4,0) [0|0] "" Vector__XXX
 SG_ PM_cpu10kHzMax m65 : 56|8@1+ (0.4,0) [0|0] "" Vector__XXX

BO_ 2002 BMS_debugInfo_1Hz: 8 Vector__XXX
 SG_ BMS_1HzDebug_Id M : 0|4@1+ (1,0) [0|0] "" Vector__XXX
 SG_ BMS_dbgEpochTimeCorrectionCount m3 : 4|8@1+ (1,0) [0|0] "" Vector__XXX
 SG_ BMS_dbgMinBrickTempForFullWallPower m12 : 4|11@1+ (0.1,-50) [0|0] "" Vector__XXX
 SG_ BMS_dbgStackUse_Idle m11 : 4|10@1+ (2,0) [0|0] "" Vector__XXX
 SG_ BMS_dbgStackUse_Nvram m4 : 4|10@1+ (1,0) [0|0] "" Vector__XXX
 SG_ BMS_energyChgAhRemaining m2 : 4|12@1+ (0.1,0) [0|0] "" Vector__XXX
 SG_ BMS_brickBleedDbg1 m0 : 8|1@1+ (1,0) [0|0] "" Vector__XXX
 SG_ BMS_brickBleedDbg57 m1 : 8|1@1+ (1,0) [0|0] "" Vector__XXX
 SG_ BMS_dbgBirthDateModule1 m6 : 8|32@1+ (1,0) [0|0] "" Vector__XXX
 SG_ BMS_dbgBirthDateModule2 m7 : 8|32@1+ (1,0) [0|0] "" Vector__XXX
 SG_ BMS_dbgBirthDateModule3 m8 : 8|32@1+ (1,0) [0|0] "" Vector__XXX
 SG_ BMS_dbgBirthDateModule4 m9 : 8|32@1+ (1,0) [0|0] "" Vector__XXX
 SG_ BMS_dbgPackBirthDate m5 : 8|32@1+ (1,0) [0|0] "" Vector__XXX
 SG_ BMS_brickBleedDbg2 m0 : 9|1@1+ (1,0) [0|0] "" Vector__XXX
 SG_ BMS_brickBleedDbg58 m1 : 9|1@1+ (1,0) [0|0] "" Vector__XXX
 SG_ BMS_brickBleedDbg3 m0 : 10|1@1+ (1,0) [0|0] "" Vector__XXX
 SG_ BMS_brickBleedDbg59 m1 : 10|1@1+ (1,0) [0|0] "" Vector__XXX
 SG_ BMS_brickBleedDbg4 m0 : 11|1@1+ (1,0) [0|0] "" Vector__XXX
 SG_ BMS_brickBleedDbg60 m1 : 11|1@1+ (1,0) [0|0] "" Vector__XXX
 SG_ BMS_brickBleedDbg5 m0 : 12|1@1+ (1,0) [0|0] "" Vector__XXX
 SG_ BMS_brickBleedDbg61 m1 : 12|1@1+ (1,0) [0|0] "" Vector__XXX
 SG_ BMS_energyLatchedMinSoc m3 : 12|10@1+ (0.1,0) [0|0] "" Vector__XXX
 SG_ BMS_brickBleedDbg6 m0 : 13|1@1+ (1,0) [0|0] "" Vector__XXX
 SG_ BMS_brickBleedDbg62 m1 : 13|1@1+ (1,0) [0|0] "" Vector__XXX
 SG_ BMS_brickBleedDbg63 m1 : 14|1@1+ (1,0) [0|0] "" Vector__XXX
 SG_ BMS_brickBleedDbg7 m0 : 14|1@1+ (1,0) [0|0] "" Vector__XXX
 SG_ BMS_dbgStackUse_1Hz m4 : 14|10@1+ (2,0) [0|0] "" Vector__XXX
 SG_ BMS_brickBleedDbg64 m1 : 15|1@1+ (1,0) [0|0] "" Vector__XXX
 SG_ BMS_brickBleedDbg8 m0 : 15|1@1+ (1,0) [0|0] "" Vector__XXX
 SG_ BMS_brickBleedDbg65 m1 : 16|1@1+ (1,0) [0|0] "" Vector__XXX
 SG_ BMS_brickBleedDbg9 m0 : 16|1@1+ (1,0) [0|0] "" Vector__XXX
 SG_ BMS_dbgStoredEpochTime m12 : 16|32@1+ (1,0) [0|0] "" Vector__XXX
 SG_ BMS_energyDchAhRemaining m2 : 16|12@1+ (0.1,0) [0|0] "" Vector__XXX
 SG_ BMS_brickBleedDbg10 m0 : 17|1@1+ (1,0) [0|0] "" Vector__XXX
 SG_ BMS_brickBleedDbg66 m1 : 17|1@1+ (1,0) [0|0] "" Vector__XXX
 SG_ BMS_brickBleedDbg11 m0 : 18|1@1+ (1,0) [0|0] "" Vector__XXX
 SG_ BMS_brickBleedDbg67 m1 : 18|1@1+ (1,0) [0|0] "" Vector__XXX
 SG_ BMS_brickBleedDbg12 m0 : 19|1@1+ (1,0) [0|0] "" Vector__XXX
 SG_ BMS_brickBleedDbg68 m1 : 19|1@1+ (1,0) [0|0] "" Vector__XXX
 SG_ BMS_brickBleedDbg13 m0 : 20|1@1+ (1,0) [0|0] "" Vector__XXX
 SG_ BMS_brickBleedDbg69 m1 : 20|1@1+ (1,0) [0|0] "" Vector__XXX
 SG_ BMS_brickBleedDbg14 m0 : 21|1@1+ (1,0) [0|0] "" Vector__XXX
 SG_ BMS_brickBleedDbg70 m1 : 21|1@1+ (1,0) [0|0] "" Vector__XXX
 SG_ BMS_brickBleedDbg15 m0 : 22|1@1+ (1,0) [0|0] "" Vector__XXX
 SG_ BMS_brickBleedDbg71 m1 : 22|1@1+ (1,0) [0|0] "" Vector__XXX
 SG_ BMS_energyLatchedAveSoc m3 : 22|10@1+ (0.1,0) [0|0] "" Vector__XXX
 SG_ BMS_brickBleedDbg16 m0 : 23|1@1+ (1,0) [0|0] "" Vector__XXX
 SG_ BMS_brickBleedDbg72 m1 : 23|1@1+ (1,0) [0|0] "" Vector__XXX
 SG_ BMS_brickBleedDbg17 m0 : 24|1@1+ (1,0) [0|0] "" Vector__XXX
 SG_ BMS_brickBleedDbg73 m1 : 24|1@1+ (1,0) [0|0] "" Vector__XXX
 SG_ BMS_dbgStackUse_10Hz m4 : 24|10@1+ (1,0) [0|0] "" Vector__XXX
 SG_ BMS_brickBleedDbg18 m0 : 25|1@1+ (1,0) [0|0] "" Vector__XXX
 SG_ BMS_brickBleedDbg74 m1 : 25|1@1+ (1,0) [0|0] "" Vector__XXX
 SG_ BMS_brickBleedDbg19 m0 : 26|1@1+ (1,0) [0|0] "" Vector__XXX
 SG_ BMS_brickBleedDbg75 m1 : 26|1@1+ (1,0) [0|0] "" Vector__XXX
 SG_ BMS_brickBleedDbg20 m0 : 27|1@1+ (1,0) [0|0] "" Vector__XXX
 SG_ BMS_brickBleedDbg76 m1 : 27|1@1+ (1,0) [0|0] "" Vector__XXX
 SG_ BMS_brickBleedDbg21 m0 : 28|1@1+ (1,0) [0|0] "" Vector__XXX
 SG_ BMS_brickBleedDbg77 m1 : 28|1@1+ (1,0) [0|0] "" Vector__XXX
 SG_ BMS_chgAhLimitingBrickIndex m2 : 28|7@1+ (1,0) [0|0] "" Vector__XXX
 SG_ BMS_brickBleedDbg22 m0 : 29|1@1+ (1,0) [0|0] "" Vector__XXX
 SG_ BMS_brickBleedDbg78 m1 : 29|1@1+ (1,0) [0|0] "" Vector__XXX
 SG_ BMS_brickBleedDbg23 m0 : 30|1@1+ (1,0) [0|0] "" Vector__XXX
 SG_ BMS_brickBleedDbg79 m1 : 30|1@1+ (1,0) [0|0] "" Vector__XXX
 SG_ BMS_brickBleedDbg24 m0 : 31|1@1+ (1,0) [0|0] "" Vector__XXX
 SG_ BMS_brickBleedDbg80 m1 : 31|1@1+ (1,0) [0|0] "" Vector__XXX
 SG_ BMS_brickBleedDbg25 m0 : 32|1@1+ (1,0) [0|0] "" Vector__XXX
 SG_ BMS_brickBleedDbg81 m1 : 32|1@1+ (1,0) [0|0] "" Vector__XXX
 SG_ BMS_energyLatchedMinCac m3 : 32|12@1+ (0.1,0) [0|0] "" Vector__XXX
 SG_ BMS_brickBleedDbg26 m0 : 33|1@1+ (1,0) [0|0] "" Vector__XXX
 SG_ BMS_brickBleedDbg82 m1 : 33|1@1+ (1,0) [0|0] "" Vector__XXX
 SG_ BMS_brickBleedDbg27 m0 : 34|1@1+ (1,0) [0|0] "" Vector__XXX
 SG_ BMS_brickBleedDbg83 m1 : 34|1@1+ (1,0) [0|0] "" Vector__XXX
 SG_ BMS_dbgStackUse_100Hz m4 : 34|10@1+ (1,0) [0|0] "" Vector__XXX
 SG_ BMS_brickBleedDbg28 m0 : 35|1@1+ (1,0) [0|0] "" Vector__XXX
 SG_ BMS_brickBleedDbg84 m1 : 35|1@1+ (1,0) [0|0] "" Vector__XXX
 SG_ BMS_dchAhLimitingBrickIndex m2 : 35|7@1+ (1,0) [0|0] "" Vector__XXX
 SG_ BMS_brickBleedDbg29 m0 : 36|1@1+ (1,0) [0|0] "" Vector__XXX
 SG_ BMS_brickBleedDbg85 m1 : 36|1@1+ (1,0) [0|0] "" Vector__XXX
 SG_ BMS_brickBleedDbg30 m0 : 37|1@1+ (1,0) [0|0] "" Vector__XXX
 SG_ BMS_brickBleedDbg86 m1 : 37|1@1+ (1,0) [0|0] "" Vector__XXX
 SG_ BMS_brickBleedDbg31 m0 : 38|1@1+ (1,0) [0|0] "" Vector__XXX
 SG_ BMS_brickBleedDbg87 m1 : 38|1@1+ (1,0) [0|0] "" Vector__XXX
 SG_ BMS_brickBleedDbg32 m0 : 39|1@1+ (1,0) [0|0] "" Vector__XXX
 SG_ BMS_brickBleedDbg88 m1 : 39|1@1+ (1,0) [0|0] "" Vector__XXX
 SG_ BMS_brickBleedDbg33 m0 : 40|1@1+ (1,0) [0|0] "" Vector__XXX
 SG_ BMS_brickBleedDbg89 m1 : 40|1@1+ (1,0) [0|0] "" Vector__XXX
 SG_ BMS_brickBleedDbg34 m0 : 41|1@1+ (1,0) [0|0] "" Vector__XXX
 SG_ BMS_brickBleedDbg90 m1 : 41|1@1+ (1,0) [0|0] "" Vector__XXX
 SG_ BMS_brickBleedDbg35 m0 : 42|1@1+ (1,0) [0|0] "" Vector__XXX
 SG_ BMS_brickBleedDbg91 m1 : 42|1@1+ (1,0) [0|0] "" Vector__XXX
 SG_ BMS_energyChgTargetPackSoc m2 : 42|10@1+ (0.1,0) [0|0] "" Vector__XXX
 SG_ BMS_brickBleedDbg36 m0 : 43|1@1+ (1,0) [0|0] "" Vector__XXX
 SG_ BMS_brickBleedDbg92 m1 : 43|1@1+ (1,0) [0|0] "" Vector__XXX
 SG_ BMS_brickBleedDbg37 m0 : 44|1@1+ (1,0) [0|0] "" Vector__XXX
 SG_ BMS_brickBleedDbg93 m1 : 44|1@1+ (1,0) [0|0] "" Vector__XXX
 SG_ BMS_dbgStackUse_1KHz m4 : 44|10@1+ (1,0) [0|0] "" Vector__XXX
 SG_ BMS_energyLatchedAveCac m3 : 44|12@1+ (0.1,0) [0|0] "" Vector__XXX
 SG_ BMS_brickBleedDbg38 m0 : 45|1@1+ (1,0) [0|0] "" Vector__XXX
 SG_ BMS_brickBleedDbg94 m1 : 45|1@1+ (1,0) [0|0] "" Vector__XXX
 SG_ BMS_brickBleedDbg39 m0 : 46|1@1+ (1,0) [0|0] "" Vector__XXX
 SG_ BMS_brickBleedDbg95 m1 : 46|1@1+ (1,0) [0|0] "" Vector__XXX
 SG_ BMS_brickBleedDbg40 m0 : 47|1@1+ (1,0) [0|0] "" Vector__XXX
 SG_ BMS_brickBleedDbg96 m1 : 47|1@1+ (1,0) [0|0] "" Vector__XXX
 SG_ BMS_brickBleedDbg41 m0 : 48|1@1+ (1,0) [0|0] "" Vector__XXX
 SG_ BMS_brickBleedDbg97 m1 : 48|1@1+ (1,0) [0|0] "" Vector__XXX
 SG_ BMS_brickBleedDbg42 m0 : 49|1@1+ (1,0) [0|0] "" Vector__XXX
 SG_ BMS_brickBleedDbg98 m1 : 49|1@1+ (1,0) [0|0] "" Vector__XXX
 SG_ BMS_brickBleedDbg43 m0 : 50|1@1+ (1,0) [0|0] "" Vector__XXX
 SG_ BMS_brickBleedDbg99 m1 : 50|1@1+ (1,0) [0|0] "" Vector__XXX
 SG_ BMS_brickBleedDbg100 m1 : 51|1@1+ (1,0) [0|0] "" Vector__XXX
 SG_ BMS_brickBleedDbg44 m0 : 51|1@1+ (1,0) [0|0] "" Vector__XXX
 SG_ BMS_brickBleedDbg101 m1 : 52|1@1+ (1,0) [0|0] "" Vector__XXX
 SG_ BMS_brickBleedDbg45 m0 : 52|1@1+ (1,0) [0|0] "" Vector__XXX
 SG_ BMS_energyStopTarget m2 : 52|10@1+ (0.1,0) [0|0] "" Vector__XXX
 SG_ BMS_brickBleedDbg102 m1 : 53|1@1+ (1,0) [0|0] "" Vector__XXX
 SG_ BMS_brickBleedDbg46 m0 : 53|1@1+ (1,0) [0|0] "" Vector__XXX
 SG_ BMS_brickBleedDbg103 m1 : 54|1@1+ (1,0) [0|0] "" Vector__XXX
 SG_ BMS_brickBleedDbg47 m0 : 54|1@1+ (1,0) [0|0] "" Vector__XXX
 SG_ BMS_dbgStackUse_UDS m4 : 54|10@1+ (1,0) [0|0] "" Vector__XXX
 SG_ BMS_brickBleedDbg104 m1 : 55|1@1+ (1,0) [0|0] "" Vector__XXX
 SG_ BMS_brickBleedDbg48 m0 : 55|1@1+ (1,0) [0|0] "" Vector__XXX
 SG_ BMS_brickBleedDbg105 m1 : 56|1@1+ (1,0) [0|0] "" Vector__XXX
 SG_ BMS_brickBleedDbg49 m0 : 56|1@1+ (1,0) [0|0] "" Vector__XXX
 SG_ BMS_energyInitialPackTemp m3 : 56|8@1- (1,40) [0|0] "" Vector__XXX
 SG_ BMS_brickBleedDbg106 m1 : 57|1@1+ (1,0) [0|0] "" Vector__XXX
 SG_ BMS_brickBleedDbg50 m0 : 57|1@1+ (1,0) [0|0] "" Vector__XXX
 SG_ BMS_brickBleedDbg107 m1 : 58|1@1+ (1,0) [0|0] "" Vector__XXX
 SG_ BMS_brickBleedDbg51 m0 : 58|1@1+ (1,0) [0|0] "" Vector__XXX
 SG_ BMS_brickBleedDbg108 m1 : 59|1@1+ (1,0) [0|0] "" Vector__XXX
 SG_ BMS_brickBleedDbg52 m0 : 59|1@1+ (1,0) [0|0] "" Vector__XXX
 SG_ BMS_brickBleedDbg109 m1 : 60|1@1+ (1,0) [0|0] "" Vector__XXX
 SG_ BMS_brickBleedDbg53 m0 : 60|1@1+ (1,0) [0|0] "" Vector__XXX
 SG_ BMS_brickBleedDbg110 m1 : 61|1@1+ (1,0) [0|0] "" Vector__XXX
 SG_ BMS_brickBleedDbg54 m0 : 61|1@1+ (1,0) [0|0] "" Vector__XXX
 SG_ BMS_brickBleedDbg111 m1 : 62|1@1+ (1,0) [0|0] "" Vector__XXX
 SG_ BMS_brickBleedDbg55 m0 : 62|1@1+ (1,0) [0|0] "" Vector__XXX
 SG_ BMS_dbgEnergyVariableChgRequested m2 : 62|1@1+ (1,0) [0|0] "" Vector__XXX
 SG_ BMS_brickBleedDbg112 m1 : 63|1@1+ (1,0) [0|0] "" Vector__XXX
 SG_ BMS_brickBleedDbg56 m0 : 63|1@1+ (1,0) [0|0] "" Vector__XXX

BO_ 2004 PMR_debug: 8 Vector__XXX
 SG_ PMR_debugSelector M : 0|8@1+ (1,0) [0|0] "" Vector__XXX
 SG_ PMR_Ia m3 : 8|16@1- (0.0939,0) [0|0] "" Vector__XXX
 SG_ PMR_cpu100HzAvg m65 : 8|8@1+ (0.4,0) [0|0] "" Vector__XXX
 SG_ PMR_cpu10kHzMin m66 : 8|8@1+ (0.4,0) [0|0] "" Vector__XXX
 SG_ PMR_cpu1kHzMax m64 : 8|8@1+ (0.4,0) [0|0] "" Vector__XXX
 SG_ PMR_idleStackSize m67 : 8|16@1+ (1,0) [0|0] "" Vector__XXX
 SG_ PMR_offsetIa m5 : 8|12@1- (0.1,0) [0|0] "" Vector__XXX
 SG_ PMR_resolverPhaseAngle m17 : 8|9@1+ (0.001537,0) [0|0] "" Vector__XXX
 SG_ PMR_resolverSpeedError m16 : 8|16@1- (0.75,0) [0|0] "" Vector__XXX
 SG_ PMR_slipFrequency m4 : 8|16@1- (0.005,0) [0|0] "" Vector__XXX
 SG_ PMR_sysStackSize m70 : 8|16@1+ (1,0) [0|0] "" Vector__XXX
 SG_ PMR_torqueDecelWindow m2 : 8|13@1- (2,0) [0|0] "" Vector__XXX
 SG_ PMR_torqueSignError m1 : 8|13@1- (2,0) [0|0] "" Vector__XXX
 SG_ PMR_udsStackSize m68 : 8|16@1+ (1,0) [0|0] "" Vector__XXX
 SG_ PMR_xcpStackSize m69 : 8|16@1+ (1,0) [0|0] "" Vector__XXX
 SG_ PMR_cpu10HzMax m65 : 16|8@1+ (0.4,0) [0|0] "" Vector__XXX
 SG_ PMR_cpu20kHzAvg m64 : 16|8@1+ (0.4,0) [0|0] "" Vector__XXX
 SG_ PMR_resolverCommonGain m17 : 17|7@1+ (0.063,0) [0|0] "" Vector__XXX
 SG_ PMR_offsetIb m5 : 20|12@1- (0.1,0) [0|0] "" Vector__XXX
 SG_ PMR_Ib m3 : 24|16@1- (0.0939,0) [0|0] "" Vector__XXX
 SG_ PMR_cpu10HzAvg m65 : 24|8@1+ (0.4,0) [0|0] "" Vector__XXX
 SG_ PMR_cpu1kHzMin m64 : 24|8@1+ (0.4,0) [0|0] "" Vector__XXX
 SG_ PMR_idleStackMax m67 : 24|16@1+ (1,0) [0|0] "" Vector__XXX
 SG_ PMR_resolverExcitationGain m17 : 24|7@1+ (0.063,0) [0|0] "" Vector__XXX
 SG_ PMR_sysStackMax m70 : 24|16@1+ (1,0) [0|0] "" Vector__XXX
 SG_ PMR_torqueAccelWindow m1 : 24|13@1- (2,0) [0|0] "" Vector__XXX
 SG_ PMR_torqueDecelAvg m2 : 24|13@1- (2,0) [0|0] "" Vector__XXX
 SG_ PMR_udsStackMax m68 : 24|16@1+ (1,0) [0|0] "" Vector__XXX
 SG_ PMR_xcpStackMax m69 : 24|16@1+ (1,0) [0|0] "" Vector__XXX
 SG_ PMR_cpu10HzMin m65 : 32|8@1+ (0.4,0) [0|0] "" Vector__XXX
 SG_ PMR_cpu10kHzAvg m64 : 32|8@1+ (0.4,0) [0|0] "" Vector__XXX
 SG_ PMR_resolverOffsetCos m17 : 32|6@1+ (0.053,0) [0|0] "" Vector__XXX
 SG_ PMR_cpu100HzMax m64 : 40|8@1+ (0.4,0) [0|0] "" Vector__XXX
 SG_ PMR_cpu20kHzMax m65 : 40|8@1+ (0.4,0) [0|0] "" Vector__XXX
 SG_ PMR_iDQmagnitude m3 : 40|16@1- (0.0939,0) [0|0] "" Vector__XXX
 SG_ PMR_motorRPM m4 : 40|16@1- (1,0) [0|0] "" Vector__XXX
 SG_ PMR_resolverOffsetSin m17 : 40|6@1+ (0.053,0) [0|0] "" Vector__XXX
 SG_ PMR_torqueAccelAvg m1 : 40|13@1- (2,0) [0|0] "" Vector__XXX
 SG_ PMR_torqueReversalWindow m2 : 40|13@1- (2,0) [0|0] "" Vector__XXX
 SG_ PMR_switchingActive m5 : 46|1@1+ (1,0) [0|0] "" Vector__XXX
 SG_ PMR_torqueOutOfMap m5 : 47|1@1+ (1,0) [0|0] "" Vector__XXX
 SG_ PMR_cpu1kHzAvg m64 : 48|8@1+ (0.4,0) [0|0] "" Vector__XXX
 SG_ PMR_cpu20kHzMin m65 : 48|8@1+ (0.4,0) [0|0] "" Vector__XXX
 SG_ PMR_resolverOffsetExt m17 : 48|6@1+ (0.053,0) [0|0] "" Vector__XXX
 SG_ PMR_resolverNoCarrier m17 : 54|1@1+ (1,0) [0|0] "" Vector__XXX
 SG_ PMR_resolverPhaseOutOfSpec m17 : 55|1@1+ (1,0) [0|0] "" Vector__XXX
 SG_ PMR_cpu100HzMin m64 : 56|8@1+ (0.4,0) [0|0] "" Vector__XXX
 SG_ PMR_cpu10kHzMax m65 : 56|8@1+ (0.4,0) [0|0] "" Vector__XXX
 SG_ PMR_lmSatCoeff m3 : 56|8@1+ (0.00391,0) [0|0] "" Vector__XXX
 SG_ PMR_resolverClaMIA m17 : 56|1@1+ (1,0) [0|0] "" Vector__XXX
 SG_ PMR_statorT m4 : 56|8@1+ (1,-40) [0|0] "" Vector__XXX
 SG_ PMR_resolverDiMIA m17 : 57|1@1+ (1,0) [0|0] "" Vector__XXX

BO_ 2005 DIR_debug: 8 Vector__XXX
 SG_ DIR_debugSelector M : 0|8@1+ (1,0) [0|0] "" Vector__XXX
 SG_ DIR_cpu10HzMin m66 : 8|8@1+ (0.4,0) [0|0] "" Vector__XXX
 SG_ DIR_cpu1HzMin m128 : 8|8@1+ (0.4,0) [0|0] "" Vector__XXX
 SG_ DIR_cpu1kHzMin m67 : 8|8@1+ (0.4,0) [0|0] "" Vector__XXX
 SG_ DIR_dcCapTemp m64 : 8|8@1+ (1,-40) [0|0] "" Vector__XXX
 SG_ DIR_gainScale m37 : 8|8@1+ (0.01,0) [0|0] "" Vector__XXX
 SG_ DIR_hwFaultCount m69 : 8|4@1+ (1,0) [0|0] "" Vector__XXX
 SG_ DIR_latchFeedback m50 : 8|1@1+ (1,0) [0|0] "" Vector__XXX
 SG_ DIR_lmScale m36 : 8|8@1+ (0.004,0) [0|0] "" Vector__XXX
 SG_ DIR_motorIA m32 : 8|16@1+ (0.1,0) [0|0] "" Vector__XXX
 SG_ DIR_offsetA m44 : 8|6@1- (0.763,0) [0|0] "" Vector__XXX
 SG_ DIR_oilPumpMotorSpeed m46 : 8|8@1+ (40,0) [0|0] "" Vector__XXX
 SG_ DIR_phaseOutBusbarTemp m70 : 8|8@1+ (1,-40) [0|0] "" Vector__XXX
 SG_ DIR_resolverOffsetCos m48 : 8|8@1+ (0.015,0) [0|0] "" Vector__XXX
 SG_ DIR_rotorOffsetEst m43 : 8|12@1- (0.01,0) [0|0] "" Vector__XXX
 SG_ DIR_rsScale m34 : 8|8@1+ (0.01,0) [0|0] "" Vector__XXX
 SG_ DIR_soptTimeToTrip m49 : 8|8@1+ (0.05,0) [0|0] "" Vector__XXX
 SG_ DIR_statorEndWindingTemp m72 : 8|8@1+ (1,-40) [0|0] "" Vector__XXX
 SG_ DIR_statorIDref m33 : 8|16@1- (0.1,0) [0|0] "" Vector__XXX
 SG_ DIR_systemStack m68 : 8|8@1+ (0.4,0) [0|0] "" Vector__XXX
 SG_ DIR_tqSatThermal m39 : 8|8@1+ (0.4,0) [0|0] "" Vector__XXX
 SG_ DIR_tqScaleDifferential m35 : 8|8@1+ (0.4,0) [0|0] "" Vector__XXX
 SG_ DIR_mechssLatchesActive m50 : 9|1@1+ (1,0) [0|0] "" Vector__XXX
 SG_ DIR_usmState m38 : 12|3@1+ (1,0) [0|0] "" Vector__XXX
 SG_ DIR_busbarTemp m64 : 16|8@1+ (1,-40) [0|0] "" Vector__XXX
 SG_ DIR_cpu10HzAvg m66 : 16|8@1+ (0.4,0) [0|0] "" Vector__XXX
 SG_ DIR_cpu1HzAvg m128 : 16|8@1+ (0.4,0) [0|0] "" Vector__XXX
 SG_ DIR_cpu1kHzAvg m67 : 16|8@1+ (0.4,0) [0|0] "" Vector__XXX
 SG_ DIR_cpuIDWord0 m131 : 16|16@1+ (1,0) [0|0] "" Vector__XXX
 SG_ DIR_cpuIDWord1 m132 : 16|16@1+ (1,0) [0|0] "" Vector__XXX
 SG_ DIR_idleStack m68 : 16|8@1+ (0.4,0) [0|0] "" Vector__XXX
 SG_ DIR_lvBoostedRail m50 : 16|8@1+ (0.08,0) [0|0] "" Vector__XXX
 SG_ DIR_offsetB m44 : 16|6@1- (0.763,0) [0|0] "" Vector__XXX
 SG_ DIR_oilPumpPhaseVoltage m46 : 16|8@1+ (0.3,0) [0|0] "" Vector__XXX
 SG_ DIR_peakIQref m38 : 16|16@1+ (0.1,0) [0|0] "" Vector__XXX
 SG_ DIR_phaseOutBusbarWeldTemp m70 : 16|8@1+ (1,-40) [0|0] "" Vector__XXX
 SG_ DIR_resolverCosRmsSquared m52 : 16|8@1+ (0.005,0) [0|0] "" Vector__XXX
 SG_ DIR_resolverOffsetSin m48 : 16|8@1+ (0.015,0) [0|0] "" Vector__XXX
 SG_ DIR_rotorFlux m47 : 16|16@1+ (0.0001,0) [0|0] "" Vector__XXX
 SG_ DIR_rotorMaxMagnetTemp m72 : 16|8@1+ (1,-40) [0|0] "" Vector__XXX
 SG_ DIR_soptTripDelay m49 : 16|8@1+ (0.05,0) [0|0] "" Vector__XXX
 SG_ DIR_statorFluxRef m35 : 16|16@1+ (0.0001,0) [0|0] "" Vector__XXX
 SG_ DIR_statorIQref m34 : 16|16@1- (0.1,0) [0|0] "" Vector__XXX
 SG_ DIR_statorVDFiltered m63 : 16|16@1- (4e-05,0) [0|0] "" Vector__XXX
 SG_ DIR_statorVQ m36 : 16|16@1- (4e-05,0) [0|0] "" Vector__XXX
 SG_ DIR_tcMaxRequest m40 : 16|8@1+ (5,0) [0|0] "" Vector__XXX
 SG_ DIR_rotorOffsetMean m43 : 20|12@1- (0.01,0) [0|0] "" Vector__XXX
 SG_ DIR_activeDischargeRail m50 : 24|8@1+ (0.3,0) [0|0] "" Vector__XXX
 SG_ DIR_cpu100HzMin m66 : 24|8@1+ (0.4,0) [0|0] "" Vector__XXX
 SG_ DIR_cpu20kHzMin m67 : 24|8@1+ (0.4,0) [0|0] "" Vector__XXX
 SG_ DIR_decodeHardwareStack m68 : 24|8@1+ (0.4,0) [0|0] "" Vector__XXX
 SG_ DIR_lightSenseV m72 : 24|6@1+ (0.1,0) [0|0] "" Vector__XXX
 SG_ DIR_llsScale m42 : 24|8@1+ (0.004,0) [0|0] "" Vector__XXX
 SG_ DIR_motorIB m32 : 24|16@1+ (0.1,0) [0|0] "" Vector__XXX
 SG_ DIR_oilPumpPressureEstimateMax m46 : 24|8@1+ (2,0) [0|0] "" Vector__XXX
 SG_ DIR_pcsTemp m64 : 24|8@1+ (1,-40) [0|0] "" Vector__XXX
 SG_ DIR_phaseOutLugTemp m70 : 24|8@1+ (1,-40) [0|0] "" Vector__XXX
 SG_ DIR_resolverPhaseOffset m48 : 24|8@1+ (0.4,0) [0|0] "" Vector__XXX
 SG_ DIR_resolverSinRmsSquared m52 : 24|8@1+ (0.005,0) [0|0] "" Vector__XXX
 SG_ DIR_soptTimeToOff m49 : 24|11@1+ (0.05,0) [0|0] "" Vector__XXX
 SG_ DIR_statorIDfdb m33 : 24|16@1- (0.1,0) [0|0] "" Vector__XXX
 SG_ DIR_tcMinRequest m40 : 24|8@1+ (5,0) [0|0] "" Vector__XXX
 SG_ DIR_pyroSenseV m72 : 30|8@1+ (0.02,0) [0|0] "" Vector__XXX
 SG_ DIR_cpu100HzAvg m66 : 32|8@1+ (0.4,0) [0|0] "" Vector__XXX
 SG_ DIR_cpu20kHzAvg m67 : 32|8@1+ (0.4,0) [0|0] "" Vector__XXX
 SG_ DIR_cpuIDWord2 m132 : 32|16@1+ (1,0) [0|0] "" Vector__XXX
 SG_ DIR_crc m131 : 32|32@1+ (1,0) [0|0] "" Vector__XXX
 SG_ DIR_dcCableHeat m47 : 32|16@1+ (0.001,0) [0|0] "" Vector__XXX
 SG_ DIR_dcLinkCapTemp m70 : 32|8@1+ (1,-40) [0|0] "" Vector__XXX
 SG_ DIR_driveUnitOdometer m69 : 32|32@1+ (10,0) [0|0] "" Vector__XXX
 SG_ DIR_eepromStack m68 : 32|8@1+ (0.4,0) [0|0] "" Vector__XXX
 SG_ DIR_llrScale m42 : 32|8@1+ (0.015,0) [0|0] "" Vector__XXX
 SG_ DIR_loadAngleMargin m37 : 32|16@1- (0.0003,0) [0|0] "" Vector__XXX
 SG_ DIR_motorIAavg m38 : 32|16@1- (0.1,0) [0|0] "" Vector__XXX
 SG_ DIR_oilPumpPressureExpectedMin m46 : 32|8@1+ (2,0) [0|0] "" Vector__XXX
 SG_ DIR_preregulatorRail m50 : 32|8@1+ (0.15,0) [0|0] "" Vector__XXX
 SG_ DIR_resolverCommonGain m48 : 32|8@1+ (0.025,0) [0|0] "" Vector__XXX
 SG_ DIR_resolverCosFiltered m52 : 32|8@1- (0.01,0) [0|0] "" Vector__XXX
 SG_ DIR_statorFluxFdb m35 : 32|16@1+ (0.0001,0) [0|0] "" Vector__XXX
 SG_ DIR_statorIQfdb m34 : 32|16@1- (0.1,0) [0|0] "" Vector__XXX
 SG_ DIR_statorTemp1 m64 : 32|8@1+ (1,-40) [0|0] "" Vector__XXX
 SG_ DIR_statorVD m36 : 32|16@1- (4e-05,0) [0|0] "" Vector__XXX
 SG_ DIR_statorVQFiltered m63 : 32|16@1- (4e-05,0) [0|0] "" Vector__XXX
 SG_ DIR_tqSatMotorVoltage m39 : 32|8@1+ (0.4,0) [0|0] "" Vector__XXX
 SG_ DIR_wasteCurrentLimit m41 : 32|16@1+ (0.1,0) [0|0] "" Vector__XXX
 SG_ DIR_controlStack m67 : 40|8@1+ (0.4,0) [0|0] "" Vector__XXX
 SG_ DIR_cpu10msMin m66 : 40|8@1+ (0.4,0) [0|0] "" Vector__XXX
 SG_ DIR_hvDcCableTemp m70 : 40|8@1+ (1,-40) [0|0] "" Vector__XXX
 SG_ DIR_loadAngle m42 : 40|16@1- (0.0003,0) [0|0] "" Vector__XXX
 SG_ DIR_motorIC m32 : 40|16@1+ (0.1,0) [0|0] "" Vector__XXX
 SG_ DIR_resolverReady m48 : 40|1@1+ (1,0) [0|0] "" Vector__XXX
 SG_ DIR_resolverSinFiltered m52 : 40|8@1- (0.01,0) [0|0] "" Vector__XXX
 SG_ DIR_soptMaxCurrentMagSqrd m49 : 40|16@1+ (100,0) [0|0] "" Vector__XXX
 SG_ DIR_statorTemp2 m64 : 40|8@1+ (1,-40) [0|0] "" Vector__XXX
 SG_ DIR_torquePerAmp m33 : 40|16@1+ (0.0001,0) [0|0] "" Vector__XXX
 SG_ DIR_tqSatMotorCurrent m39 : 40|8@1+ (0.4,0) [0|0] "" Vector__XXX
 SG_ DIR_udsStack m68 : 40|8@1+ (0.4,0) [0|0] "" Vector__XXX
 SG_ DIR_resolverNoCarrier m48 : 41|1@1+ (1,0) [0|0] "" Vector__XXX
 SG_ DIR_resolverNoPhaseLock m48 : 42|1@1+ (1,0) [0|0] "" Vector__XXX
 SG_ DIR_resolverClaMIA m48 : 43|1@1+ (1,0) [0|0] "" Vector__XXX
 SG_ DIR_statorSlotWindingTemp m72 : 46|8@1+ (1,-40) [0|0] "" Vector__XXX
 SG_ DIR_cpuIDWord3 m132 : 48|16@1+ (1,0) [0|0] "" Vector__XXX
 SG_ DIR_internalAngleFilt m37 : 48|16@1+ (0.0003,0) [0|0] "" Vector__XXX
 SG_ DIR_magnetTempEst m47 : 48|8@1+ (1,-40) [0|0] "" Vector__XXX
 SG_ DIR_module10HzStack m66 : 48|8@1+ (0.4,0) [0|0] "" Vector__XXX
 SG_ DIR_motorIBavg m38 : 48|16@1- (0.1,0) [0|0] "" Vector__XXX
 SG_ DIR_motorV m34 : 48|16@1+ (2e-05,0) [0|0] "" Vector__XXX
 SG_ DIR_negDcBusbarTemp m70 : 48|8@1+ (1,-40) [0|0] "" Vector__XXX
 SG_ DIR_peakFlux m36 : 48|16@1+ (0.0001,0) [0|0] "" Vector__XXX
 SG_ DIR_phaseImbalanceFactor m35 : 48|16@1+ (0.0001,0) [0|0] "" Vector__XXX
 SG_ DIR_pwmState m63 : 48|2@1+ (1,0) [0|0] "" Vector__XXX
 SG_ DIR_resolverErrorRmsSquared m52 : 48|8@1+ (0.005,0) [0|0] "" Vector__XXX
 SG_ DIR_tqScaleMaxMotorSpeed m40 : 48|8@1+ (0.4,0) [0|0] "" Vector__XXX
 SG_ DIR_xcpStack m68 : 48|8@1+ (0.4,0) [0|0] "" Vector__XXX
 SG_ DIR_intervalMaxHvBusV m72 : 54|10@1+ (1,0) [0|0] "" Vector__XXX
 SG_ DIR_immobilizerStack m68 : 56|8@1+ (0.4,0) [0|0] "" Vector__XXX
 SG_ DIR_posDcBusbarTemp m70 : 56|8@1+ (1,-40) [0|0] "" Vector__XXX

BO_ 2007 DI_debug: 8 Vector__XXX
 SG_ DI_debugSelector M : 0|8@1+ (1,0) [0|0] "" Vector__XXX
 SG_ DI_ONE_onePedalCommandFwd m35 : 8|16@1- (0.5,0) [0|0] "" Vector__XXX
 SG_ DI_cpu10HzMin m66 : 8|8@1+ (0.4,0) [0|0] "" Vector__XXX
 SG_ DI_cpu1kHzMin m67 : 8|8@1+ (0.4,0) [0|0] "" Vector__XXX
 SG_ DI_muSurfHigh m2 : 8|8@1+ (0.005,0) [0|0] "" Vector__XXX
 SG_ DI_pwrSatMaxDischargePower m32 : 8|8@1+ (0.4,0) [0|0] "" Vector__XXX
 SG_ DI_regenBackfillCmd m39 : 8|13@1+ (2,0) [0|0] "" Vector__XXX
 SG_ DI_sysHeatPowerOptimal m50 : 8|8@1+ (0.08,0) [0|0] "" Vector__XXX
 SG_ DI_sysPedalMinTorque m34 : 8|15@1+ (0.5,-13000) [0|0] "" Vector__XXX
 SG_ DI_sysPostPedalMinTorque m53 : 8|15@1+ (0.5,-13000) [0|0] "" Vector__XXX
 SG_ DI_systemStack m68 : 8|8@1+ (0.4,0) [0|0] "" Vector__XXX
 SG_ DI_veMassInvRaw m33 : 8|12@1+ (1e-07,0.0001) [0|0] "" Vector__XXX
 SG_ DI_ONE_feedbackTorquePed m36 : 16|16@1- (0.5,0) [0|0] "" Vector__XXX
 SG_ DI_ONE_targetSpeedFilt m37 : 16|13@1+ (0.08,-40) [0|0] "" Vector__XXX
 SG_ DI_PED_pedalTorqueFwd m38 : 16|16@1- (0.5,0) [0|0] "" Vector__XXX
 SG_ DI_aebFaultReason m45 : 16|4@1+ (1,0) [0|0] "" Vector__XXX
 SG_ DI_brakeCommandScale m2 : 16|9@1+ (0.02,0) [0|0] "" Vector__XXX
 SG_ DI_cpu10HzAvg m66 : 16|8@1+ (0.4,0) [0|0] "" Vector__XXX
 SG_ DI_cpu1kHzAvg m67 : 16|8@1+ (0.4,0) [0|0] "" Vector__XXX
 SG_ DI_idleStack m68 : 16|8@1+ (0.4,0) [0|0] "" Vector__XXX
 SG_ DI_pwrSatMaxRegenPower m32 : 16|8@1+ (0.4,0) [0|0] "" Vector__XXX
 SG_ DI_veResForce m33 : 20|12@1- (0.0005,0) [0|0] "" Vector__XXX
 SG_ DI_regenBackfillUnavailableReason m39 : 21|5@1+ (1,0) [0|0] "" Vector__XXX
 SG_ DI_ONE_zeroPedalTorqueFwd m35 : 24|16@1- (0.5,0) [0|0] "" Vector__XXX
 SG_ DI_aebUnavailableReason m45 : 24|4@1+ (1,0) [0|0] "" Vector__XXX
 SG_ DI_cpu100HzMin m66 : 24|8@1+ (0.4,0) [0|0] "" Vector__XXX
 SG_ DI_cpu20kHzMin m67 : 24|8@1+ (0.4,0) [0|0] "" Vector__XXX
 SG_ DI_decodeHardwareStack m68 : 24|8@1+ (0.4,0) [0|0] "" Vector__XXX
 SG_ DI_pwrSatMaxBusVoltage m32 : 24|8@1+ (0.4,0) [0|0] "" Vector__XXX
 SG_ DI_sysPedalMaxTorque m34 : 24|15@1+ (0.5,0) [0|0] "" Vector__XXX
 SG_ DI_sysPostPedalMaxTorque m53 : 24|15@1+ (0.5,0) [0|0] "" Vector__XXX
 SG_ DI_regenBackfillAbsSatState m39 : 26|2@1+ (1,0) [0|0] "" Vector__XXX
 SG_ DI_ONE_feedbackSpeedFilt m37 : 32|13@1+ (0.08,-40) [0|0] "" Vector__XXX
 SG_ DI_ONE_up m36 : 32|16@1- (0.5,0) [0|0] "" Vector__XXX
 SG_ DI_PED_noCruiseCommandPed m38 : 32|16@1- (0.5,0) [0|0] "" Vector__XXX
 SG_ DI_aebCancelReason m45 : 32|8@1+ (1,0) [0|0] "" Vector__XXX
 SG_ DI_cpu100HzAvg m66 : 32|8@1+ (0.4,0) [0|0] "" Vector__XXX
 SG_ DI_cpu20kHzAvg m67 : 32|8@1+ (0.4,0) [0|0] "" Vector__XXX
 SG_ DI_eepromStack m68 : 32|8@1+ (0.4,0) [0|0] "" Vector__XXX
 SG_ DI_pedalPosFilt m2 : 32|8@1+ (0.4,0) [0|0] "" Vector__XXX
 SG_ DI_pwrSatMinBusVoltage m32 : 32|8@1+ (0.4,0) [0|0] "" Vector__XXX
 SG_ DI_tqSatUiDriveTorque m33 : 32|8@1+ (0.4,0) [0|0] "" Vector__XXX
 SG_ DI_ONE_zeroSpeedTorqueFwd m35 : 40|16@1- (0.5,0) [0|0] "" Vector__XXX
 SG_ DI_controlStack m67 : 40|8@1+ (0.4,0) [0|0] "" Vector__XXX
 SG_ DI_cpu10msMin m66 : 40|8@1+ (0.4,0) [0|0] "" Vector__XXX
 SG_ DI_opdUnavailableReason m45 : 40|5@1+ (1,0) [0|0] "" Vector__XXX
 SG_ DI_pwrSatDischargeCurrent m32 : 40|8@1+ (0.4,0) [0|0] "" Vector__XXX
 SG_ DI_sysStateExitCondition m34 : 40|5@1+ (1,0) [0|0] "" Vector__XXX
 SG_ DI_systemTorqueCommand m53 : 40|16@1- (0.5,0) [0|0] "" Vector__XXX
 SG_ DI_tqSatUiRegenTorque m33 : 40|8@1+ (0.4,0) [0|0] "" Vector__XXX
 SG_ DI_udsStack m68 : 40|8@1+ (0.4,0) [0|0] "" Vector__XXX
 SG_ DI_brkStState m45 : 45|3@1+ (1,0) [0|0] "" Vector__XXX
 SG_ DI_ONE_ui m36 : 48|16@1- (0.5,0) [0|0] "" Vector__XXX
 SG_ DI_PED_zeroPedalTorque m38 : 48|16@1- (0.5,0) [0|0] "" Vector__XXX
 SG_ DI_module10HzStack m66 : 48|8@1+ (0.4,0) [0|0] "" Vector__XXX
 SG_ DI_pwrSatChargeCurrent m32 : 48|8@1+ (0.4,0) [0|0] "" Vector__XXX
 SG_ DI_tqScaleShift m33 : 48|8@1+ (0.4,0) [0|0] "" Vector__XXX
 SG_ DI_xcpStack m68 : 48|8@1+ (0.4,0) [0|0] "" Vector__XXX
 SG_ DI_aebBlendOutActive m45 : 50|1@1+ (1,0) [0|0] "" Vector__XXX
 SG_ DI_locCheckSpeedRef m75 : 54|8@1+ (1,0) [0|0] "" Vector__XXX
 SG_ DI_ONE_vehicleHoldRequested m35 : 56|1@1+ (1,0) [0|0] "" Vector__XXX
 SG_ DI_immobilizerStack m68 : 56|8@1+ (0.4,0) [0|0] "" Vector__XXX
 SG_ DI_ssmState m32 : 56|4@1+ (1,0) [0|0] "" Vector__XXX
 SG_ DI_ONE_slowBrakeBlendRequested m35 : 57|1@1+ (1,0) [0|0] "" Vector__XXX
 SG_ DI_ONE_quickBrakeBlendRequested m35 : 58|1@1+ (1,0) [0|0] "" Vector__XXX
 SG_ DI_ONE_isRollingBackward m35 : 59|1@1+ (1,0) [0|0] "" Vector__XXX
 SG_ DI_brakeSwitchNO m32 : 62|1@1+ (1,0) [0|0] "" Vector__XXX
 SG_ DI_brakeSwitchNC m32 : 63|1@1+ (1,0) [0|0] "" Vector__XXX
 SG_ DI_immobilizerCondition m65 : 63|1@1+ (1,0) [0|0] "" Vector__XXX

BO_ 2013 CP_comboDebug: 8 Vector__XXX
 SG_ CP_slacAttenuation : 0|8@1+ (1,0) [0|0] "" Vector__XXX
 SG_ CP_numEvseNodesDetected : 8|4@1+ (1,0) [0|0] "" Vector__XXX
 SG_ CP_ccsShutdownReason : 12|4@1+ (1,0) [0|0] "" Vector__XXX
 SG_ CP_plcModemConfigComplete : 16|1@1+ (1,0) [0|0] "" Vector__XXX
 SG_ CP_selectedCcsProtocol : 17|3@1+ (1,0) [0|0] "" Vector__XXX
 SG_ CP_tlsState : 20|2@1+ (1,0) [0|0] "" Vector__XXX
 SG_ CP_ccsAuthType : 22|2@1+ (1,0) [0|0] "" Vector__XXX
 SG_ CP_tlsEcdhKeyState : 24|3@1+ (1,0) [0|0] "" Vector__XXX
 SG_ CP_tlsSuperchargerDetected : 27|1@1+ (1,0) [0|0] "" Vector__XXX
 SG_ CP_certificateState : 28|3@1+ (1,0) [0|0] "" Vector__XXX
 SG_ CP_pncIso15118OkToUse : 31|1@1+ (1,0) [0|0] "" Vector__XXX
 SG_ CP_tlsPncCpoDetected : 32|1@1+ (1,0) [0|0] "" Vector__XXX
 SG_ CP_kvasSelectStatus : 33|2@1+ (1,0) [0|0] "" Vector__XXX
 SG_ CP_ccsEnergyType : 35|2@1+ (1,0) [0|0] "" Vector__XXX
 SG_ CP_kvasVinEncrypted : 37|1@1+ (1,0) [0|0] "" Vector__XXX

BO_ 2014 UDS_functionalRequest_CH: 8 Vector__XXX
 SG_ UDS_functionalRequestDataCH : 7|64@0+ (1,0) [0|0] "" Vector__XXX

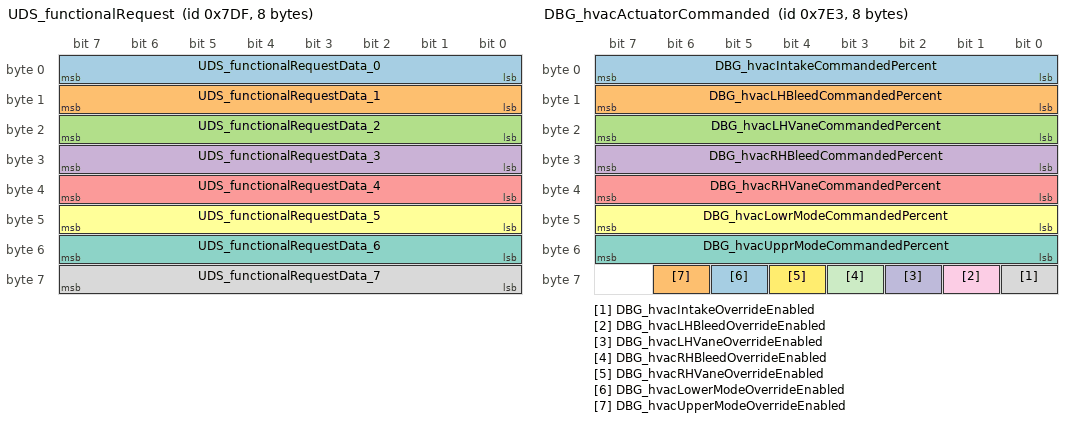
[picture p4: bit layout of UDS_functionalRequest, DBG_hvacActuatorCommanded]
BO_ 2015 UDS_functionalRequest: 8 Vector__XXX
 SG_ UDS_functionalRequestData_0 : 7|8@0+ (1,0) [0|0] "" Vector__XXX
 SG_ UDS_functionalRequestData_1 : 15|8@0+ (1,0) [0|0] "" Vector__XXX
 SG_ UDS_functionalRequestData_2 : 23|8@0+ (1,0) [0|0] "" Vector__XXX
 SG_ UDS_functionalRequestData_3 : 31|8@0+ (1,0) [0|0] "" Vector__XXX
 SG_ UDS_functionalRequestData_4 : 39|8@0+ (1,0) [0|0] "" Vector__XXX
 SG_ UDS_functionalRequestData_5 : 47|8@0+ (1,0) [0|0] "" Vector__XXX
 SG_ UDS_functionalRequestData_6 : 55|8@0+ (1,0) [0|0] "" Vector__XXX
 SG_ UDS_functionalRequestData_7 : 63|8@0+ (1,0) [0|0] "" Vector__XXX

BO_ 2019 DBG_hvacActuatorCommanded: 8 Vector__XXX
 SG_ DBG_hvacIntakeCommandedPercent : 0|8@1+ (0.4,0) [0|0] "" Vector__XXX
 SG_ DBG_hvacLHBleedCommandedPercent : 8|8@1+ (0.4,0) [0|0] "" Vector__XXX
 SG_ DBG_hvacLHVaneCommandedPercent : 16|8@1+ (0.4,0) [0|0] "" Vector__XXX
 SG_ DBG_hvacRHBleedCommandedPercent : 24|8@1+ (0.4,0) [0|0] "" Vector__XXX
 SG_ DBG_hvacRHVaneCommandedPercent : 32|8@1+ (0.4,0) [0|0] "" Vector__XXX
 SG_ DBG_hvacLowrModeCommandedPercent : 40|8@1+ (0.4,0) [0|0] "" Vector__XXX
 SG_ DBG_hvacUpprModeCommandedPercent : 48|8@1+ (0.4,0) [0|0] "" Vector__XXX
 SG_ DBG_hvacIntakeOverrideEnabled : 56|1@1+ (1,0) [0|0] "" Vector__XXX
 SG_ DBG_hvacLHBleedOverrideEnabled : 57|1@1+ (1,0) [0|0] "" Vector__XXX
 SG_ DBG_hvacLHVaneOverrideEnabled : 58|1@1+ (1,0) [0|0] "" Vector__XXX
 SG_ DBG_hvacRHBleedOverrideEnabled : 59|1@1+ (1,0) [0|0] "" Vector__XXX
 SG_ DBG_hvacRHVaneOverrideEnabled : 60|1@1+ (1,0) [0|0] "" Vector__XXX
 SG_ DBG_hvacLowerModeOverrideEnabled : 61|1@1+ (1,0) [0|0] "" Vector__XXX
 SG_ DBG_hvacUpperModeOverrideEnabled : 62|1@1+ (1,0) [0|0] "" Vector__XXX

BO_ 2021 DIR_dlogData: 8 Vector__XXX
 SG_ DIR_dlogData : 0|64@1+ (1,0) [0|0] "" Vector__XXX

BO_ 2024 EPBR_info: 8 Vector__XXX
 SG_ EPBR_infoIndex M : 0|8@1+ (1,0) [0|0] "" Vector__XXX
 SG_ EPBR_infoAppCrc m13 : 8|32@1+ (1,0) [0|0] "" Vector__XXX
 SG_ EPBR_infoAppGitHash m17 : 8|56@1+ (1,0) [0|0] "" Vector__XXX
 SG_ EPBR_infoBootGitHash m18 : 8|56@1+ (1,0) [0|0] "" Vector__XXX
 SG_ EPBR_infoBootUdsProtoVersion m20 : 8|16@1+ (1,0) [0|0] "" Vector__XXX
 SG_ EPBR_infoBuildType m10 : 8|3@1+ (1,0) [0|0] "" Vector__XXX
 SG_ EPBR_infoPcbaId m11 : 8|8@1+ (1,0) [0|0] "" Vector__XXX
 SG_ EPBR_infoPlatformType m19 : 8|8@1+ (1,0) [0|0] "" Vector__XXX
 SG_ EPBR_infoAssemblyId m11 : 16|8@1+ (1,0) [0|0] "" Vector__XXX
 SG_ EPBR_infoBuildConfigId m10 : 16|16@1+ (1,0) [0|0] "" Vector__XXX
 SG_ EPBR_infoBootCrc m20 : 24|32@1+ (1,0) [0|0] "" Vector__XXX
 SG_ EPBR_infoUsageId m11 : 24|16@1+ (1,0) [0|0] "" Vector__XXX
 SG_ EPBR_infoHardwareId m10 : 32|16@1+ (1,0) [0|0] "" Vector__XXX
 SG_ EPBR_infoSubUsageId m11 : 40|16@1+ (1,0) [0|0] "" Vector__XXX
 SG_ EPBR_infoComponentId m10 : 48|16@1+ (1,0) [0|0] "" Vector__XXX

BO_ 2031 DBG_testMessage: 8 Vector__XXX
 SG_ DBG_testID : 0|16@1+ (1,0) [0|0] "" Vector__XXX

BO_ 2033 GTW_hrl: 8 Vector__XXX
 SG_ GTW_hrlIndex M : 0|2@1+ (1,0) [0|0] "" Vector__XXX
 SG_ GTW_hrlState m2 : 2|1@1+ (1,0) [0|0] "" Vector__XXX
 SG_ GTW_hrlPagesCount m1 : 15|32@0+ (1,0) [0|0] "" Vector__XXX
 SG_ GTW_hrlTriggerDuration m2 : 15|16@0+ (1,0) [0|0] "" Vector__XXX
 SG_ GTW_hrlTriggerType m2 : 24|4@1+ (1,0) [0|0] "" Vector__XXX
 SG_ GTW_hrlTriggerId m2 : 39|16@0+ (1,0) [0|0] "" Vector__XXX
 SG_ GTW_hrlTriggerBus m2 : 55|3@0+ (1,0) [0|0] "" Vector__XXX

BO_ 2034 BMS_debugInfo_10Hz: 8 Vector__XXX
 SG_ BMS_10HzDebug_Id M : 0|6@1+ (1,0) [0|0] "" Vector__XXX
 SG_ BMS_allBricksRestingForCac m17 : 6|1@1+ (1,0) [0|0] "" Vector__XXX
 SG_ BMS_dbgPcsReportedOn m0 : 6|1@1+ (1,0) [0|0] "" Vector__XXX
 SG_ BMS_dbgSocByOcvMax m16 : 6|10@1+ (0.1,0) [0|0] "" Vector__XXX
 SG_ BMS_thmMdlDBG1 m12 : 6|10@1+ (0.1,-30) [0|0] "" Vector__XXX
 SG_ BMS_thmMdlDBG11 m14 : 6|10@1+ (0.1,-30) [0|0] "" Vector__XXX
 SG_ BMS_thmMdlDBG6 m13 : 6|10@1+ (0.1,-30) [0|0] "" Vector__XXX
 SG_ BMS_vshTestNeededTimer m20 : 6|18@1+ (1,0) [0|0] "" Vector__XXX
 SG_ BMS_dbgPcsIsActiveOnHvs m0 : 7|1@1+ (1,0) [0|0] "" Vector__XXX
 SG_ BMS_agedChargePolarization m33 : 8|12@1+ (0.002,0) [0|0] "" Vector__XXX
 SG_ BMS_ahCharge m1 : 8|24@1+ (0.1,0) [0|0] "" Vector__XXX
 SG_ BMS_avgCacError m19 : 8|9@1+ (0.2,0) [0|0] "" Vector__XXX
 SG_ BMS_brickRestingForCac m17 : 8|1@1+ (1,0) [0|0] "" Vector__XXX
 SG_ BMS_cacNetAhCounter m18 : 8|11@1- (1,0) [0|0] "" Vector__XXX
 SG_ BMS_dbg3v0ReferenceBms m21 : 8|16@1+ (0.001,0) [0|0] "" Vector__XXX
 SG_ BMS_dbgCpPositiveV m22 : 8|16@1- (0.02,0) [0|0] "" Vector__XXX
 SG_ BMS_dbgDcLinkPositiveV m23 : 8|16@1- (0.02,0) [0|0] "" Vector__XXX
 SG_ BMS_dbgFloodPortV1 m25 : 8|16@1+ (0.001,0) [0|0] "" Vector__XXX
 SG_ BMS_dbgMaxLoadedVoltageDischarge m26 : 8|16@1+ (0.0001,0) [0|0] "" Vector__XXX
 SG_ BMS_dbgPolarizationVoltageV1 m27 : 8|16@1- (0.0001,0) [0|0] "" Vector__XXX
 SG_ BMS_dbgResistanceR2 m28 : 8|16@1+ (0.001,0) [0|0] "" Vector__XXX
 SG_ BMS_dbgStandbySupplyOutV m30 : 8|16@1+ (0.001,0) [0|0] "" Vector__XXX
 SG_ BMS_dbgVerSenseV m24 : 8|16@1+ (0.001,0) [0|0] "" Vector__XXX
 SG_ BMS_driveBrickVoltageTarget m31 : 8|10@1+ (0.01,0) [0|0] "" Vector__XXX
 SG_ BMS_faultRetryCount m0 : 8|3@1+ (1,0) [0|0] "" Vector__XXX
 SG_ BMS_hviBusResourceState m29 : 8|3@1+ (1,0) [0|0] "" Vector__XXX
 SG_ BMS_isolationMode m2 : 8|3@1+ (1,0) [0|0] "" Vector__XXX
 SG_ BMS_maxSocByAhRaw m32 : 8|11@1+ (0.1,0) [0|0] "" Vector__XXX
 SG_ BMS_minBrickOcvMax m3 : 8|12@1+ (0.002,0) [0|0] "" Vector__XXX
 SG_ BMS_sumBrickVoltages m15 : 8|15@1+ (0.02,0) [0|0] "" Vector__XXX
 SG_ BMS_cacActivePoint m17 : 9|2@1+ (1,0) [0|0] "" Vector__XXX
 SG_ BMS_hvsBusResourceState m29 : 11|3@1+ (1,0) [0|0] "" Vector__XXX
 SG_ BMS_impedanceDevState m0 : 11|2@1+ (1,0) [0|0] "" Vector__XXX
 SG_ BMS_initialCacPointValid m17 : 11|1@1+ (1,0) [0|0] "" Vector__XXX
 SG_ BMS_negativeRIsoState m2 : 11|3@1+ (1,0) [0|0] "" Vector__XXX
 SG_ BMS_candidate1CacPointValid m17 : 12|1@1+ (1,0) [0|0] "" Vector__XXX
 SG_ BMS_candidate2CacPointValid m17 : 13|1@1+ (1,0) [0|0] "" Vector__XXX
 SG_ BMS_refPointDeltaSoc m17 : 14|10@1+ (0.1,0) [0|0] "" Vector__XXX
 SG_ BMS_dbgSocByOcvMin m16 : 16|10@1+ (0.1,0) [0|0] "" Vector__XXX
 SG_ BMS_positiveRIsoState m2 : 16|3@1+ (1,0) [0|0] "" Vector__XXX
 SG_ BMS_thmMdlDBG12 m14 : 16|10@1+ (0.1,-30) [0|0] "" Vector__XXX
 SG_ BMS_thmMdlDBG2 m12 : 16|10@1+ (0.1,-30) [0|0] "" Vector__XXX
 SG_ BMS_thmMdlDBG7 m13 : 16|10@1+ (0.1,-30) [0|0] "" Vector__XXX
 SG_ BMS_vehBusResourceState m29 : 16|3@1+ (1,0) [0|0] "" Vector__XXX
 SG_ BMS_cacNetAhError m18 : 19|8@1+ (0.1,0) [0|0] "" Vector__XXX
 SG_ BMS_cpResourceState m29 : 19|3@1+ (1,0) [0|0] "" Vector__XXX
 SG_ BMS_maxSocByAhRawBrickId m32 : 19|7@1+ (1,1) [0|0] "" Vector__XXX
 SG_ BMS_negIsolationSensorState m2 : 19|1@1+ (1,0) [0|0] "" Vector__XXX
 SG_ BMS_agedDischargePolarization m33 : 20|12@1+ (0.002,0) [0|0] "" Vector__XXX
 SG_ BMS_minBrickOcvMin m3 : 20|12@1+ (0.002,0) [0|0] "" Vector__XXX
 SG_ BMS_posIsolationSensorState m2 : 20|1@1+ (1,0) [0|0] "" Vector__XXX
 SG_ BMS_dbg3v0ReferenceHvp m21 : 24|16@1+ (0.001,0) [0|0] "" Vector__XXX
 SG_ BMS_dbgCapacitanceC1 m28 : 24|16@1+ (0.1,0) [0|0] "" Vector__XXX
 SG_ BMS_dbgCpNegativeV m22 : 24|16@1- (0.02,0) [0|0] "" Vector__XXX
 SG_ BMS_dbgDcLinkNegativeV m23 : 24|16@1- (0.02,0) [0|0] "" Vector__XXX
 SG_ BMS_dbgFloodPortV2 m25 : 24|16@1+ (0.001,0) [0|0] "" Vector__XXX
 SG_ BMS_dbgInternalHvilSenseV m24 : 24|16@1+ (0.001,0) [0|0] "" Vector__XXX
 SG_ BMS_dbgMinLoadedVoltageDischarge m26 : 24|16@1+ (0.0001,0) [0|0] "" Vector__XXX
 SG_ BMS_dbgPolarizationVoltageV2 m27 : 24|16@1- (0.0001,0) [0|0] "" Vector__XXX
 SG_ BMS_dbgStandbySupplyEnabled m30 : 24|1@1+ (1,0) [0|0] "" Vector__XXX
 SG_ BMS_hvpResourceState m29 : 24|3@1+ (1,0) [0|0] "" Vector__XXX
 SG_ BMS_packNegativeV m15 : 24|16@1- (0.02,0) [0|0] "" Vector__XXX
 SG_ BMS_refPointDeltaAh m17 : 24|11@1- (0.5,0) [0|0] "" Vector__XXX
 SG_ BMS_stdCacError m19 : 24|8@1+ (0.2,0) [0|0] "" Vector__XXX
 SG_ BMS_stopSecondsElapsed m20 : 24|16@1+ (1,0) [0|0] "" Vector__XXX
 SG_ BMS_dbgStandbySupplyGood m30 : 25|1@1+ (1,0) [0|0] "" Vector__XXX
 SG_ BMS_dbgSocByOcvEst m16 : 26|10@1+ (0.1,0) [0|0] "" Vector__XXX
 SG_ BMS_ocvMinBrick1 m32 : 26|12@1+ (0.002,0) [0|0] "" Vector__XXX
 SG_ BMS_thmMdlDBG13 m14 : 26|10@1+ (0.1,-30) [0|0] "" Vector__XXX
 SG_ BMS_thmMdlDBG3 m12 : 26|10@1+ (0.1,-30) [0|0] "" Vector__XXX
 SG_ BMS_thmMdlDBG8 m13 : 26|10@1+ (0.1,-30) [0|0] "" Vector__XXX
 SG_ BMS_cacEstimateBrick1 m18 : 27|10@1+ (0.5,75) [0|0] "" Vector__XXX
 SG_ BMS_pcsResourceState m29 : 27|3@1+ (1,0) [0|0] "" Vector__XXX
 SG_ BMS_ahDischarge m1 : 32|24@1+ (0.1,0) [0|0] "" Vector__XXX
 SG_ BMS_bmsResourceState m29 : 32|3@1+ (1,0) [0|0] "" Vector__XXX
 SG_ BMS_dbgBrick1OcvAccuracyBuffer m33 : 32|13@1+ (0.01,0) [0|0] "" Vector__XXX
 SG_ BMS_minBrickOcvIndex m3 : 32|7@1+ (1,0) [0|0] "" Vector__XXX
 SG_ BMS_refPointDeltaAhError m17 : 35|9@1- (0.05,0) [0|0] "" Vector__XXX
 SG_ BMS_verResourceState m29 : 35|3@1+ (1,0) [0|0] "" Vector__XXX
 SG_ BMS_thmMdlDBG4 m12 : 36|10@1+ (0.1,-30) [0|0] "" Vector__XXX
 SG_ BMS_thmMdlDBG9 m13 : 36|10@1+ (0.1,-30) [0|0] "" Vector__XXX
 SG_ BMS_cacInitialPtSocByOcv m18 : 37|10@1+ (0.1,0) [0|0] "" Vector__XXX
 SG_ BMS_ocvMaxBrick1 m32 : 38|12@1+ (0.002,0) [0|0] "" Vector__XXX
 SG_ BMS_isResting m3 : 39|1@1+ (1,0) [0|0] "" Vector__XXX
 SG_ BMS_dbg1v5ReferenceHvp m21 : 40|16@1+ (0.001,0) [0|0] "" Vector__XXX
 SG_ BMS_dbgCapacitanceC2 m28 : 40|16@1+ (0.1,0) [0|0] "" Vector__XXX
 SG_ BMS_dbgCpFaultInputV m22 : 40|16@1+ (0.001,0) [0|0] "" Vector__XXX
 SG_ BMS_dbgCpLatchEnableV m25 : 40|16@1+ (0.001,0) [0|0] "" Vector__XXX
 SG_ BMS_dbgDcLinkCtrSenseCurrent m23 : 40|16@1+ (0.01,0) [0|0] "" Vector__XXX
 SG_ BMS_dbgHvilCoverVSense m24 : 40|16@1+ (0.001,0) [0|0] "" Vector__XXX
 SG_ BMS_dbgMaxCurrentDischarge m26 : 40|14@1+ (0.15,0) [0|0] "" Vector__XXX
 SG_ BMS_dbgResistanceR1 m27 : 40|16@1+ (0.001,0) [0|0] "" Vector__XXX
 SG_ BMS_packPositiveV m15 : 40|16@1- (0.02,0) [0|0] "" Vector__XXX
 SG_ BMS_restTime1 m20 : 40|15@1+ (0.1,0) [0|0] "" Vector__XXX
 SG_ BMS_sleepState m29 : 40|3@1+ (1,0) [0|0] "" Vector__XXX
 SG_ BMS_socRestingCurrentThreshold m3 : 40|12@1+ (0.001,0) [0|0] "" Vector__XXX
 SG_ BMS_sleepRequest m29 : 43|3@1+ (1,0) [0|0] "" Vector__XXX
 SG_ BMS_refPointCacError1 m17 : 44|9@1+ (0.2,0) [0|0] "" Vector__XXX
 SG_ BMS_hviBusResourceRequest m29 : 46|2@1+ (1,0) [0|0] "" Vector__XXX
 SG_ BMS_thmMdlDBG10 m13 : 46|10@1+ (0.1,-30) [0|0] "" Vector__XXX
 SG_ BMS_thmMdlDBG5 m12 : 46|10@1+ (0.1,-30) [0|0] "" Vector__XXX
 SG_ BMS_cacUpdateCounter m18 : 47|3@1+ (1,0) [0|0] "" Vector__XXX
 SG_ BMS_hvsBusResourceRequest m29 : 48|2@1+ (1,0) [0|0] "" Vector__XXX
 SG_ BMS_cacUpdateStartPoint m18 : 50|2@1+ (1,0) [0|0] "" Vector__XXX
 SG_ BMS_ocvEstBrick1 m32 : 50|12@1+ (0.002,0) [0|0] "" Vector__XXX
 SG_ BMS_vehBusResourceRequest m29 : 50|2@1+ (1,0) [0|0] "" Vector__XXX
 SG_ BMS_cacUpdateEndPoint m18 : 52|2@1+ (1,0) [0|0] "" Vector__XXX
 SG_ BMS_cpResourceRequest m29 : 52|2@1+ (1,0) [0|0] "" Vector__XXX
 SG_ BMS_refPointCacError2 m17 : 53|9@1+ (0.2,0) [0|0] "" Vector__XXX
 SG_ BMS_cacUpdateError m18 : 54|9@1+ (0.2,0) [0|0] "" Vector__XXX
 SG_ BMS_hvpResourceRequest m29 : 54|2@1+ (1,0) [0|0] "" Vector__XXX
 SG_ BMS_bmsResourceRequest m29 : 56|2@1+ (1,0) [0|0] "" Vector__XXX
 SG_ BMS_dbgResistanceScaleChg m28 : 56|8@1+ (0.02,0) [0|0] "" Vector__XXX
 SG_ BMS_dbgResistanceScaleDch m27 : 56|8@1+ (0.02,0) [0|0] "" Vector__XXX
 SG_ BMS_verResourceRequest m29 : 58|2@1+ (1,0) [0|0] "" Vector__XXX

BO_ 2036 GTW_canLogAvailability: 8 Vector__XXX
 SG_ GTW_canLogServiceAvailability : 0|2@1+ (1,0) [0|0] "" Vector__XXX

BO_ 2040 ICR_logging: 8 Vector__XXX
 SG_ ICR_logging1HzIndex M : 0|4@1+ (1,0) [0|0] "" Vector__XXX
 SG_ ICR_buck0LoadCurrent m2 : 4|8@1+ (4,0) [0|0] "" Vector__XXX
 SG_ ICR_rxGainValRx0Mid m3 : 4|8@1+ (0.5,0) [0|0] "" Vector__XXX
 SG_ ICR_rxGainValRx3End m4 : 4|8@1+ (0.5,0) [0|0] "" Vector__XXX
 SG_ ICR_rxGainValRx3Start m1 : 4|8@1+ (0.5,0) [0|0] "" Vector__XXX
 SG_ ICR_tx0BallBreakReflCoeff m0 : 4|8@1- (0.2,0) [0|0] "" Vector__XXX
 SG_ ICR_buck1LoadCurrent m2 : 12|8@1+ (4,0) [0|0] "" Vector__XXX
 SG_ ICR_rxGainValRx1Mid m3 : 12|8@1+ (0.5,0) [0|0] "" Vector__XXX
 SG_ ICR_rxNoisePowerRX0 m1 : 12|6@1- (2,0) [0|0] "" Vector__XXX
 SG_ ICR_tx1BallBreakReflCoeff m0 : 12|8@1- (0.2,0) [0|0] "" Vector__XXX
 SG_ ICR_rxNoisePowerRX1 m1 : 18|6@1- (2,0) [0|0] "" Vector__XXX
 SG_ ICR_buck2LoadCurrent m2 : 20|8@1+ (4,0) [0|0] "" Vector__XXX
 SG_ ICR_rxGainValRx2Mid m3 : 20|8@1+ (0.5,0) [0|0] "" Vector__XXX
 SG_ ICR_tx2BallBreakReflCoeff m0 : 20|8@1- (0.2,0) [0|0] "" Vector__XXX
 SG_ ICR_rxNoisePowerRX2 m1 : 24|6@1- (2,0) [0|0] "" Vector__XXX
 SG_ ICR_buck3LoadCurrent m2 : 28|8@1+ (4,0) [0|0] "" Vector__XXX
 SG_ ICR_rxGainValRx0Start m0 : 28|8@1+ (0.5,0) [0|0] "" Vector__XXX
 SG_ ICR_rxGainValRx3Mid m3 : 28|8@1+ (0.5,0) [0|0] "" Vector__XXX
 SG_ ICR_rxNoisePowerRX3 m1 : 30|6@1- (2,0) [0|0] "" Vector__XXX
 SG_ ICR_maxProtoSizeBytes m1 : 36|16@1+ (1,0) [0|0] "" Vector__XXX
 SG_ ICR_rxGainValRx0End m3 : 36|8@1+ (0.5,0) [0|0] "" Vector__XXX
 SG_ ICR_rxGainValRx1Start m0 : 36|8@1+ (0.5,0) [0|0] "" Vector__XXX
 SG_ ICR_rxGainValRx1End m3 : 44|8@1+ (0.5,0) [0|0] "" Vector__XXX
 SG_ ICR_rxGainValRx2Start m0 : 44|8@1+ (0.5,0) [0|0] "" Vector__XXX
 SG_ ICR_rxGainValRx2End m3 : 52|8@1+ (0.5,0) [0|0] "" Vector__XXX
 SG_ ICR_internalTemperatureSensor m0 : 55|4@1+ (1,0) [0|0] "" Vector__XXX
 SG_ ICR_internalTemperature m0 : 59|5@1+ (1,0) [0|0] "" Vector__XXX

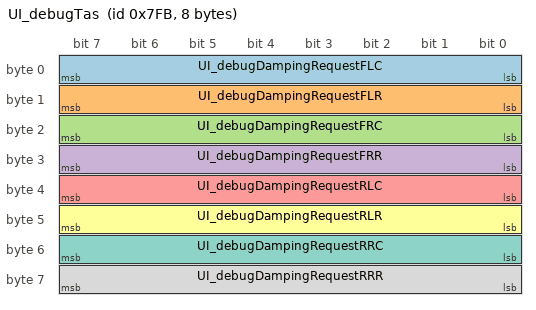
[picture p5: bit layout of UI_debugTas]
BO_ 2043 UI_debugTas: 8 Vector__XXX
 SG_ UI_debugDampingRequestFLC : 0|8@1+ (0.01,0) [0|0] "" Vector__XXX
 SG_ UI_debugDampingRequestFLR : 8|8@1+ (0.01,0) [0|0] "" Vector__XXX
 SG_ UI_debugDampingRequestFRC : 16|8@1+ (0.01,0) [0|0] "" Vector__XXX
 SG_ UI_debugDampingRequestFRR : 24|8@1+ (0.01,0) [0|0] "" Vector__XXX
 SG_ UI_debugDampingRequestRLC : 32|8@1+ (0.01,0) [0|0] "" Vector__XXX
 SG_ UI_debugDampingRequestRLR : 40|8@1+ (0.01,0) [0|0] "" Vector__XXX
 SG_ UI_debugDampingRequestRRC : 48|8@1+ (0.01,0) [0|0] "" Vector__XXX
 SG_ UI_debugDampingRequestRRR : 56|8@1+ (0.01,0) [0|0] "" Vector__XXX

BO_ 2046 PCS2_DRLog: 8 Vector__XXX
 SG_ PCS2_DRLogIndex M : 0|8@1+ (1,0) [0|0] "" Vector__XXX
 SG_ PCS2_DRLog_CPU0_DlogClientConnected m3 : 8|1@1+ (1,0) [0|0] "" Vector__XXX
 SG_ PCS2_DRLog_CPU0_Postamble m4 : 8|56@1+ (1,0) [0|0] "" Vector__XXX
 SG_ PCS2_DRLog_CPU0_Preamble m0 : 8|56@1+ (1,0) [0|0] "" Vector__XXX
 SG_ PCS2_DRLog_CPU0_SampleRate m2 : 8|8@1+ (1,0) [0|0] "" Vector__XXX
 SG_ PCS2_DRLog_CPU0_SampleRate_18V0_LLC_Freq m118 : 8|8@1+ (1,0) [0|0] "" Vector__XXX
 SG_ PCS2_DRLog_CPU0_SampleRate_18V0_Voltage m117 : 8|8@1+ (1,0) [0|0] "" Vector__XXX
 SG_ PCS2_DRLog_CPU0_SampleRate_18V0_boost_duty m160 : 8|8@1+ (1,0) [0|0] "" Vector__XXX
 SG_ PCS2_DRLog_CPU0_SampleRate_burst_mode m158 : 8|8@1+ (1,0) [0|0] "" Vector__XXX
 SG_ PCS2_DRLog_CPU0_SampleRate_channel8 m119 : 8|8@1+ (1,0) [0|0] "" Vector__XXX
 SG_ PCS2_DRLog_CPU0_SampleRate_dcdc_vHv m163 : 8|8@1+ (1,0) [0|0] "" Vector__XXX
 SG_ PCS2_DRLog_CPU0_SampleRate_dcdc_vHv_bot m116 : 8|8@1+ (1,0) [0|0] "" Vector__XXX
 SG_ PCS2_DRLog_CPU0_SampleRate_dcdc_vHv_top m102 : 8|8@1+ (1,0) [0|0] "" Vector__XXX
 SG_ PCS2_DRLog_CPU0_SampleRate_dcdc_vLv m103 : 8|8@1+ (1,0) [0|0] "" Vector__XXX
 SG_ PCS2_DRLog_CPU0_SampleRate_freq m112 : 8|8@1+ (1,0) [0|0] "" Vector__XXX
 SG_ PCS2_DRLog_CPU0_SampleRate_half_bus_comp m113 : 8|8@1+ (1,0) [0|0] "" Vector__XXX
 SG_ PCS2_DRLog_CPU0_SampleRate_half_period_pu m100 : 8|8@1+ (1,0) [0|0] "" Vector__XXX
 SG_ PCS2_DRLog_CPU0_SampleRate_i_HV_cl_sinking m115 : 8|8@1+ (1,0) [0|0] "" Vector__XXX
 SG_ PCS2_DRLog_CPU0_SampleRate_i_HV_cl_sourcing m114 : 8|8@1+ (1,0) [0|0] "" Vector__XXX
 SG_ PCS2_DRLog_CPU0_SampleRate_i_HV_cmd m101 : 8|8@1+ (1,0) [0|0] "" Vector__XXX
 SG_ PCS2_DRLog_CPU0_SampleRate_itank m104 : 8|8@1+ (1,0) [0|0] "" Vector__XXX
 SG_ PCS2_DRLog_CPU0_SampleRate_itank_margin_fb m109 : 8|8@1+ (1,0) [0|0] "" Vector__XXX
 SG_ PCS2_DRLog_CPU0_SampleRate_shrt_margin_fb m108 : 8|8@1+ (1,0) [0|0] "" Vector__XXX
 SG_ PCS2_DRLog_CPU0_SampleRate_shrt_margin_ref m107 : 8|8@1+ (1,0) [0|0] "" Vector__XXX
 SG_ PCS2_DRLog_CPU0_SampleRate_theta_HV m110 : 8|8@1+ (1,0) [0|0] "" Vector__XXX
 SG_ PCS2_DRLog_CPU0_SampleRate_theta_LV m111 : 8|8@1+ (1,0) [0|0] "" Vector__XXX
 SG_ PCS2_DRLog_CPU0_SampleRate_zcd_flt_cnt m105 : 8|8@1+ (1,0) [0|0] "" Vector__XXX
 SG_ PCS2_DRLog_CPU0_SampleRate_zcd_fltd m106 : 8|8@1+ (1,0) [0|0] "" Vector__XXX
 SG_ PCS2_DRLog_CPU0_SampleRate_zcd_rising_pu m165 : 8|8@1+ (1,0) [0|0] "" Vector__XXX
 SG_ PCS2_DRLog_CPU0_Version m1 : 8|8@1+ (1,0) [0|0] "" Vector__XXX
 SG_ PCS2_DRLog_CPU1_DlogClientConnected m13 : 8|1@1+ (1,0) [0|0] "" Vector__XXX
 SG_ PCS2_DRLog_CPU1_Postamble m14 : 8|56@1+ (1,0) [0|0] "" Vector__XXX
 SG_ PCS2_DRLog_CPU1_Preamble m10 : 8|56@1+ (1,0) [0|0] "" Vector__XXX
 SG_ PCS2_DRLog_CPU1_SampleRate m12 : 8|8@1+ (1,0) [0|0] "" Vector__XXX
 SG_ PCS2_DRLog_CPU1_SampleRate_18V0_LLC_Freq m138 : 8|8@1+ (1,0) [0|0] "" Vector__XXX
 SG_ PCS2_DRLog_CPU1_SampleRate_18V0_Voltage m137 : 8|8@1+ (1,0) [0|0] "" Vector__XXX
 SG_ PCS2_DRLog_CPU1_SampleRate_18V0_boost_duty m161 : 8|8@1+ (1,0) [0|0] "" Vector__XXX
 SG_ PCS2_DRLog_CPU1_SampleRate_burst_mode m159 : 8|8@1+ (1,0) [0|0] "" Vector__XXX
 SG_ PCS2_DRLog_CPU1_SampleRate_dcdc_iHv m139 : 8|8@1+ (1,0) [0|0] "" Vector__XXX
 SG_ PCS2_DRLog_CPU1_SampleRate_dcdc_vHv m164 : 8|8@1+ (1,0) [0|0] "" Vector__XXX
 SG_ PCS2_DRLog_CPU1_SampleRate_dcdc_vHv_bot m123 : 8|8@1+ (1,0) [0|0] "" Vector__XXX
 SG_ PCS2_DRLog_CPU1_SampleRate_dcdc_vHv_top m126 : 8|8@1+ (1,0) [0|0] "" Vector__XXX
 SG_ PCS2_DRLog_CPU1_SampleRate_dcdc_vLv m127 : 8|8@1+ (1,0) [0|0] "" Vector__XXX
 SG_ PCS2_DRLog_CPU1_SampleRate_freq m136 : 8|8@1+ (1,0) [0|0] "" Vector__XXX
 SG_ PCS2_DRLog_CPU1_SampleRate_half_bus_comp m120 : 8|8@1+ (1,0) [0|0] "" Vector__XXX
 SG_ PCS2_DRLog_CPU1_SampleRate_half_period_pu m124 : 8|8@1+ (1,0) [0|0] "" Vector__XXX
 SG_ PCS2_DRLog_CPU1_SampleRate_i_HV_cl_sinking m122 : 8|8@1+ (1,0) [0|0] "" Vector__XXX
 SG_ PCS2_DRLog_CPU1_SampleRate_i_HV_cl_sourcing m121 : 8|8@1+ (1,0) [0|0] "" Vector__XXX
 SG_ PCS2_DRLog_CPU1_SampleRate_i_HV_cmd m125 : 8|8@1+ (1,0) [0|0] "" Vector__XXX
 SG_ PCS2_DRLog_CPU1_SampleRate_itank m128 : 8|8@1+ (1,0) [0|0] "" Vector__XXX
 SG_ PCS2_DRLog_CPU1_SampleRate_itank_margin_fb m133 : 8|8@1+ (1,0) [0|0] "" Vector__XXX
 SG_ PCS2_DRLog_CPU1_SampleRate_shrt_margin_fb m132 : 8|8@1+ (1,0) [0|0] "" Vector__XXX
 SG_ PCS2_DRLog_CPU1_SampleRate_shrt_margin_ref m131 : 8|8@1+ (1,0) [0|0] "" Vector__XXX
 SG_ PCS2_DRLog_CPU1_SampleRate_theta_HV m134 : 8|8@1+ (1,0) [0|0] "" Vector__XXX
 SG_ PCS2_DRLog_CPU1_SampleRate_theta_LV m135 : 8|8@1+ (1,0) [0|0] "" Vector__XXX
 SG_ PCS2_DRLog_CPU1_SampleRate_zcd_flt_cnt m129 : 8|8@1+ (1,0) [0|0] "" Vector__XXX
 SG_ PCS2_DRLog_CPU1_SampleRate_zcd_fltd m130 : 8|8@1+ (1,0) [0|0] "" Vector__XXX
 SG_ PCS2_DRLog_CPU1_SampleRate_zcd_rising_pu m166 : 8|8@1+ (1,0) [0|0] "" Vector__XXX
 SG_ PCS2_DRLog_CPU1_Version m11 : 8|8@1+ (1,0) [0|0] "" Vector__XXX
 SG_ PCS2_DRLog_CPU2_DlogClientConnected m23 : 8|1@1+ (1,0) [0|0] "" Vector__XXX
 SG_ PCS2_DRLog_CPU2_Postamble m24 : 8|56@1+ (1,0) [0|0] "" Vector__XXX
 SG_ PCS2_DRLog_CPU2_Preamble m20 : 8|56@1+ (1,0) [0|0] "" Vector__XXX
 SG_ PCS2_DRLog_CPU2_SampleRate m22 : 8|8@1+ (1,0) [0|0] "" Vector__XXX
 SG_ PCS2_DRLog_CPU2_Version m21 : 8|8@1+ (1,0) [0|0] "" Vector__XXX
 SG_ PCS2_DRLog_CPU3_DlogClientConnected m33 : 8|1@1+ (1,0) [0|0] "" Vector__XXX
 SG_ PCS2_DRLog_CPU3_Postamble m34 : 8|56@1+ (1,0) [0|0] "" Vector__XXX
 SG_ PCS2_DRLog_CPU3_Preamble m30 : 8|56@1+ (1,0) [0|0] "" Vector__XXX
 SG_ PCS2_DRLog_CPU3_SampleRate m32 : 8|8@1+ (1,0) [0|0] "" Vector__XXX
 SG_ PCS2_DRLog_CPU3_SampleRate_18V0_LLC_Freq m157 : 8|8@1+ (1,0) [0|0] "" Vector__XXX
 SG_ PCS2_DRLog_CPU3_SampleRate_18V0_Voltage m156 : 8|8@1+ (1,0) [0|0] "" Vector__XXX
 SG_ PCS2_DRLog_CPU3_SampleRate_18V0_boost_duty m162 : 8|8@1+ (1,0) [0|0] "" Vector__XXX
 SG_ PCS2_DRLog_CPU3_SampleRate_Itank_margin m144 : 8|8@1+ (1,0) [0|0] "" Vector__XXX
 SG_ PCS2_DRLog_CPU3_SampleRate_freq m151 : 8|8@1+ (1,0) [0|0] "" Vector__XXX
 SG_ PCS2_DRLog_CPU3_SampleRate_hvdc_current m155 : 8|8@1+ (1,0) [0|0] "" Vector__XXX
 SG_ PCS2_DRLog_CPU3_SampleRate_i_ac_cmd_l1 m148 : 8|8@1+ (1,0) [0|0] "" Vector__XXX
 SG_ PCS2_DRLog_CPU3_SampleRate_i_ac_cmd_l2 m149 : 8|8@1+ (1,0) [0|0] "" Vector__XXX
 SG_ PCS2_DRLog_CPU3_SampleRate_i_ac_cmd_l3 m153 : 8|8@1+ (1,0) [0|0] "" Vector__XXX
 SG_ PCS2_DRLog_CPU3_SampleRate_i_ac_ref_l1 m147 : 8|8@1+ (1,0) [0|0] "" Vector__XXX
 SG_ PCS2_DRLog_CPU3_SampleRate_i_ln_l1 m142 : 8|8@1+ (1,0) [0|0] "" Vector__XXX
 SG_ PCS2_DRLog_CPU3_SampleRate_i_ln_l2 m143 : 8|8@1+ (1,0) [0|0] "" Vector__XXX
 SG_ PCS2_DRLog_CPU3_SampleRate_i_ln_l3 m154 : 8|8@1+ (1,0) [0|0] "" Vector__XXX
 SG_ PCS2_DRLog_CPU3_SampleRate_itank_peak m150 : 8|8@1+ (1,0) [0|0] "" Vector__XXX
 SG_ PCS2_DRLog_CPU3_SampleRate_pwm_enabled m145 : 8|8@1+ (1,0) [0|0] "" Vector__XXX
 SG_ PCS2_DRLog_CPU3_SampleRate_v_dc m152 : 8|8@1+ (1,0) [0|0] "" Vector__XXX
 SG_ PCS2_DRLog_CPU3_SampleRate_v_ln_l1 m140 : 8|8@1+ (1,0) [0|0] "" Vector__XXX
 SG_ PCS2_DRLog_CPU3_SampleRate_v_ln_l2 m141 : 8|8@1+ (1,0) [0|0] "" Vector__XXX
 SG_ PCS2_DRLog_CPU3_SampleRate_v_ln_l3 m146 : 8|8@1+ (1,0) [0|0] "" Vector__XXX
 SG_ PCS2_DRLog_CPU3_SampleRate_v_ln_pre_relay_l2 m167 : 8|8@1+ (1,0) [0|0] "" Vector__XXX
 SG_ PCS2_DRLog_CPU3_SampleRate_v_ln_pre_relay_l3 m168 : 8|8@1+ (1,0) [0|0] "" Vector__XXX
 SG_ PCS2_DRLog_CPU3_Version m31 : 8|8@1+ (1,0) [0|0] "" Vector__XXX
 SG_ PCS2_DRLog_CPU0_Triggered m3 : 9|1@1+ (1,0) [0|0] "" Vector__XXX
 SG_ PCS2_DRLog_CPU1_Triggered m13 : 9|1@1+ (1,0) [0|0] "" Vector__XXX
 SG_ PCS2_DRLog_CPU2_Triggered m23 : 9|1@1+ (1,0) [0|0] "" Vector__XXX
 SG_ PCS2_DRLog_CPU3_Triggered m33 : 9|1@1+ (1,0) [0|0] "" Vector__XXX
 SG_ PCS2_DRLog_CPU0_ServiceState m3 : 10|4@1+ (1,0) [0|0] "" Vector__XXX
 SG_ PCS2_DRLog_CPU1_ServiceState m13 : 10|4@1+ (1,0) [0|0] "" Vector__XXX
 SG_ PCS2_DRLog_CPU2_ServiceState m23 : 10|4@1+ (1,0) [0|0] "" Vector__XXX
 SG_ PCS2_DRLog_CPU3_ServiceState m33 : 10|4@1+ (1,0) [0|0] "" Vector__XXX
 SG_ PCS2_DRLog_CPU0_Index m2 : 16|16@1+ (1,0) [0|0] "" Vector__XXX
 SG_ PCS2_DRLog_CPU0_Index_18V0_LLC_Freq m118 : 16|16@1+ (1,0) [0|0] "" Vector__XXX
 SG_ PCS2_DRLog_CPU0_Index_18V0_Voltage m117 : 16|16@1+ (1,0) [0|0] "" Vector__XXX
 SG_ PCS2_DRLog_CPU0_Index_18V0_boost_duty m160 : 16|16@1+ (1,0) [0|0] "" Vector__XXX
 SG_ PCS2_DRLog_CPU0_Index_burst_mode m158 : 16|16@1+ (1,0) [0|0] "" Vector__XXX
 SG_ PCS2_DRLog_CPU0_Index_channel8 m119 : 16|16@1+ (1,0) [0|0] "" Vector__XXX
 SG_ PCS2_DRLog_CPU0_Index_dcdc_vHv m163 : 16|16@1+ (1,0) [0|0] "" Vector__XXX
 SG_ PCS2_DRLog_CPU0_Index_dcdc_vHv_bot m116 : 16|16@1+ (1,0) [0|0] "" Vector__XXX
 SG_ PCS2_DRLog_CPU0_Index_dcdc_vHv_top m102 : 16|16@1+ (1,0) [0|0] "" Vector__XXX
 SG_ PCS2_DRLog_CPU0_Index_dcdc_vLv m103 : 16|16@1+ (1,0) [0|0] "" Vector__XXX
 SG_ PCS2_DRLog_CPU0_Index_freq m112 : 16|16@1+ (1,0) [0|0] "" Vector__XXX
 SG_ PCS2_DRLog_CPU0_Index_half_bus_comp m113 : 16|16@1+ (1,0) [0|0] "" Vector__XXX
 SG_ PCS2_DRLog_CPU0_Index_half_period_pu m100 : 16|16@1+ (1,0) [0|0] "" Vector__XXX
 SG_ PCS2_DRLog_CPU0_Index_i_HV_cl_sinking m115 : 16|16@1+ (1,0) [0|0] "" Vector__XXX
 SG_ PCS2_DRLog_CPU0_Index_i_HV_cl_sourcing m114 : 16|16@1+ (1,0) [0|0] "" Vector__XXX
 SG_ PCS2_DRLog_CPU0_Index_i_HV_cmd m101 : 16|16@1+ (1,0) [0|0] "" Vector__XXX
 SG_ PCS2_DRLog_CPU0_Index_itank m104 : 16|16@1+ (1,0) [0|0] "" Vector__XXX
 SG_ PCS2_DRLog_CPU0_Index_itank_margin_fb m109 : 16|16@1+ (1,0) [0|0] "" Vector__XXX
 SG_ PCS2_DRLog_CPU0_Index_shrt_margin_fb m108 : 16|16@1+ (1,0) [0|0] "" Vector__XXX
 SG_ PCS2_DRLog_CPU0_Index_shrt_margin_ref m107 : 16|16@1+ (1,0) [0|0] "" Vector__XXX
 SG_ PCS2_DRLog_CPU0_Index_theta_HV m110 : 16|16@1+ (1,0) [0|0] "" Vector__XXX
 SG_ PCS2_DRLog_CPU0_Index_theta_LV m111 : 16|16@1+ (1,0) [0|0] "" Vector__XXX
 SG_ PCS2_DRLog_CPU0_Index_zcd_flt_cnt m105 : 16|16@1+ (1,0) [0|0] "" Vector__XXX
 SG_ PCS2_DRLog_CPU0_Index_zcd_fltd m106 : 16|16@1+ (1,0) [0|0] "" Vector__XXX
 SG_ PCS2_DRLog_CPU0_Index_zcd_rising_pu m165 : 16|16@1+ (1,0) [0|0] "" Vector__XXX
 SG_ PCS2_DRLog_CPU0_InstanceIndex m3 : 16|4@1+ (1,0) [0|0] "" Vector__XXX
 SG_ PCS2_DRLog_CPU0_SampleFrequency m1 : 16|32@1+ (1,0) [0|0] "" Vector__XXX
 SG_ PCS2_DRLog_CPU1_Index m12 : 16|16@1+ (1,0) [0|0] "" Vector__XXX
 SG_ PCS2_DRLog_CPU1_Index_18V0_LLC_Freq m138 : 16|16@1+ (1,0) [0|0] "" Vector__XXX
 SG_ PCS2_DRLog_CPU1_Index_18V0_Voltage m137 : 16|16@1+ (1,0) [0|0] "" Vector__XXX
 SG_ PCS2_DRLog_CPU1_Index_18V0_boost_duty m161 : 16|16@1+ (1,0) [0|0] "" Vector__XXX
 SG_ PCS2_DRLog_CPU1_Index_burst_mode m159 : 16|16@1+ (1,0) [0|0] "" Vector__XXX
 SG_ PCS2_DRLog_CPU1_Index_dcdc_iHv m139 : 16|16@1+ (1,0) [0|0] "" Vector__XXX
 SG_ PCS2_DRLog_CPU1_Index_dcdc_vHv m164 : 16|16@1+ (1,0) [0|0] "" Vector__XXX
 SG_ PCS2_DRLog_CPU1_Index_dcdc_vHv_bot m123 : 16|16@1+ (1,0) [0|0] "" Vector__XXX
 SG_ PCS2_DRLog_CPU1_Index_dcdc_vHv_top m126 : 16|16@1+ (1,0) [0|0] "" Vector__XXX
 SG_ PCS2_DRLog_CPU1_Index_dcdc_vLv m127 : 16|16@1+ (1,0) [0|0] "" Vector__XXX
 SG_ PCS2_DRLog_CPU1_Index_freq m136 : 16|16@1+ (1,0) [0|0] "" Vector__XXX
 SG_ PCS2_DRLog_CPU1_Index_half_bus_comp m120 : 16|16@1+ (1,0) [0|0] "" Vector__XXX
 SG_ PCS2_DRLog_CPU1_Index_half_period_pu m124 : 16|16@1+ (1,0) [0|0] "" Vector__XXX
 SG_ PCS2_DRLog_CPU1_Index_i_HV_cl_sinking m122 : 16|16@1+ (1,0) [0|0] "" Vector__XXX
 SG_ PCS2_DRLog_CPU1_Index_i_HV_cl_sourcing m121 : 16|16@1+ (1,0) [0|0] "" Vector__XXX
 SG_ PCS2_DRLog_CPU1_Index_i_HV_cmd m125 : 16|16@1+ (1,0) [0|0] "" Vector__XXX
 SG_ PCS2_DRLog_CPU1_Index_itank m128 : 16|16@1+ (1,0) [0|0] "" Vector__XXX
 SG_ PCS2_DRLog_CPU1_Index_itank_margin_fb m133 : 16|16@1+ (1,0) [0|0] "" Vector__XXX
 SG_ PCS2_DRLog_CPU1_Index_shrt_margin_fb m132 : 16|16@1+ (1,0) [0|0] "" Vector__XXX
 SG_ PCS2_DRLog_CPU1_Index_shrt_margin_ref m131 : 16|16@1+ (1,0) [0|0] "" Vector__XXX
 SG_ PCS2_DRLog_CPU1_Index_theta_HV m134 : 16|16@1+ (1,0) [0|0] "" Vector__XXX
 SG_ PCS2_DRLog_CPU1_Index_theta_LV m135 : 16|16@1+ (1,0) [0|0] "" Vector__XXX
 SG_ PCS2_DRLog_CPU1_Index_zcd_flt_cnt m129 : 16|16@1+ (1,0) [0|0] "" Vector__XXX
 SG_ PCS2_DRLog_CPU1_Index_zcd_fltd m130 : 16|16@1+ (1,0) [0|0] "" Vector__XXX
 SG_ PCS2_DRLog_CPU1_Index_zcd_rising_pu m166 : 16|16@1+ (1,0) [0|0] "" Vector__XXX
 SG_ PCS2_DRLog_CPU1_InstanceIndex m13 : 16|4@1+ (1,0) [0|0] "" Vector__XXX
 SG_ PCS2_DRLog_CPU1_SampleFrequency m11 : 16|32@1+ (1,0) [0|0] "" Vector__XXX
 SG_ PCS2_DRLog_CPU2_Index m22 : 16|16@1+ (1,0) [0|0] "" Vector__XXX
 SG_ PCS2_DRLog_CPU2_InstanceIndex m23 : 16|4@1+ (1,0) [0|0] "" Vector__XXX
 SG_ PCS2_DRLog_CPU2_SampleFrequency m21 : 16|32@1+ (1,0) [0|0] "" Vector__XXX
 SG_ PCS2_DRLog_CPU3_Index m32 : 16|16@1+ (1,0) [0|0] "" Vector__XXX
 SG_ PCS2_DRLog_CPU3_Index_18V0_LLC_Freq m157 : 16|16@1+ (1,0) [0|0] "" Vector__XXX
 SG_ PCS2_DRLog_CPU3_Index_18V0_Voltage m156 : 16|16@1+ (1,0) [0|0] "" Vector__XXX
 SG_ PCS2_DRLog_CPU3_Index_18V0_boost_duty m162 : 16|16@1+ (1,0) [0|0] "" Vector__XXX
 SG_ PCS2_DRLog_CPU3_Index_Itank_margin m144 : 16|16@1+ (1,0) [0|0] "" Vector__XXX
 SG_ PCS2_DRLog_CPU3_Index_freq m151 : 16|16@1+ (1,0) [0|0] "" Vector__XXX
 SG_ PCS2_DRLog_CPU3_Index_hvdc_current m155 : 16|16@1+ (1,0) [0|0] "" Vector__XXX
 SG_ PCS2_DRLog_CPU3_Index_i_ac_cmd_l1 m148 : 16|16@1+ (1,0) [0|0] "" Vector__XXX
 SG_ PCS2_DRLog_CPU3_Index_i_ac_cmd_l2 m149 : 16|16@1+ (1,0) [0|0] "" Vector__XXX
 SG_ PCS2_DRLog_CPU3_Index_i_ac_cmd_l3 m153 : 16|16@1+ (1,0) [0|0] "" Vector__XXX
 SG_ PCS2_DRLog_CPU3_Index_i_ac_ref_l1 m147 : 16|16@1+ (1,0) [0|0] "" Vector__XXX
 SG_ PCS2_DRLog_CPU3_Index_i_ln_l1 m142 : 16|16@1+ (1,0) [0|0] "" Vector__XXX
 SG_ PCS2_DRLog_CPU3_Index_i_ln_l2 m143 : 16|16@1+ (1,0) [0|0] "" Vector__XXX
 SG_ PCS2_DRLog_CPU3_Index_i_ln_l3 m154 : 16|16@1+ (1,0) [0|0] "" Vector__XXX
 SG_ PCS2_DRLog_CPU3_Index_itank_peak m150 : 16|16@1+ (1,0) [0|0] "" Vector__XXX
 SG_ PCS2_DRLog_CPU3_Index_pwm_enabled m145 : 16|16@1+ (1,0) [0|0] "" Vector__XXX
 SG_ PCS2_DRLog_CPU3_Index_v_dc m152 : 16|16@1+ (1,0) [0|0] "" Vector__XXX
 SG_ PCS2_DRLog_CPU3_Index_v_ln_l1 m140 : 16|16@1+ (1,0) [0|0] "" Vector__XXX
 SG_ PCS2_DRLog_CPU3_Index_v_ln_l2 m141 : 16|16@1+ (1,0) [0|0] "" Vector__XXX
 SG_ PCS2_DRLog_CPU3_Index_v_ln_l3 m146 : 16|16@1+ (1,0) [0|0] "" Vector__XXX
 SG_ PCS2_DRLog_CPU3_Index_v_ln_pre_relay_l2 m167 : 16|16@1+ (1,0) [0|0] "" Vector__XXX
 SG_ PCS2_DRLog_CPU3_Index_v_ln_pre_relay_l3 m168 : 16|16@1+ (1,0) [0|0] "" Vector__XXX
 SG_ PCS2_DRLog_CPU3_InstanceIndex m33 : 16|4@1+ (1,0) [0|0] "" Vector__XXX
 SG_ PCS2_DRLog_CPU3_SampleFrequency m31 : 16|32@1+ (1,0) [0|0] "" Vector__XXX
 SG_ PCS2_DRLog_CPU0_InstanceBufferPos m3 : 24|16@1+ (1,0) [0|0] "" Vector__XXX
 SG_ PCS2_DRLog_CPU1_InstanceBufferPos m13 : 24|16@1+ (1,0) [0|0] "" Vector__XXX
 SG_ PCS2_DRLog_CPU2_InstanceBufferPos m23 : 24|16@1+ (1,0) [0|0] "" Vector__XXX
 SG_ PCS2_DRLog_CPU3_InstanceBufferPos m33 : 24|16@1+ (1,0) [0|0] "" Vector__XXX
 SG_ PCS2_DRLog_CPU0_Sample m2 : 32|32@1- (0.001,0) [0|0] "" Vector__XXX
 SG_ PCS2_DRLog_CPU0_Sample_18V0_LLC_Freq m118 : 32|32@1- (0.001,0) [0|0] "" Vector__XXX
 SG_ PCS2_DRLog_CPU0_Sample_18V0_Voltage m117 : 32|32@1- (0.001,0) [0|0] "" Vector__XXX
 SG_ PCS2_DRLog_CPU0_Sample_18V0_boost_duty m160 : 32|32@1- (0.001,0) [0|0] "" Vector__XXX
 SG_ PCS2_DRLog_CPU0_Sample_burst_mode m158 : 32|32@1- (0.001,0) [0|0] "" Vector__XXX
 SG_ PCS2_DRLog_CPU0_Sample_channel8 m119 : 32|32@1- (0.001,0) [0|0] "" Vector__XXX
 SG_ PCS2_DRLog_CPU0_Sample_dcdc_vHv m163 : 32|32@1- (0.001,0) [0|0] "" Vector__XXX
 SG_ PCS2_DRLog_CPU0_Sample_dcdc_vHv_bot m116 : 32|32@1- (0.001,0) [0|0] "" Vector__XXX
 SG_ PCS2_DRLog_CPU0_Sample_dcdc_vHv_top m102 : 32|32@1- (0.001,0) [0|0] "" Vector__XXX
 SG_ PCS2_DRLog_CPU0_Sample_dcdc_vLv m103 : 32|32@1- (0.001,0) [0|0] "" Vector__XXX
 SG_ PCS2_DRLog_CPU0_Sample_freq m112 : 32|32@1- (0.001,0) [0|0] "" Vector__XXX
 SG_ PCS2_DRLog_CPU0_Sample_half_bus_comp m113 : 32|32@1- (0.001,0) [0|0] "" Vector__XXX
 SG_ PCS2_DRLog_CPU0_Sample_half_period_pu m100 : 32|32@1- (0.001,0) [0|0] "" Vector__XXX
 SG_ PCS2_DRLog_CPU0_Sample_i_HV_cl_sinking m115 : 32|32@1- (0.001,0) [0|0] "" Vector__XXX
 SG_ PCS2_DRLog_CPU0_Sample_i_HV_cl_sourcing m114 : 32|32@1- (0.001,0) [0|0] "" Vector__XXX
 SG_ PCS2_DRLog_CPU0_Sample_i_HV_cmd m101 : 32|32@1- (0.001,0) [0|0] "" Vector__XXX
 SG_ PCS2_DRLog_CPU0_Sample_itank m104 : 32|32@1- (0.001,0) [0|0] "" Vector__XXX
 SG_ PCS2_DRLog_CPU0_Sample_itank_margin_fb m109 : 32|32@1- (0.001,0) [0|0] "" Vector__XXX
 SG_ PCS2_DRLog_CPU0_Sample_shrt_margin_fb m108 : 32|32@1- (0.001,0) [0|0] "" Vector__XXX
 SG_ PCS2_DRLog_CPU0_Sample_shrt_margin_ref m107 : 32|32@1- (0.001,0) [0|0] "" Vector__XXX
 SG_ PCS2_DRLog_CPU0_Sample_theta_HV m110 : 32|32@1- (0.001,0) [0|0] "" Vector__XXX
 SG_ PCS2_DRLog_CPU0_Sample_theta_LV m111 : 32|32@1- (0.001,0) [0|0] "" Vector__XXX
 SG_ PCS2_DRLog_CPU0_Sample_zcd_flt_cnt m105 : 32|32@1- (0.001,0) [0|0] "" Vector__XXX
 SG_ PCS2_DRLog_CPU0_Sample_zcd_fltd m106 : 32|32@1- (0.001,0) [0|0] "" Vector__XXX
 SG_ PCS2_DRLog_CPU0_Sample_zcd_rising_pu m165 : 32|32@1- (0.001,0) [0|0] "" Vector__XXX
 SG_ PCS2_DRLog_CPU1_Sample m12 : 32|32@1- (0.001,0) [0|0] "" Vector__XXX
 SG_ PCS2_DRLog_CPU1_Sample_18V0_LLC_Freq m138 : 32|32@1- (0.001,0) [0|0] "" Vector__XXX
 SG_ PCS2_DRLog_CPU1_Sample_18V0_Voltage m137 : 32|32@1- (0.001,0) [0|0] "" Vector__XXX
 SG_ PCS2_DRLog_CPU1_Sample_18V0_boost_duty m161 : 32|32@1- (0.001,0) [0|0] "" Vector__XXX
 SG_ PCS2_DRLog_CPU1_Sample_burst_mode m159 : 32|32@1- (0.001,0) [0|0] "" Vector__XXX
 SG_ PCS2_DRLog_CPU1_Sample_dcdc_iHv m139 : 32|32@1- (0.001,0) [0|0] "" Vector__XXX
 SG_ PCS2_DRLog_CPU1_Sample_dcdc_vHv m164 : 32|32@1- (0.001,0) [0|0] "" Vector__XXX
 SG_ PCS2_DRLog_CPU1_Sample_dcdc_vHv_bot m123 : 32|32@1- (0.001,0) [0|0] "" Vector__XXX
 SG_ PCS2_DRLog_CPU1_Sample_dcdc_vHv_top m126 : 32|32@1- (0.001,0) [0|0] "" Vector__XXX
 SG_ PCS2_DRLog_CPU1_Sample_dcdc_vLv m127 : 32|32@1- (0.001,0) [0|0] "" Vector__XXX
 SG_ PCS2_DRLog_CPU1_Sample_freq m136 : 32|32@1- (0.001,0) [0|0] "" Vector__XXX
 SG_ PCS2_DRLog_CPU1_Sample_half_bus_comp m120 : 32|32@1- (0.001,0) [0|0] "" Vector__XXX
 SG_ PCS2_DRLog_CPU1_Sample_half_period_pu m124 : 32|32@1- (0.001,0) [0|0] "" Vector__XXX
 SG_ PCS2_DRLog_CPU1_Sample_i_HV_cl_sinking m122 : 32|32@1- (0.001,0) [0|0] "" Vector__XXX
 SG_ PCS2_DRLog_CPU1_Sample_i_HV_cl_sourcing m121 : 32|32@1- (0.001,0) [0|0] "" Vector__XXX
 SG_ PCS2_DRLog_CPU1_Sample_i_HV_cmd m125 : 32|32@1- (0.001,0) [0|0] "" Vector__XXX
 SG_ PCS2_DRLog_CPU1_Sample_itank m128 : 32|32@1- (0.001,0) [0|0] "" Vector__XXX
 SG_ PCS2_DRLog_CPU1_Sample_itank_margin_fb m133 : 32|32@1- (0.001,0) [0|0] "" Vector__XXX
 SG_ PCS2_DRLog_CPU1_Sample_shrt_margin_fb m132 : 32|32@1- (0.001,0) [0|0] "" Vector__XXX
 SG_ PCS2_DRLog_CPU1_Sample_shrt_margin_ref m131 : 32|32@1- (0.001,0) [0|0] "" Vector__XXX
 SG_ PCS2_DRLog_CPU1_Sample_theta_HV m134 : 32|32@1- (0.001,0) [0|0] "" Vector__XXX
 SG_ PCS2_DRLog_CPU1_Sample_theta_LV m135 : 32|32@1- (0.001,0) [0|0] "" Vector__XXX
 SG_ PCS2_DRLog_CPU1_Sample_zcd_flt_cnt m129 : 32|32@1- (0.001,0) [0|0] "" Vector__XXX
 SG_ PCS2_DRLog_CPU1_Sample_zcd_fltd m130 : 32|32@1- (0.001,0) [0|0] "" Vector__XXX
 SG_ PCS2_DRLog_CPU1_Sample_zcd_rising_pu m166 : 32|32@1- (0.001,0) [0|0] "" Vector__XXX
 SG_ PCS2_DRLog_CPU2_Sample m22 : 32|32@1- (0.001,0) [0|0] "" Vector__XXX
 SG_ PCS2_DRLog_CPU3_Sample m32 : 32|32@1- (0.001,0) [0|0] "" Vector__XXX
 SG_ PCS2_DRLog_CPU3_Sample_18V0_LLC_Freq m157 : 32|32@1- (0.001,0) [0|0] "" Vector__XXX
 SG_ PCS2_DRLog_CPU3_Sample_18V0_Voltage m156 : 32|32@1- (0.001,0) [0|0] "" Vector__XXX
 SG_ PCS2_DRLog_CPU3_Sample_18V0_boost_duty m162 : 32|32@1- (0.001,0) [0|0] "" Vector__XXX
 SG_ PCS2_DRLog_CPU3_Sample_Itank_margin m144 : 32|32@1- (0.001,0) [0|0] "" Vector__XXX
 SG_ PCS2_DRLog_CPU3_Sample_freq m151 : 32|32@1- (0.001,0) [0|0] "" Vector__XXX
 SG_ PCS2_DRLog_CPU3_Sample_hvdc_current m155 : 32|32@1- (0.001,0) [0|0] "" Vector__XXX
 SG_ PCS2_DRLog_CPU3_Sample_i_ac_cmd_l1 m148 : 32|32@1- (0.001,0) [0|0] "" Vector__XXX
 SG_ PCS2_DRLog_CPU3_Sample_i_ac_cmd_l2 m149 : 32|32@1- (0.001,0) [0|0] "" Vector__XXX
 SG_ PCS2_DRLog_CPU3_Sample_i_ac_cmd_l3 m153 : 32|32@1- (0.001,0) [0|0] "" Vector__XXX
 SG_ PCS2_DRLog_CPU3_Sample_i_ac_ref_l1 m147 : 32|32@1- (0.001,0) [0|0] "" Vector__XXX
 SG_ PCS2_DRLog_CPU3_Sample_i_ln_l1 m142 : 32|32@1- (0.001,0) [0|0] "" Vector__XXX
 SG_ PCS2_DRLog_CPU3_Sample_i_ln_l2 m143 : 32|32@1- (0.001,0) [0|0] "" Vector__XXX
 SG_ PCS2_DRLog_CPU3_Sample_i_ln_l3 m154 : 32|32@1- (0.001,0) [0|0] "" Vector__XXX
 SG_ PCS2_DRLog_CPU3_Sample_itank_peak m150 : 32|32@1- (0.001,0) [0|0] "" Vector__XXX
 SG_ PCS2_DRLog_CPU3_Sample_pwm_enabled m145 : 32|32@1- (0.001,0) [0|0] "" Vector__XXX
 SG_ PCS2_DRLog_CPU3_Sample_v_dc m152 : 32|32@1- (0.001,0) [0|0] "" Vector__XXX
 SG_ PCS2_DRLog_CPU3_Sample_v_ln_l1 m140 : 32|32@1- (0.001,0) [0|0] "" Vector__XXX
 SG_ PCS2_DRLog_CPU3_Sample_v_ln_l2 m141 : 32|32@1- (0.001,0) [0|0] "" Vector__XXX
 SG_ PCS2_DRLog_CPU3_Sample_v_ln_l3 m146 : 32|32@1- (0.001,0) [0|0] "" Vector__XXX
 SG_ PCS2_DRLog_CPU3_Sample_v_ln_pre_relay_l2 m167 : 32|32@1- (0.001,0) [0|0] "" Vector__XXX
 SG_ PCS2_DRLog_CPU3_Sample_v_ln_pre_relay_l3 m168 : 32|32@1- (0.001,0) [0|0] "" Vector__XXX
 SG_ PCS2_DRLog_CPU0_InstanceTriggerAcq m3 : 40|16@1+ (1,0) [0|0] "" Vector__XXX
 SG_ PCS2_DRLog_CPU1_InstanceTriggerAcq m13 : 40|16@1+ (1,0) [0|0] "" Vector__XXX
 SG_ PCS2_DRLog_CPU2_InstanceTriggerAcq m23 : 40|16@1+ (1,0) [0|0] "" Vector__XXX
 SG_ PCS2_DRLog_CPU3_InstanceTriggerAcq m33 : 40|16@1+ (1,0) [0|0] "" Vector__XXX
 SG_ PCS2_DRLog_CPU0_PlotId m1 : 48|8@1+ (1,0) [0|0] "" Vector__XXX
 SG_ PCS2_DRLog_CPU1_PlotId m11 : 48|8@1+ (1,0) [0|0] "" Vector__XXX
 SG_ PCS2_DRLog_CPU2_PlotId m21 : 48|8@1+ (1,0) [0|0] "" Vector__XXX
 SG_ PCS2_DRLog_CPU3_PlotId m31 : 48|8@1+ (1,0) [0|0] "" Vector__XXX

BO_ 2047 GTW_carConfig: 8 Vector__XXX
 SG_ GTW_carConfigMultiplexer M : 0|8@1+ (1,0) [0|0] "" Vector__XXX
 SG_ GTW_birthday m4 : 8|32@1+ (1,0) [0|0] "" Vector__XXX
 SG_ GTW_deliveryStatus m1 : 8|1@1+ (1,0) [0|0] "" Vector__XXX
 SG_ GTW_exteriorTrimType m2 : 8|1@1+ (1,0) [0|0] "" Vector__XXX
 SG_ GTW_gloveboxUSBType m5 : 8|2@1+ (1,0) [0|0] "" Vector__XXX
 SG_ GTW_mapRegion m3 : 8|4@1+ (1,0) [0|0] "" Vector__XXX
 SG_ GTW_rcmUndersideAbuseZThreshold m9 : 8|3@1+ (1,0) [0|0] "" Vector__XXX
 SG_ GTW_fasciaType m7 : 9|4@1+ (1,0) [0|0] "" Vector__XXX
 SG_ GTW_frontSeatHeaters m2 : 9|1@1+ (1,0) [0|0] "" Vector__XXX
 SG_ GTW_wiperMotorType m6 : 9|1@1+ (1,0) [0|0] "" Vector__XXX
 SG_ GTW_cabinPTCHeaterType m1 : 10|1@1+ (1,0) [0|0] "" Vector__XXX
 SG_ GTW_coolantPumpType m5 : 10|3@1+ (1,0) [0|0] "" Vector__XXX
 SG_ GTW_frontOverheadConsoleType m6 : 10|2@1+ (1,0) [0|0] "" Vector__XXX
 SG_ GTW_rearSeatHeaters m2 : 10|1@1+ (1,0) [0|0] "" Vector__XXX
 SG_ GTW_sohRegulatoryStatus m8 : 10|1@1+ (1,0) [0|0] "" Vector__XXX
 SG_ GTW_rcmUndersideAbuseYThreshold m9 : 11|3@1+ (1,0) [0|0] "" Vector__XXX
 SG_ GTW_rightHandDrive m1 : 11|1@1+ (1,0) [0|0] "" Vector__XXX
 SG_ GTW_eCallAntennaHW m2 : 12|1@1+ (1,0) [0|0] "" Vector__XXX
 SG_ GTW_performancePackage m3 : 12|3@1+ (1,0) [0|0] "" Vector__XXX
 SG_ GTW_rearLightType m1 : 12|2@1+ (1,0) [0|0] "" Vector__XXX
 SG_ GTW_shifterType m6 : 12|1@1+ (1,0) [0|0] "" Vector__XXX
 SG_ GTW_compressorType m6 : 13|4@1+ (1,0) [0|0] "" Vector__XXX
 SG_ GTW_epblHwType m5 : 13|4@1+ (1,0) [0|0] "" Vector__XXX
 SG_ GTW_homelinkType m2 : 13|1@1+ (1,0) [0|0] "" Vector__XXX
 SG_ GTW_powerSteeringColumn m7 : 13|1@1+ (1,0) [0|0] "" Vector__XXX
 SG_ GTW_frontSeatHeaterType m7 : 14|1@1+ (1,0) [0|0] "" Vector__XXX
 SG_ GTW_headlamps m1 : 14|2@1+ (1,0) [0|0] "" Vector__XXX
 SG_ GTW_rcmUndersideAbuseWindow m9 : 14|2@1+ (1,0) [0|0] "" Vector__XXX
 SG_ GTW_vdcType m2 : 14|1@1+ (1,0) [0|0] "" Vector__XXX
 SG_ GTW_softPerformanceLimit m7 : 15|4@1+ (1,0) [0|0] "" Vector__XXX
 SG_ GTW_country m1 : 16|16@1+ (1,0) [0|0] "" Vector__XXX
 SG_ GTW_epbrHwType m5 : 17|4@1+ (1,0) [0|0] "" Vector__XXX
 SG_ GTW_m3yBusArchitecture m8 : 17|2@1+ (1,0) [0|0] "" Vector__XXX
 SG_ GTW_memoryMirrors m2 : 17|1@1+ (1,0) [0|0] "" Vector__XXX
 SG_ GTW_twelveVBatteryType m6 : 17|3@1+ (1,0) [0|0] "" Vector__XXX
 SG_ GTW_chassisType m3 : 18|4@1+ (1,0) [0|0] "" Vector__XXX
 SG_ GTW_powerLiftgateType m2 : 18|2@1+ (1,0) [0|0] "" Vector__XXX
 SG_ GTW_efuseSWConfig m6 : 20|3@1+ (1,0) [0|0] "" Vector__XXX
 SG_ GTW_lumbarECUType m2 : 20|4@1+ (1,0) [0|0] "" Vector__XXX
 SG_ GTW_blowerMotorType m5 : 21|2@1+ (1,0) [0|0] "" Vector__XXX
 SG_ GTW_interiorUpperTrimType m8 : 21|1@1+ (1,0) [0|0] "" Vector__XXX
 SG_ GTW_airSuspension m3 : 22|2@1+ (1,0) [0|0] "" Vector__XXX
 SG_ GTW_alcoholInterlockType m7 : 22|1@1+ (1,0) [0|0] "" Vector__XXX
 SG_ GTW_blindSpotIndicatorLightType m8 : 22|2@1+ (1,0) [0|0] "" Vector__XXX
 SG_ GTW_immersiveAudio m7 : 23|2@1+ (1,0) [0|0] "" Vector__XXX
 SG_ GTW_bleEndpointUpdateMethod m6 : 24|1@1+ (1,0) [0|0] "" Vector__XXX
 SG_ GTW_centerConsoleControllerType m3 : 24|2@1+ (1,0) [0|0] "" Vector__XXX
 SG_ GTW_powerMirrorFoldType m5 : 24|1@1+ (1,0) [0|0] "" Vector__XXX
 SG_ GTW_rearSeatHeaterType m2 : 24|2@1+ (1,0) [0|0] "" Vector__XXX
 SG_ GTW_wiperMotorAsicType m8 : 24|2@1+ (1,0) [0|0] "" Vector__XXX
 SG_ GTW_headlinerMaterialType m9 : 25|2@1+ (1,0) [0|0] "" Vector__XXX
 SG_ GTW_steeringWheelControllerType m6 : 25|3@1+ (1,0) [0|0] "" Vector__XXX
 SG_ GTW_autopilotCameraType m3 : 26|1@1+ (1,0) [0|0] "" Vector__XXX
 SG_ GTW_auxParkLamps m2 : 26|2@1+ (1,0) [0|0] "" Vector__XXX
 SG_ GTW_passengerOccupancySensorType m7 : 26|3@1+ (1,0) [0|0] "" Vector__XXX
 SG_ GTW_connectivityPackage m3 : 27|1@1+ (1,0) [0|0] "" Vector__XXX
 SG_ GTW_frontUsbHubType m5 : 27|3@1+ (1,0) [0|0] "" Vector__XXX
 SG_ GTW_glareShieldHeaterType m9 : 27|1@1+ (1,0) [0|0] "" Vector__XXX
 SG_ GTW_interiorCabinRadarType m2 : 28|1@1+ (1,0) [0|0] "" Vector__XXX
 SG_ GTW_plcSupportType m3 : 28|2@1+ (1,0) [0|0] "" Vector__XXX
 SG_ GTW_gloveboxActuatorType m6 : 29|2@1+ (1,0) [0|0] "" Vector__XXX
 SG_ GTW_hvacPanelVaneType m2 : 29|1@1+ (1,0) [0|0] "" Vector__XXX
 SG_ GTW_occupancyDetectionSourceRequest m8 : 29|1@1+ (1,0) [0|0] "" Vector__XXX
 SG_ GTW_badgingVersion m3 : 30|2@1+ (1,0) [0|0] "" Vector__XXX
 SG_ GTW_intakeAirFilterType m2 : 30|2@1+ (1,0) [0|0] "" Vector__XXX
 SG_ GTW_packPerformanceDeviation m7 : 30|3@1+ (1,0) [0|0] "" Vector__XXX
 SG_ GTW_superManifoldType m5 : 30|2@1+ (1,0) [0|0] "" Vector__XXX
 SG_ GTW_rduCableType m8 : 31|1@1+ (1,0) [0|0] "" Vector__XXX
 SG_ GTW_eBuckConfig m2 : 32|1@1+ (1,0) [0|0] "" Vector__XXX
 SG_ GTW_epasType m6 : 32|4@1+ (1,0) [0|0] "" Vector__XXX
 SG_ GTW_packEnergy m3 : 32|5@1+ (1,0) [0|0] "" Vector__XXX
 SG_ GTW_parkTelltaleBehaviorType m8 : 32|1@1+ (1,0) [0|0] "" Vector__XXX
 SG_ GTW_rcmLocation m5 : 32|1@1+ (1,0) [0|0] "" Vector__XXX
 SG_ GTW_tireType m1 : 32|6@1+ (1,0) [0|0] "" Vector__XXX
 SG_ GTW_autopilotExteriorCameraType m5 : 33|1@1+ (1,0) [0|0] "" Vector__XXX
 SG_ GTW_steeringHeaterEnabled m2 : 33|1@1+ (1,0) [0|0] "" Vector__XXX
 SG_ GTW_activeHighBeam m2 : 34|1@1+ (1,0) [0|0] "" Vector__XXX
 SG_ GTW_airbagCutoffSwitch m2 : 35|1@1+ (1,0) [0|0] "" Vector__XXX
 SG_ GTW_frontFogLamps m7 : 35|1@1+ (1,0) [0|0] "" Vector__XXX
 SG_ GTW_interiorCamBeautyCoverType m5 : 35|2@1+ (1,0) [0|0] "" Vector__XXX
 SG_ GTW_homologationRegionOverride m6 : 36|2@1+ (1,0) [0|0] "" Vector__XXX
 SG_ GTW_intrusionSensorType m2 : 36|1@1+ (1,0) [0|0] "" Vector__XXX
 SG_ GTW_audioType m7 : 37|3@1+ (1,0) [0|0] "" Vector__XXX
 SG_ GTW_frontSeatReclinerHardware m3 : 37|2@1+ (1,0) [0|0] "" Vector__XXX
 SG_ GTW_spoilerType m2 : 37|1@1+ (1,0) [0|0] "" Vector__XXX
 SG_ GTW_hornType m5 : 38|1@1+ (1,0) [0|0] "" Vector__XXX
 SG_ GTW_roofGlassType m1 : 38|2@1+ (1,0) [0|0] "" Vector__XXX
 SG_ GTW_windowCommandsPermissionType m6 : 38|2@1+ (1,0) [0|0] "" Vector__XXX
 SG_ GTW_brakeLineSwitchType m3 : 39|1@1+ (1,0) [0|0] "" Vector__XXX
 SG_ GTW_interiorCameraType m8 : 39|2@1+ (1,0) [0|0] "" Vector__XXX
 SG_ GTW_rearFogLamps m2 : 39|1@1+ (1,0) [0|0] "" Vector__XXX
 SG_ GTW_dasHw m1 : 40|3@1+ (1,0) [0|0] "" Vector__XXX
 SG_ GTW_eCallEnabled m4 : 40|2@1+ (1,0) [0|0] "" Vector__XXX
 SG_ GTW_espValveType m3 : 40|2@1+ (1,0) [0|0] "" Vector__XXX
 SG_ GTW_mRecordVersion m9 : 40|1@1+ (1,0) [0|0] "" Vector__XXX
 SG_ GTW_roofType m2 : 40|1@1+ (1,0) [0|0] "" Vector__XXX
 SG_ GTW_frontFasciaCameraType m8 : 41|2@1+ (1,0) [0|0] "" Vector__XXX
 SG_ GTW_thirdRowSeatType m2 : 41|1@1+ (1,0) [0|0] "" Vector__XXX
 SG_ GTW_autopilot m2 : 42|3@1+ (1,0) [0|0] "" Vector__XXX
 SG_ GTW_headlightStepperStallDetectMode m6 : 42|1@1+ (1,0) [0|0] "" Vector__XXX
 SG_ GTW_occupancyClassificationFeatureType m7 : 42|1@1+ (1,0) [0|0] "" Vector__XXX
 SG_ GTW_parkAssistECUType m4 : 42|2@1+ (1,0) [0|0] "" Vector__XXX
 SG_ GTW_softRange m3 : 42|3@1+ (1,0) [0|0] "" Vector__XXX
 SG_ GTW_steeringColumnMotorType m5 : 42|2@1+ (1,0) [0|0] "" Vector__XXX
 SG_ GTW_brakeHWType m1 : 43|5@1+ (1,0) [0|0] "" Vector__XXX
 SG_ GTW_rgbInteriorLightingEnabled m6 : 43|2@1+ (1,0) [0|0] "" Vector__XXX
 SG_ GTW_passengerAirbagType m4 : 44|2@1+ (1,0) [0|0] "" Vector__XXX
 SG_ GTW_interiorCamFanType m8 : 45|3@1+ (1,0) [0|0] "" Vector__XXX
 SG_ GTW_refrigerantType m3 : 45|2@1+ (1,0) [0|0] "" Vector__XXX
 SG_ GTW_superchargingAccess m2 : 45|2@1+ (1,0) [0|0] "" Vector__XXX
 SG_ GTW_windshieldWiperHeaterType m6 : 45|1@1+ (1,0) [0|0] "" Vector__XXX
 SG_ GTW_forwardRadarHw m4 : 46|2@1+ (1,0) [0|0] "" Vector__XXX
 SG_ GTW_frontControllerArchitectureType m7 : 46|1@1+ (1,0) [0|0] "" Vector__XXX
 SG_ GTW_driveInterfaceType m6 : 47|1@1+ (1,0) [0|0] "" Vector__XXX
 SG_ GTW_exteriorColor m2 : 48|5@1+ (1,0) [0|0] "" Vector__XXX
 SG_ GTW_frontSeatType m4 : 48|4@1+ (1,0) [0|0] "" Vector__XXX
 SG_ GTW_refrigACLineType m5 : 48|2@1+ (1,0) [0|0] "" Vector__XXX
 SG_ GTW_restraintsHardwareType m1 : 48|8@1+ (1,0) [0|0] "" Vector__XXX
 SG_ GTW_wheelType m3 : 48|7@1+ (1,0) [0|0] "" Vector__XXX
 SG_ GTW_efficiencyPackage m6 : 49|6@1+ (1,0) [0|0] "" Vector__XXX
 SG_ GTW_tpmsType m7 : 49|2@1+ (1,0) [0|0] "" Vector__XXX
 SG_ GTW_refrigFilterType m5 : 50|2@1+ (1,0) [0|0] "" Vector__XXX
 SG_ GTW_authenticationEndpointLayout m7 : 52|3@1+ (1,0) [0|0] "" Vector__XXX
 SG_ GTW_diBurnInType m5 : 52|1@1+ (1,0) [0|0] "" Vector__XXX
 SG_ GTW_pedestrianWarningSound m2 : 53|2@1+ (1,0) [0|0] "" Vector__XXX
 SG_ GTW_specialBadgingType m5 : 53|2@1+ (1,0) [0|0] "" Vector__XXX
 SG_ GTW_wirelessPhoneChargerType m4 : 53|2@1+ (1,0) [0|0] "" Vector__XXX
 SG_ GTW_chassisSubType m5 : 55|2@1+ (1,0) [0|0] "" Vector__XXX
 SG_ GTW_ethernetTunerType m4 : 55|2@1+ (1,0) [0|0] "" Vector__XXX
 SG_ GTW_steeringColumnUJointType m2 : 55|1@1+ (1,0) [0|0] "" Vector__XXX
 SG_ GTW_visorLightType m6 : 55|1@1+ (1,0) [0|0] "" Vector__XXX
 SG_ GTW_bPillarNFCParam m2 : 56|1@1+ (1,0) [0|0] "" Vector__XXX
 SG_ GTW_drivetrainType m1 : 56|4@1+ (1,0) [0|0] "" Vector__XXX
 SG_ GTW_brakeActuationType m3 : 57|3@1+ (1,0) [0|0] "" Vector__XXX
 SG_ GTW_frontSeatVentilationType m5 : 57|1@1+ (1,0) [0|0] "" Vector__XXX
 SG_ GTW_interiorLighting m2 : 57|3@1+ (1,0) [0|0] "" Vector__XXX
 SG_ GTW_socSleepOverride m7 : 57|2@1+ (1,0) [0|0] "" Vector__XXX
 SG_ GTW_gnssAntennaType m6 : 58|2@1+ (1,0) [0|0] "" Vector__XXX
 SG_ GTW_towPackage m5 : 58|2@1+ (1,0) [0|0] "" Vector__XXX
 SG_ GTW_r79BehaviorOverride m7 : 59|1@1+ (1,0) [0|0] "" Vector__XXX
 SG_ GTW_headlightLevelerType m2 : 60|2@1+ (1,0) [0|0] "" Vector__XXX
 SG_ GTW_interiorTrimType m4 : 60|4@1+ (1,0) [0|0] "" Vector__XXX
 SG_ GTW_radarHeaterType m1 : 60|3@1+ (1,0) [0|0] "" Vector__XXX
 SG_ GTW_repeaterAeroRibType m8 : 60|3@1+ (1,0) [0|0] "" Vector__XXX
 SG_ GTW_secondRowSeatType m3 : 60|3@1+ (1,0) [0|0] "" Vector__XXX
 SG_ GTW_steeringHeaterType m7 : 60|3@1+ (1,0) [0|0] "" Vector__XXX
 SG_ GTW_restraintControlsType m5 : 61|1@1+ (1,0) [0|0] "" Vector__XXX
 SG_ GTW_caliperColorType m5 : 62|2@1+ (1,0) [0|0] "" Vector__XXX
 SG_ GTW_frontSeatHeatersEnabled m6 : 62|1@1+ (1,0) [0|0] "" Vector__XXX
 SG_ GTW_numberHVILNodes m2 : 62|2@1+ (1,0) [0|0] "" Vector__XXX
 SG_ GTW_narrowWipingSupported m7 : 63|1@1+ (1,0) [0|0] "" Vector__XXX
 SG_ GTW_windshieldWiperHeaterEnabled m6 : 63|1@1+ (1,0) [0|0] "" Vector__XXX
